VERSION ""

NS_ :

BS_:

BU_: Vector__XXX

BO_ 2566759934 DC2: 8 Vector__XXX
SG_ LockStatusOfDoor1 : 0|2@1+ (1,0) [0|3] "" Vector__XXX
SG_ OpenStatusOfDoor1 : 2|2@1+ (1,0) [0|3] "" Vector__XXX
SG_ EnableStatusOfDoor1 : 4|2@1+ (1,0) [0|3] "" Vector__XXX
SG_ LockStatusOfDoor2 : 6|2@1+ (1,0) [0|3] "" Vector__XXX
SG_ OpenStatusOfDoor2 : 8|2@1+ (1,0) [0|3] "" Vector__XXX
SG_ EnableStatusOfDoor2 : 10|2@1+ (1,0) [0|3] "" Vector__XXX
SG_ LockStatusOfDoor3 : 12|2@1+ (1,0) [0|3] "" Vector__XXX
SG_ OpenStatusOfDoor3 : 14|2@1+ (1,0) [0|3] "" Vector__XXX
SG_ EnableStatusOfDoor3 : 16|2@1+ (1,0) [0|3] "" Vector__XXX
SG_ LockStatusOfDoor4 : 18|2@1+ (1,0) [0|3] "" Vector__XXX
SG_ OpenStatusOfDoor4 : 20|2@1+ (1,0) [0|3] "" Vector__XXX
SG_ EnableStatusOfDoor4 : 22|2@1+ (1,0) [0|3] "" Vector__XXX
SG_ LockStatusOfDoor5 : 24|2@1+ (1,0) [0|3] "" Vector__XXX
SG_ OpenStatusOfDoor5 : 26|2@1+ (1,0) [0|3] "" Vector__XXX
SG_ EnableStatusOfDoor5 : 28|2@1+ (1,0) [0|3] "" Vector__XXX
SG_ LockStatusOfDoor6 : 30|2@1+ (1,0) [0|3] "" Vector__XXX
SG_ OpenStatusOfDoor6 : 32|2@1+ (1,0) [0|3] "" Vector__XXX
SG_ EnableStatusOfDoor6 : 34|2@1+ (1,0) [0|3] "" Vector__XXX
SG_ LockStatusOfDoor7 : 36|2@1+ (1,0) [0|3] "" Vector__XXX
SG_ OpenStatusOfDoor7 : 38|2@1+ (1,0) [0|3] "" Vector__XXX
SG_ EnableStatusOfDoor7 : 40|2@1+ (1,0) [0|3] "" Vector__XXX
SG_ LockStatusOfDoor8 : 42|2@1+ (1,0) [0|3] "" Vector__XXX
SG_ OpenStatusOfDoor8 : 44|2@1+ (1,0) [0|3] "" Vector__XXX
SG_ EnableStatusOfDoor8 : 46|2@1+ (1,0) [0|3] "" Vector__XXX
SG_ LockStatusOfDoor9 : 48|2@1+ (1,0) [0|3] "" Vector__XXX
SG_ OpenStatusOfDoor9 : 50|2@1+ (1,0) [0|3] "" Vector__XXX
SG_ EnableStatusOfDoor9 : 52|2@1+ (1,0) [0|3] "" Vector__XXX
SG_ LockStatusOfDoor10 : 54|2@1+ (1,0) [0|3] "" Vector__XXX
SG_ OpenStatusOfDoor10 : 56|2@1+ (1,0) [0|3] "" Vector__XXX
SG_ EnableStatusOfDoor10 : 58|2@1+ (1,0) [0|3] "" Vector__XXX

BO_ 2365433598 VREP: 8 Vector__XXX
SG_ GeneratorExcitationFieldVoltage : 0|16@1+ (0.05,-1606) [-1606|1606.75] "V" Vector__XXX
SG_ GeneratorExcitationFieldCurrent : 16|16@1+ (0.05,0) [0|3212.75] "A" Vector__XXX
SG_ GenOutputVoltageBiasPercentage : 32|16@1+ (0.1,-100) [-100|100] "%" Vector__XXX

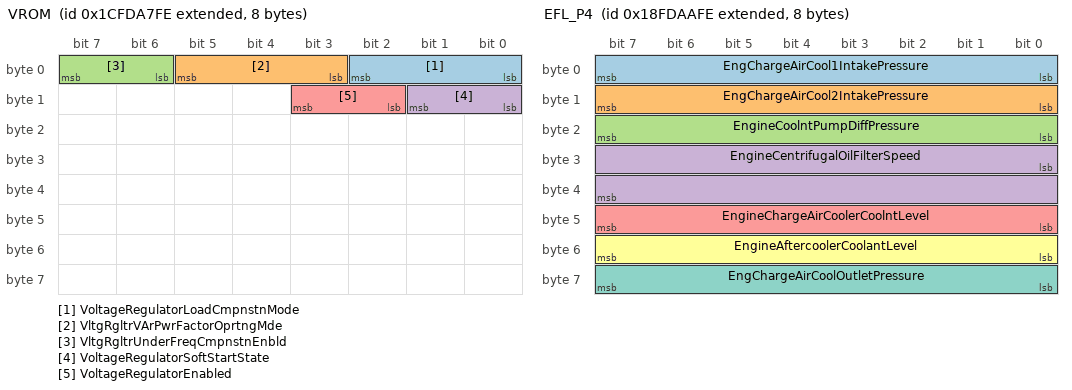
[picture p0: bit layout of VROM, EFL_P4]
BO_ 2633869310 VROM: 8 Vector__XXX
SG_ VoltageRegulatorLoadCmpnstnMode : 0|3@1+ (1,0) [0|7] "" Vector__XXX
SG_ VltgRgltrVArPwrFactorOprtngMde : 3|3@1+ (1,0) [0|7] "" Vector__XXX
SG_ VltgRgltrUnderFreqCmpnstnEnbld : 6|2@1+ (1,0) [0|3] "" Vector__XXX
SG_ VoltageRegulatorSoftStartState : 8|2@1+ (1,0) [0|3] "" Vector__XXX
SG_ VoltageRegulatorEnabled : 10|2@1+ (1,0) [0|3] "" Vector__XXX

BO_ 2566760702 WCM2: 8 Vector__XXX
SG_ NetworkTransceiverStatus2 : 0|8@1+ (1,0) [0|255] "" Vector__XXX
SG_ NetworkServiceStatus2 : 8|8@1+ (1,0) [0|255] "" Vector__XXX
SG_ NetworkAntennaStatus2 : 16|8@1+ (1,0) [0|255] "" Vector__XXX
SG_ NetworkSignalStrength2 : 24|8@1+ (0.4,0) [0|100] "%" Vector__XXX
SG_ WirelessCommNetworkType2 : 32|8@1+ (1,0) [0|255] "" Vector__XXX

BO_ 2566760958 WCM1: 8 Vector__XXX
SG_ NetworkTransceiverStatus1 : 0|8@1+ (1,0) [0|255] "" Vector__XXX
SG_ NetworkServiceStatus1 : 8|8@1+ (1,0) [0|255] "" Vector__XXX
SG_ NetworkAntennaStatus1 : 16|8@1+ (1,0) [0|255] "" Vector__XXX
SG_ NetworkSignalStrength1 : 24|8@1+ (0.4,0) [0|100] "%" Vector__XXX
SG_ WirelessCommNetworkType1 : 32|8@1+ (1,0) [0|255] "" Vector__XXX

BO_ 2566761214 EFL_P4: 8 Vector__XXX
SG_ EngChargeAirCool1IntakePressure : 0|8@1+ (2,0) [0|500] "kPa" Vector__XXX
SG_ EngChargeAirCool2IntakePressure : 8|8@1+ (2,0) [0|500] "kPa" Vector__XXX
SG_ EngineCoolntPumpDiffPressure : 16|8@1+ (1.64,-7) [-7|403] "kPa" Vector__XXX
SG_ EngineCentrifugalOilFilterSpeed : 24|16@1+ (4,0) [0|257020] "rpm" Vector__XXX
SG_ EngineChargeAirCoolerCoolntLevel : 40|8@1+ (0.4,0) [0|100] "%" Vector__XXX
SG_ EngineAftercoolerCoolantLevel : 48|8@1+ (0.4,0) [0|100] "%" Vector__XXX
SG_ EngChargeAirCoolOutletPressure : 56|8@1+ (2,0) [0|500] "kPa" Vector__XXX

BO_ 2566761726 EFI: 8 Vector__XXX
SG_ NoFuelCnsmptnMontingTransducers : 0|8@1+ (1,0) [0|250] "" Vector__XXX
SG_ EngineIdleFuelFlowRateThreshold : 8|32@1+ (0.001,0) [0|4211081.215] "l/h" Vector__XXX

BO_ 2566761982 RCMS: 8 Vector__XXX
SG_ MessageSelectionControl : 0|8@1+ (1,0) [0|250] "" Vector__XXX
SG_ PGNOfConfigurableMessageDesired : 8|24@1+ (1,0) [0|16777215] "" Vector__XXX

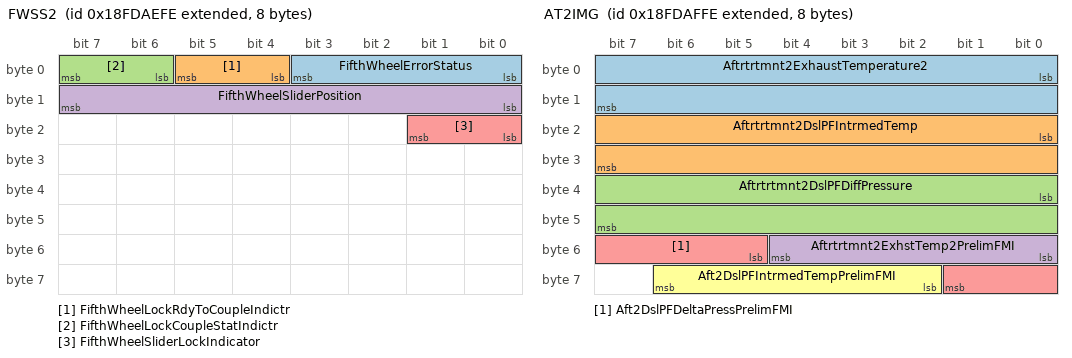
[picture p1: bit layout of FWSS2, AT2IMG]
BO_ 2566762238 FWSS2: 8 Vector__XXX
SG_ FifthWheelErrorStatus : 0|4@1+ (1,0) [0|15] "" Vector__XXX
SG_ FifthWheelLockRdyToCoupleIndictr : 4|2@1+ (1,0) [0|3] "" Vector__XXX
SG_ FifthWheelLockCoupleStatIndictr : 6|2@1+ (1,0) [0|3] "" Vector__XXX
SG_ FifthWheelSliderPosition : 8|8@1+ (10,0) [0|2500] "mm" Vector__XXX
SG_ FifthWheelSliderLockIndicator : 16|2@1+ (1,0) [0|3] "" Vector__XXX

BO_ 2566762494 AT2IMG: 8 Vector__XXX
SG_ Aftrtrtmnt2ExhaustTemperature2 : 0|16@1+ (0.03125,-273) [-273|1734.96875] "deg C" Vector__XXX
SG_ Aftrtrtmnt2DslPFIntrmedTemp : 16|16@1+ (0.03125,-273) [-273|1734.96875] "deg C" Vector__XXX
SG_ Aftrtrtmnt2DslPFDiffPressure : 32|16@1+ (0.1,0) [0|6425.5] "kPa" Vector__XXX
SG_ Aftrtrtmnt2ExhstTemp2PrelimFMI : 48|5@1+ (1,0) [0|31] "" Vector__XXX
SG_ Aft2DslPFDeltaPressPrelimFMI : 53|5@1+ (1,0) [0|31] "" Vector__XXX
SG_ Aft2DslPFIntrmedTempPrelimFMI : 58|5@1+ (1,0) [0|31] "" Vector__XXX

BO_ 2566762750 AT2OG2: 8 Vector__XXX
SG_ Aftrtrtmnt2ExhaustTemperature3 : 0|16@1+ (0.03125,-273) [-273|1734.96875] "deg C" Vector__XXX
SG_ Aftrtrtmnt2DslPFOtltTemperature : 16|16@1+ (0.03125,-273) [-273|1734.96875] "deg C" Vector__XXX
SG_ Aftrtrtmnt2ExhstTemp3PrelimFMI : 32|5@1+ (1,0) [0|31] "" Vector__XXX
SG_ Aft2DslPFExhstTempPrelimFMI : 40|5@1+ (1,0) [0|31] "" Vector__XXX

BO_ 2566763006 AT2IG2: 8 Vector__XXX
SG_ Aftrtrtmnt2ExhaustTemperature1 : 0|16@1+ (0.03125,-273) [-273|1734.96875] "deg C" Vector__XXX
SG_ Aftrtrtmnt2DslPFIntkTemperature : 16|16@1+ (0.03125,-273) [-273|1734.96875] "deg C" Vector__XXX
SG_ Aftrtrtmnt2ExhstTemp1PrelimFMI : 32|5@1+ (1,0) [0|31] "" Vector__XXX
SG_ Aft2DslPFIntkTempPrelimFMI : 40|5@1+ (1,0) [0|31] "" Vector__XXX

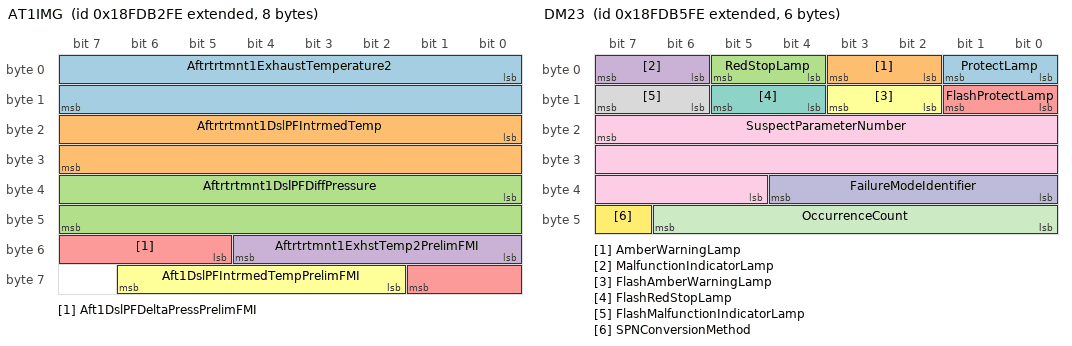
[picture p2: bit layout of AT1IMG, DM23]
BO_ 2566763262 AT1IMG: 8 Vector__XXX
SG_ Aftrtrtmnt1ExhaustTemperature2 : 0|16@1+ (0.03125,-273) [-273|1734.96875] "deg C" Vector__XXX
SG_ Aftrtrtmnt1DslPFIntrmedTemp : 16|16@1+ (0.03125,-273) [-273|1734.96875] "deg C" Vector__XXX
SG_ Aftrtrtmnt1DslPFDiffPressure : 32|16@1+ (0.1,0) [0|6425.5] "kPa" Vector__XXX
SG_ Aftrtrtmnt1ExhstTemp2PrelimFMI : 48|5@1+ (1,0) [0|31] "" Vector__XXX
SG_ Aft1DslPFDeltaPressPrelimFMI : 53|5@1+ (1,0) [0|31] "" Vector__XXX
SG_ Aft1DslPFIntrmedTempPrelimFMI : 58|5@1+ (1,0) [0|31] "" Vector__XXX

BO_ 2566763518 AT1OG2: 8 Vector__XXX
SG_ Aftrtrtmnt1ExhaustTemperature3 : 0|16@1+ (0.03125,-273) [-273|1734.96875] "deg C" Vector__XXX
SG_ Aftrtrtmnt1DslPFOtltTemperature : 16|16@1+ (0.03125,-273) [-273|1734.96875] "deg C" Vector__XXX
SG_ Aftrtrtmnt1ExhstTemp3PrelimFMI : 32|5@1+ (1,0) [0|31] "" Vector__XXX
SG_ Aft1DslPFOtltExhstTempPrelimFMI : 40|5@1+ (1,0) [0|31] "" Vector__XXX

BO_ 2566763774 AT1IG2: 8 Vector__XXX
SG_ Aftrtrtmnt1ExhaustTemperature1 : 0|16@1+ (0.03125,-273) [-273|1734.96875] "deg C" Vector__XXX
SG_ Aftrtrtmnt1DslPFIntkTemperature : 16|16@1+ (0.03125,-273) [-273|1734.96875] "deg C" Vector__XXX
SG_ Aftrtrtmnt1ExhstTemp1PrelimFMI : 32|5@1+ (1,0) [0|31] "" Vector__XXX
SG_ Aft1DslPFIntkTempPrelimFMI : 40|5@1+ (1,0) [0|31] "" Vector__XXX

BO_ 2566764030 DM23: 6 Vector__XXX
SG_ ProtectLamp : 0|2@1+ (1,0) [0|3] "" Vector__XXX
SG_ AmberWarningLamp : 2|2@1+ (1,0) [0|3] "" Vector__XXX
SG_ RedStopLamp : 4|2@1+ (1,0) [0|3] "" Vector__XXX
SG_ MalfunctionIndicatorLamp : 6|2@1+ (1,0) [0|3] "" Vector__XXX
SG_ FlashProtectLamp : 8|2@1+ (1,0) [0|3] "" Vector__XXX
SG_ FlashAmberWarningLamp : 10|2@1+ (1,0) [0|3] "" Vector__XXX
SG_ FlashRedStopLamp : 12|2@1+ (1,0) [0|3] "" Vector__XXX
SG_ FlashMalfunctionIndicatorLamp : 14|2@1+ (1,0) [0|3] "" Vector__XXX
SG_ SuspectParameterNumber : 23|19@0+ (1,0) [0|524287] "" Vector__XXX
SG_ FailureModeIdentifier : 32|5@1+ (1,0) [0|31] "" Vector__XXX
SG_ OccurrenceCount : 40|7@1+ (1,0) [0|127] "" Vector__XXX
SG_ SPNConversionMethod : 47|1@1+ (1,0) [0|1] "" Vector__XXX

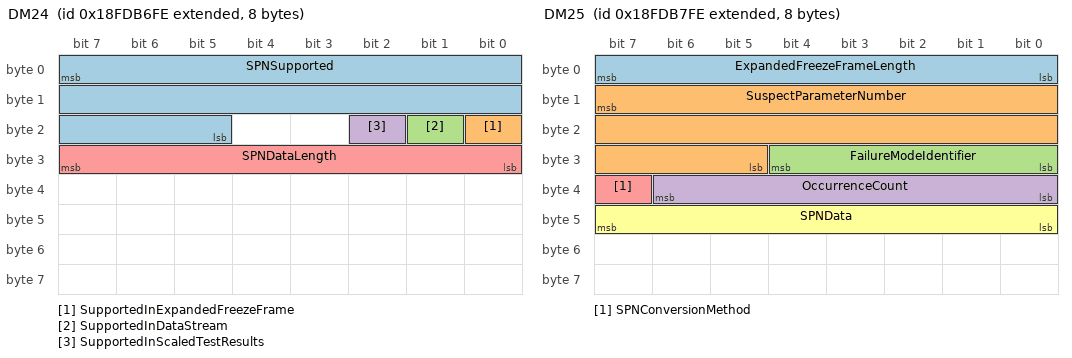
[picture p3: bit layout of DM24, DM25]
BO_ 2566764286 DM24: 8 Vector__XXX
SG_ SPNSupported : 7|19@0+ (1,0) [0|524287] "" Vector__XXX
SG_ SupportedInExpandedFreezeFrame : 16|1@1+ (1,0) [0|1] "" Vector__XXX
SG_ SupportedInDataStream : 17|1@1+ (1,0) [0|1] "" Vector__XXX
SG_ SupportedInScaledTestResults : 18|1@1+ (1,0) [0|1] "" Vector__XXX
SG_ SPNDataLength : 24|8@1+ (1,0) [0|250] "" Vector__XXX

BO_ 2566764542 DM25: 8 Vector__XXX
SG_ ExpandedFreezeFrameLength : 0|8@1+ (1,0) [0|255] "" Vector__XXX
SG_ SuspectParameterNumber : 15|19@0+ (1,0) [0|524287] "" Vector__XXX
SG_ FailureModeIdentifier : 24|5@1+ (1,0) [0|31] "" Vector__XXX
SG_ OccurrenceCount : 32|7@1+ (1,0) [0|127] "" Vector__XXX
SG_ SPNConversionMethod : 39|1@1+ (1,0) [0|1] "" Vector__XXX
SG_ SPNData : 40|8@1+ (1,0) [0|255] "" Vector__XXX

BO_ 2566764798 DM26: 8 Vector__XXX
SG_ TimeSinceEngineStart : 0|16@1+ (1,0) [0|64255] "s" Vector__XXX
SG_ NoWarmUpsSncDiagTroubleCodesClrd : 16|8@1+ (1,0) [0|250] "" Vector__XXX
SG_ CntinlyMontrdSysEnbldCmpltdStat : 24|8@1+ (1,0) [0|255] "" Vector__XXX
SG_ NonCntinlyMontrdSystemsEnbldStat : 32|16@1+ (1,0) [0|65535] "" Vector__XXX
SG_ NonCntinlyMontrdSysCompleteStat : 48|16@1+ (1,0) [0|65535] "" Vector__XXX

BO_ 2566765054 TPRI: 8 Vector__XXX
SG_ TireLocation : 0|8@1+ (1,0) [0|255] "" Vector__XXX
SG_ ReferenceTirePressure : 8|8@1+ (8,0) [0|2000] "kPa" Vector__XXX

BO_ 2566765310 TR6: 8 Vector__XXX
SG_ FareboxEmergencyStatus : 0|2@1+ (1,0) [0|3] "" Vector__XXX
SG_ FareboxAlarmIdentifier : 8|7@1+ (1,0) [0|127] "" Vector__XXX

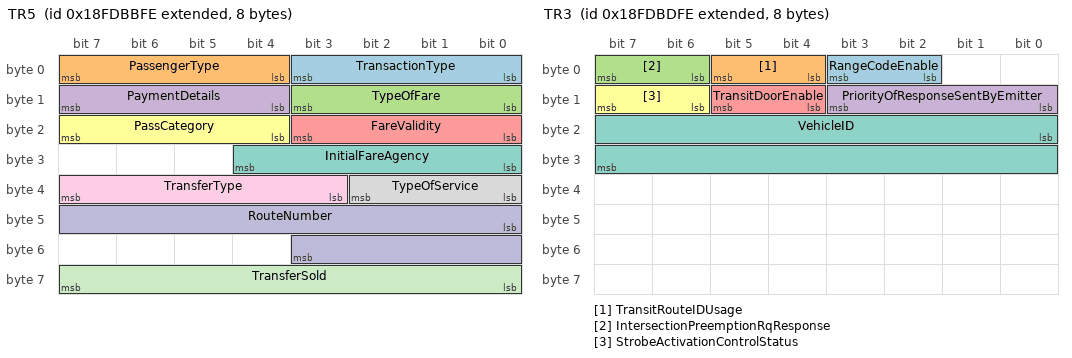
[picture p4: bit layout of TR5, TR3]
BO_ 2566765566 TR5: 8 Vector__XXX
SG_ TransactionType : 0|4@1+ (1,0) [0|15] "" Vector__XXX
SG_ PassengerType : 4|4@1+ (1,0) [0|15] "" Vector__XXX
SG_ TypeOfFare : 8|4@1+ (1,0) [0|15] "" Vector__XXX
SG_ PaymentDetails : 12|4@1+ (1,0) [0|15] "" Vector__XXX
SG_ FareValidity : 16|4@1+ (1,0) [0|15] "" Vector__XXX
SG_ PassCategory : 20|4@1+ (1,0) [0|15] "" Vector__XXX
SG_ InitialFareAgency : 24|5@1+ (1,0) [0|31] "" Vector__XXX
SG_ TypeOfService : 32|3@1+ (1,0) [0|7] "" Vector__XXX
SG_ TransferType : 35|5@1+ (1,0) [0|31] "" Vector__XXX
SG_ RouteNumber : 40|12@1+ (1,0) [0|4095] "" Vector__XXX
SG_ TransferSold : 56|8@1+ (1,0) [0|255] "" Vector__XXX

BO_ 2566765822 TR4: 15 Vector__XXX
SG_ FareboxServiceStatus : 0|2@1+ (1,0) [0|3] "" Vector__XXX
SG_ TripStatus : 2|3@1+ (1,0) [0|7] "" Vector__XXX
SG_ TripDirection : 8|4@1+ (1,0) [0|15] "" Vector__XXX
SG_ FarePresets : 16|8@1+ (1,0) [0|255] "" Vector__XXX
SG_ TripNumber : 24|16@1+ (1,0) [0|65535] "" Vector__XXX
SG_ PatternNumber : 40|16@1+ (1,0) [0|65535] "" Vector__XXX
SG_ AssignedRoute : 56|16@1+ (1,0) [0|65535] "" Vector__XXX
SG_ AssignedRun : 72|16@1+ (1,0) [0|65535] "" Vector__XXX
SG_ AssignedBlock : 88|16@1+ (1,0) [0|65535] "" Vector__XXX
SG_ DriversFareboxSecurityCode : 104|16@1+ (1,0) [0|65535] "" Vector__XXX

BO_ 2566766078 TR3: 8 Vector__XXX
SG_ RangeCodeEnable : 2|2@1+ (1,0) [0|3] "" Vector__XXX
SG_ TransitRouteIDUsage : 4|2@1+ (1,0) [0|3] "" Vector__XXX
SG_ IntersectionPreemptionRqResponse : 6|2@1+ (1,0) [0|3] "" Vector__XXX
SG_ PriorityOfResponseSentByEmitter : 8|4@1+ (1,0) [0|15] "" Vector__XXX
SG_ TransitDoorEnable : 12|2@1+ (1,0) [0|3] "" Vector__XXX
SG_ StrobeActivationControlStatus : 14|2@1+ (1,0) [0|3] "" Vector__XXX
SG_ VehicleID : 16|16@1+ (1,0) [0|65535] "" Vector__XXX

BO_ 2566766334 TR1: 8 Vector__XXX
SG_ Agency : 0|8@1+ (1,0) [0|255] "" Vector__XXX
SG_ NoOfBytsInTrnstAssgndRteIdntty : 8|8@1+ (1,0) [0|250] "Bytes" Vector__XXX
SG_ NoOfBytsInTrnstAssgndRunIdntty : 16|8@1+ (1,0) [0|250] "Bytes" Vector__XXX
SG_ NoOfBytsInTrnstAssgndBlckIdntty : 24|8@1+ (1,0) [0|250] "Bytes" Vector__XXX

BO_ 2566766590 TR2: 100 Vector__XXX
SG_ NoOfBytsInMilePstIdentification : 0|8@1+ (1,0) [0|250] "Bytes" Vector__XXX
SG_ MilepostIdentification : 7|800@0+ (1,0) [0|0] "ASCII" Vector__XXX

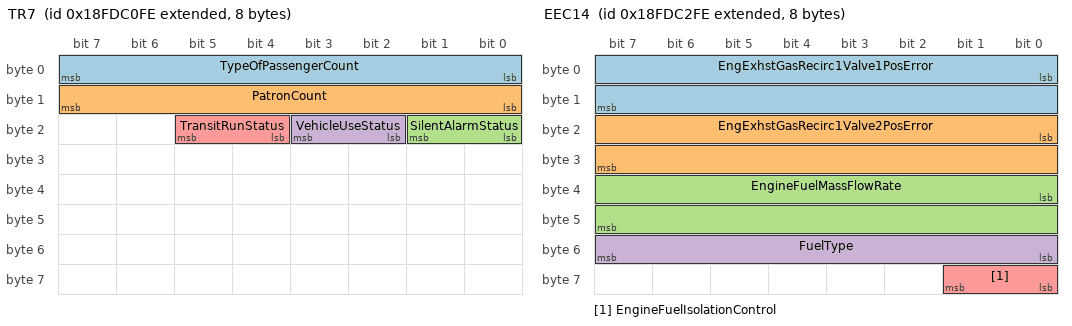
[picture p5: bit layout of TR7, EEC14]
BO_ 2566766846 TR7: 8 Vector__XXX
SG_ TypeOfPassengerCount : 0|8@1+ (1,0) [0|255] "" Vector__XXX
SG_ PatronCount : 8|8@1+ (1,0) [0|250] "" Vector__XXX
SG_ SilentAlarmStatus : 16|2@1+ (1,0) [0|3] "" Vector__XXX
SG_ VehicleUseStatus : 18|2@1+ (1,0) [0|3] "" Vector__XXX
SG_ TransitRunStatus : 20|2@1+ (1,0) [0|3] "" Vector__XXX

BO_ 2566767102 EFL_P3: 8 Vector__XXX
SG_ EngIntkValveActSystemOilPressure : 0|16@1+ (0.00390625,0) [0|250.996] "MPa" Vector__XXX
SG_ EngExhstGasRecirc1IntkPress : 16|8@1+ (2,0) [0|500] "kPa" Vector__XXX
SG_ EngExhstValveActSystemOilPress : 24|16@1+ (0.00390625,0) [0|250.996] "MPa" Vector__XXX
SG_ EngExhstGasRecirc1OtltPress : 40|8@1+ (2,0) [0|500] "kPa" Vector__XXX
SG_ EngineThrottleValve1DiffPressure : 48|16@1+ (0.1,0) [0|6425.5] "kPa" Vector__XXX

BO_ 2566767358 EEC14: 8 Vector__XXX
SG_ EngExhstGasRecirc1Valve1PosError : 0|16@1+ (0.004,-125) [-125|132.02] "%" Vector__XXX
SG_ EngExhstGasRecirc1Valve2PosError : 16|16@1+ (0.004,-125) [-125|132.02] "%" Vector__XXX
SG_ EngineFuelMassFlowRate : 32|16@1+ (0.005,0) [0|321.275] "g/s" Vector__XXX
SG_ FuelType : 48|8@1+ (1,0) [0|255] "" Vector__XXX
SG_ EngineFuelIsolationControl : 56|2@1+ (1,0) [0|3] "" Vector__XXX

BO_ 2566767614 EEC15: 8 Vector__XXX
SG_ AcceleratorPedal1Channel2 : 0|8@1+ (0.4,0) [0|100] "%" Vector__XXX
SG_ AcceleratorPedal1Channel3 : 8|8@1+ (0.4,0) [0|100] "%" Vector__XXX
SG_ AcceleratorPedal2Channel2 : 16|8@1+ (0.4,0) [0|100] "%" Vector__XXX
SG_ AcceleratorPedal2Channel3 : 24|8@1+ (0.4,0) [0|100] "%" Vector__XXX
SG_ EngExhstGasRestrictionValveCtrl : 32|16@1+ (0.0025,0) [0|160.6375] "%" Vector__XXX

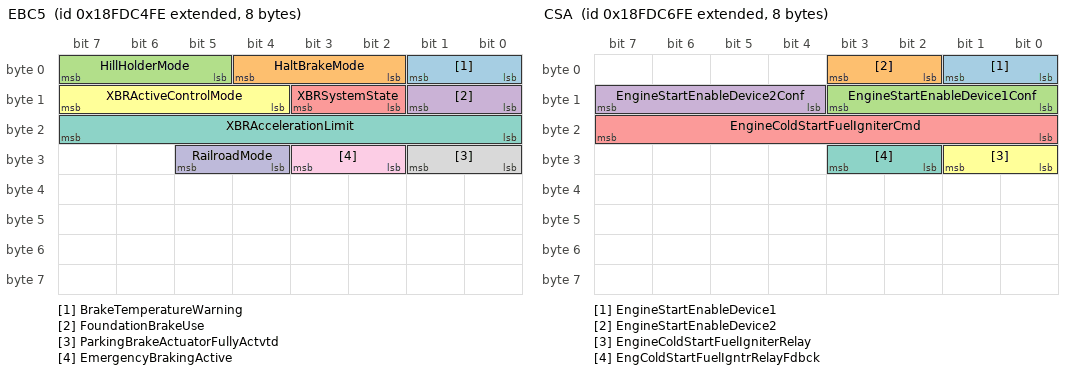
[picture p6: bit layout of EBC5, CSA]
BO_ 2566767870 EBC5: 8 Vector__XXX
SG_ BrakeTemperatureWarning : 0|2@1+ (1,0) [0|3] "" Vector__XXX
SG_ HaltBrakeMode : 2|3@1+ (1,0) [0|7] "" Vector__XXX
SG_ HillHolderMode : 5|3@1+ (1,0) [0|7] "" Vector__XXX
SG_ FoundationBrakeUse : 8|2@1+ (1,0) [0|3] "" Vector__XXX
SG_ XBRSystemState : 10|2@1+ (1,0) [0|3] "" Vector__XXX
SG_ XBRActiveControlMode : 12|4@1+ (1,0) [0|15] "" Vector__XXX
SG_ XBRAccelerationLimit : 16|8@1+ (0.1,-12.5) [-12.5|12.5] "m/s^2" Vector__XXX
SG_ ParkingBrakeActuatorFullyActvtd : 24|2@1+ (1,0) [0|3] "" Vector__XXX
SG_ EmergencyBrakingActive : 26|2@1+ (1,0) [0|3] "" Vector__XXX
SG_ RailroadMode : 28|2@1+ (1,0) [0|3] "" Vector__XXX

BO_ 2566768126 ECUID: 200 Vector__XXX
SG_ ECUHardwareID : 7|1600@0+ (1,0) [0|0] "ASCII" Vector__XXX

BO_ 2566768382 CSA: 8 Vector__XXX
SG_ EngineStartEnableDevice1 : 0|2@1+ (1,0) [0|3] "" Vector__XXX
SG_ EngineStartEnableDevice2 : 2|2@1+ (1,0) [0|3] "" Vector__XXX
SG_ EngineStartEnableDevice1Conf : 8|4@1+ (1,0) [0|15] "" Vector__XXX
SG_ EngineStartEnableDevice2Conf : 12|4@1+ (1,0) [0|15] "" Vector__XXX
SG_ EngineColdStartFuelIgniterCmd : 16|8@1+ (0.4,0) [0|100] "%" Vector__XXX
SG_ EngineColdStartFuelIgniterRelay : 24|2@1+ (1,0) [0|3] "" Vector__XXX
SG_ EngColdStartFuelIgntrRelayFdbck : 26|2@1+ (1,0) [0|3] "" Vector__XXX

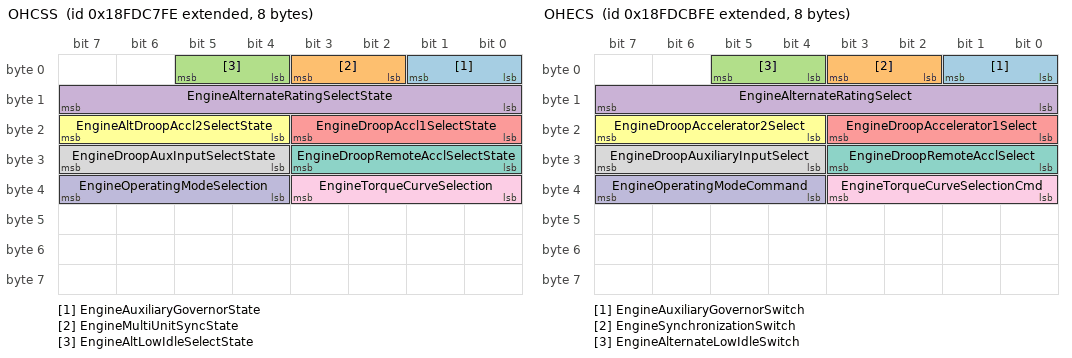
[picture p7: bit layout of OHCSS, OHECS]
BO_ 2566768638 OHCSS: 8 Vector__XXX
SG_ EngineAuxiliaryGovernorState : 0|2@1+ (1,0) [0|3] "" Vector__XXX
SG_ EngineMultiUnitSyncState : 2|2@1+ (1,0) [0|3] "" Vector__XXX
SG_ EngineAltLowIdleSelectState : 4|2@1+ (1,0) [0|3] "" Vector__XXX
SG_ EngineAlternateRatingSelectState : 8|8@1+ (1,0) [0|255] "" Vector__XXX
SG_ EngineDroopAccl1SelectState : 16|4@1+ (1,0) [0|15] "" Vector__XXX
SG_ EngineAltDroopAccl2SelectState : 20|4@1+ (1,0) [0|15] "" Vector__XXX
SG_ EngineDroopRemoteAcclSelectState : 24|4@1+ (1,0) [0|15] "" Vector__XXX
SG_ EngineDroopAuxInputSelectState : 28|4@1+ (1,0) [0|15] "" Vector__XXX
SG_ EngineTorqueCurveSelection : 32|4@1+ (1,0) [0|15] "" Vector__XXX
SG_ EngineOperatingModeSelection : 36|4@1+ (1,0) [0|15] "" Vector__XXX

BO_ 2566768894 ISCS: 8 Vector__XXX
SG_ EngOprtrPrmryIntrmedSpdSlctState : 0|4@1+ (1,0) [0|15] "" Vector__XXX

BO_ 2633878014 CMI: 8 Vector__XXX
SG_ TotalCountOfConfChangesMade : 0|16@1+ (1,0) [0|64255] "" Vector__XXX

BO_ 2566769406 ISC: 8 Vector__XXX
SG_ EngOprtrPrmryIntrmedSpeedSelect : 0|4@1+ (1,0) [0|15] "" Vector__XXX

BO_ 2566769662 OHECS: 8 Vector__XXX
SG_ EngineAuxiliaryGovernorSwitch : 0|2@1+ (1,0) [0|3] "" Vector__XXX
SG_ EngineSynchronizationSwitch : 2|2@1+ (1,0) [0|3] "" Vector__XXX
SG_ EngineAlternateLowIdleSwitch : 4|2@1+ (1,0) [0|3] "" Vector__XXX
SG_ EngineAlternateRatingSelect : 8|8@1+ (1,0) [0|255] "" Vector__XXX
SG_ EngineDroopAccelerator1Select : 16|4@1+ (1,0) [0|15] "" Vector__XXX
SG_ EngineDroopAccelerator2Select : 20|4@1+ (1,0) [0|15] "" Vector__XXX
SG_ EngineDroopRemoteAcclSelect : 24|4@1+ (1,0) [0|15] "" Vector__XXX
SG_ EngineDroopAuxiliaryInputSelect : 28|4@1+ (1,0) [0|15] "" Vector__XXX
SG_ EngineTorqueCurveSelectionCmd : 32|4@1+ (1,0) [0|15] "" Vector__XXX
SG_ EngineOperatingModeCommand : 36|4@1+ (1,0) [0|15] "" Vector__XXX

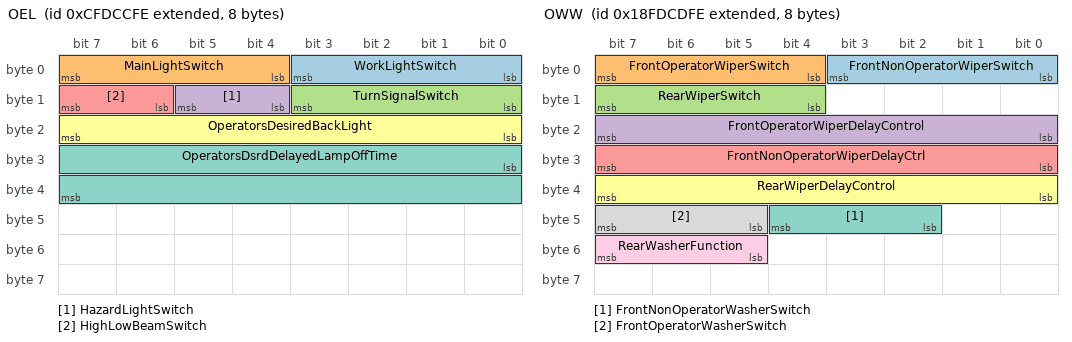
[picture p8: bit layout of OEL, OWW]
BO_ 2365443326 OEL: 8 Vector__XXX
SG_ WorkLightSwitch : 0|4@1+ (1,0) [0|15] "" Vector__XXX
SG_ MainLightSwitch : 4|4@1+ (1,0) [0|15] "" Vector__XXX
SG_ TurnSignalSwitch : 8|4@1+ (1,0) [0|15] "" Vector__XXX
SG_ HazardLightSwitch : 12|2@1+ (1,0) [0|3] "" Vector__XXX
SG_ HighLowBeamSwitch : 14|2@1+ (1,0) [0|3] "" Vector__XXX
SG_ OperatorsDesiredBackLight : 16|8@1+ (0.4,0) [0|100] "%" Vector__XXX
SG_ OperatorsDsrdDelayedLampOffTime : 24|16@1+ (1,0) [0|64255] "s" Vector__XXX

BO_ 2566770174 OWW: 8 Vector__XXX
SG_ FrontNonOperatorWiperSwitch : 0|4@1+ (1,0) [0|15] "" Vector__XXX
SG_ FrontOperatorWiperSwitch : 4|4@1+ (1,0) [0|15] "" Vector__XXX
SG_ RearWiperSwitch : 12|4@1+ (1,0) [0|15] "" Vector__XXX
SG_ FrontOperatorWiperDelayControl : 16|8@1+ (0.4,0) [0|100] "%" Vector__XXX
SG_ FrontNonOperatorWiperDelayCtrl : 24|8@1+ (0.4,0) [0|100] "%" Vector__XXX
SG_ RearWiperDelayControl : 32|8@1+ (0.4,0) [0|100] "%" Vector__XXX
SG_ FrontNonOperatorWasherSwitch : 42|3@1+ (1,0) [0|7] "" Vector__XXX
SG_ FrontOperatorWasherSwitch : 45|3@1+ (1,0) [0|7] "" Vector__XXX
SG_ RearWasherFunction : 53|3@1+ (1,0) [0|7] "" Vector__XXX

BO_ 2566770430 WSMM: 8 Vector__XXX
SG_ NAMEOfWorkingSetMember : 0|64@1+ (1,0) [0|1.84467440737096E019] "" Vector__XXX

BO_ 2566770686 WSM: 8 Vector__XXX
SG_ NumberOfMembersInWorkingSet : 0|8@1+ (1,0) [0|250] "" Vector__XXX

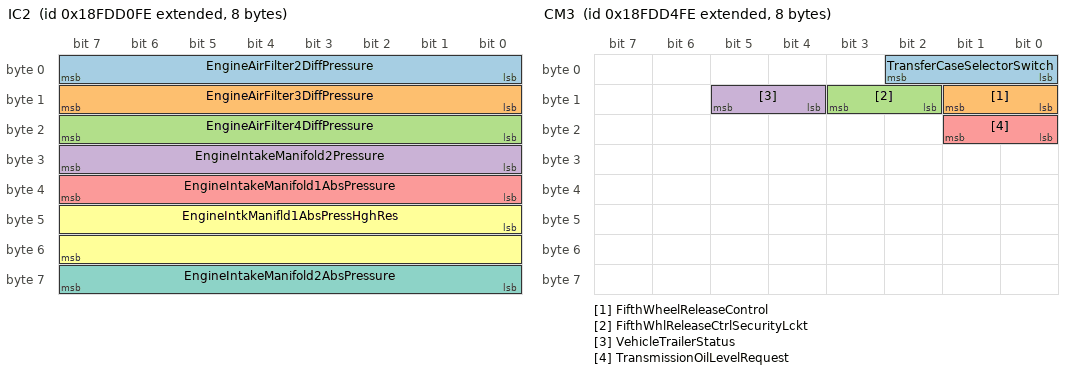
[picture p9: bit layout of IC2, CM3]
BO_ 2566770942 IC2: 8 Vector__XXX
SG_ EngineAirFilter2DiffPressure : 0|8@1+ (0.05,0) [0|12.5] "kPa" Vector__XXX
SG_ EngineAirFilter3DiffPressure : 8|8@1+ (0.05,0) [0|12.5] "kPa" Vector__XXX
SG_ EngineAirFilter4DiffPressure : 16|8@1+ (0.05,0) [0|12.5] "kPa" Vector__XXX
SG_ EngineIntakeManifold2Pressure : 24|8@1+ (2,0) [0|500] "kPa" Vector__XXX
SG_ EngineIntakeManifold1AbsPressure : 32|8@1+ (2,0) [0|500] "kPa" Vector__XXX
SG_ EngineIntkManifld1AbsPressHghRes : 40|16@1+ (0.1,0) [0|6425.5] "kPa" Vector__XXX
SG_ EngineIntakeManifold2AbsPressure : 56|8@1+ (2,0) [0|500] "kPa" Vector__XXX

BO_ 2633880062 FMS: 8 Vector__XXX
SG_ FMSStandardDiagnosticsSupported : 0|2@1+ (1,0) [0|3] "" Vector__XXX
SG_ FMSStandardRequestsSupported : 2|2@1+ (1,0) [0|3] "" Vector__XXX
SG_ FMSStandardSWVersionSupported : 15|32@0+ (1,0) [0|0] "ASCII" Vector__XXX

BO_ 2566771454 EP: 8 Vector__XXX
SG_ KeepAliveBatteryConsumption : 0|16@1+ (1,0) [0|64255] "mAh" Vector__XXX
SG_ DataMemoryUsage : 16|8@1+ (0.4,0) [0|100] "%" Vector__XXX

BO_ 2566771710 TCI6: 8 Vector__XXX
SG_ EngTurbocharger1CmprssorOtltTemp : 0|16@1+ (0.03125,-273) [-273|1734.96875] "deg C" Vector__XXX
SG_ EngTurbocharger2CmprssorOtltTemp : 16|16@1+ (0.03125,-273) [-273|1734.96875] "deg C" Vector__XXX
SG_ EngTurbocharger3CmprssorOtltTemp : 32|16@1+ (0.03125,-273) [-273|1734.96875] "deg C" Vector__XXX
SG_ EngTurbocharger4CmprssorOtltTemp : 48|16@1+ (0.03125,-273) [-273|1734.96875] "deg C" Vector__XXX

BO_ 2566771966 CM3: 8 Vector__XXX
SG_ TransferCaseSelectorSwitch : 0|3@1+ (1,0) [0|7] "" Vector__XXX
SG_ FifthWheelReleaseControl : 8|2@1+ (1,0) [0|3] "" Vector__XXX
SG_ FifthWhlReleaseCtrlSecurityLckt : 10|2@1+ (1,0) [0|3] "" Vector__XXX
SG_ VehicleTrailerStatus : 12|2@1+ (1,0) [0|3] "" Vector__XXX
SG_ TransmissionOilLevelRequest : 16|2@1+ (1,0) [0|3] "" Vector__XXX

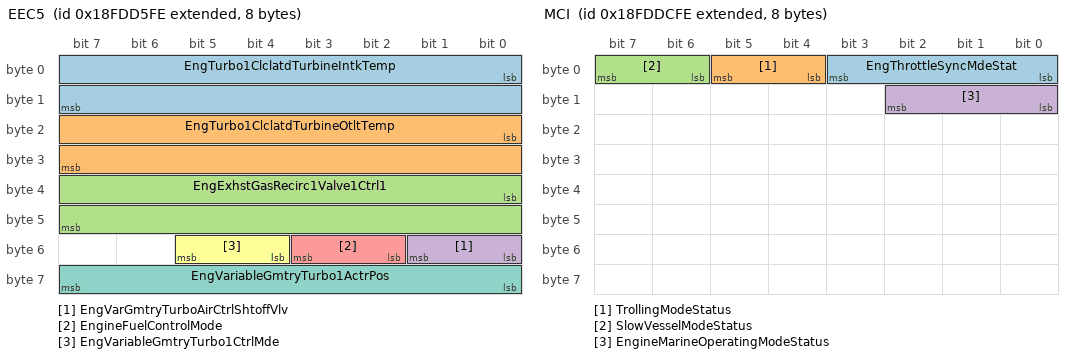
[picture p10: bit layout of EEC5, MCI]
BO_ 2566772222 EEC5: 8 Vector__XXX
SG_ EngTurbo1ClclatdTurbineIntkTemp : 0|16@1+ (0.03125,-273) [-273|1734.96875] "deg C" Vector__XXX
SG_ EngTurbo1ClclatdTurbineOtltTemp : 16|16@1+ (0.03125,-273) [-273|1734.96875] "deg C" Vector__XXX
SG_ EngExhstGasRecirc1Valve1Ctrl1 : 32|16@1+ (0.0025,0) [0|160.6375] "%" Vector__XXX
SG_ EngVarGmtryTurboAirCtrlShtoffVlv : 48|2@1+ (1,0) [0|3] "" Vector__XXX
SG_ EngineFuelControlMode : 50|2@1+ (1,0) [0|3] "" Vector__XXX
SG_ EngVariableGmtryTurbo1CtrlMde : 52|2@1+ (1,0) [0|3] "" Vector__XXX
SG_ EngVariableGmtryTurbo1ActrPos : 56|8@1+ (0.4,0) [0|100] "%" Vector__XXX

BO_ 2365445886 BJM1: 8 Vector__XXX
SG_ Jystck1XAxsNeutralPositionStatus : 0|2@1+ (1,0) [0|3] "" Vector__XXX
SG_ Jystck1XAxsLvrLftNegPosStatus : 2|2@1+ (1,0) [0|3] "" Vector__XXX
SG_ Jystck1XAxsLvrRightPstvPosStatus : 4|2@1+ (1,0) [0|3] "" Vector__XXX
SG_ Joystick1XAxisPosition : 6|10@1+ (0.1,0) [0|102] "%" Vector__XXX
SG_ Jystck1YAxsNeutralPositionStatus : 16|2@1+ (1,0) [0|3] "" Vector__XXX
SG_ Jystck1YAxsLvrBackNegPosStatus : 18|2@1+ (1,0) [0|3] "" Vector__XXX
SG_ Jystck1YAxsLvrFrwdPstvPosStatus : 20|2@1+ (1,0) [0|3] "" Vector__XXX
SG_ Joystick1YAxisPosition : 22|10@1+ (0.1,0) [0|102] "%" Vector__XXX
SG_ Jystck1YAxsDetentPositionStatus : 36|2@1+ (1,0) [0|3] "" Vector__XXX
SG_ Jystck1XAxsDetentPositionStatus : 38|2@1+ (1,0) [0|3] "" Vector__XXX
SG_ Joystick1Button4PressedStatus : 40|2@1+ (1,0) [0|3] "" Vector__XXX
SG_ Joystick1Button3PressedStatus : 42|2@1+ (1,0) [0|3] "" Vector__XXX
SG_ Joystick1Button2PressedStatus : 44|2@1+ (1,0) [0|3] "" Vector__XXX
SG_ Joystick1Button1PressedStatus : 46|2@1+ (1,0) [0|3] "" Vector__XXX
SG_ Joystick1Button8PressedStatus : 48|2@1+ (1,0) [0|3] "" Vector__XXX
SG_ Joystick1Button7PressedStatus : 50|2@1+ (1,0) [0|3] "" Vector__XXX
SG_ Joystick1Button6PressedStatus : 52|2@1+ (1,0) [0|3] "" Vector__XXX
SG_ Joystick1Button5PressedStatus : 54|2@1+ (1,0) [0|3] "" Vector__XXX
SG_ Joystick1Button12PressedStatus : 56|2@1+ (1,0) [0|3] "" Vector__XXX
SG_ Joystick1Button11PressedStatus : 58|2@1+ (1,0) [0|3] "" Vector__XXX
SG_ Joystick1Button10PressedStatus : 60|2@1+ (1,0) [0|3] "" Vector__XXX
SG_ Joystick1Button9PressedStatus : 62|2@1+ (1,0) [0|3] "" Vector__XXX

BO_ 2365446142 EJM1: 8 Vector__XXX
SG_ Jystck1GrpXAxsNtrlPositionStatus : 0|2@1+ (1,0) [0|3] "" Vector__XXX
SG_ Jystck1GrpXAxsLvrLftNegPosStatus : 2|2@1+ (1,0) [0|3] "" Vector__XXX
SG_ Jystck1GrpXAxsLvrRghtPstvPosStat : 4|2@1+ (1,0) [0|3] "" Vector__XXX
SG_ Joystick1GripXAxisPosition : 6|10@1+ (0.1,0) [0|102] "%" Vector__XXX
SG_ Jystck1GrpYAxsNtrlPositionStatus : 16|2@1+ (1,0) [0|3] "" Vector__XXX
SG_ Jystck1GrpYAxsLvrBackNegPosStat : 18|2@1+ (1,0) [0|3] "" Vector__XXX
SG_ Jystck1GrpYAxsLvrFrwdPstvPosStat : 20|2@1+ (1,0) [0|3] "" Vector__XXX
SG_ Joystick1GripYAxisPosition : 22|10@1+ (0.1,0) [0|102] "%" Vector__XXX
SG_ Jystck1ThetaAxsNtrlPosStatus : 32|2@1+ (1,0) [0|3] "" Vector__XXX
SG_ Jystck1ThtAxsCntrClckwsNegPsStat : 34|2@1+ (1,0) [0|3] "" Vector__XXX
SG_ Jystck1ThetaAxsClckwsPstvPosStat : 36|2@1+ (1,0) [0|3] "" Vector__XXX
SG_ Joystick1ThetaAxisPosition : 38|10@1+ (0.1,0) [0|102] "%" Vector__XXX
SG_ Jystck1ThetaAxsDetentPosStatus : 50|2@1+ (1,0) [0|3] "" Vector__XXX
SG_ Jystck1GrpYAxsDetentPosStatus : 52|2@1+ (1,0) [0|3] "" Vector__XXX
SG_ Jystck1GrpXAxsDetentPosStatus : 54|2@1+ (1,0) [0|3] "" Vector__XXX
SG_ Joystick1Button16PressedStatus : 56|2@1+ (1,0) [0|3] "" Vector__XXX
SG_ Joystick1Button15PressedStatus : 58|2@1+ (1,0) [0|3] "" Vector__XXX
SG_ Joystick1Button14PressedStatus : 60|2@1+ (1,0) [0|3] "" Vector__XXX
SG_ Joystick1Button13PressedStatus : 62|2@1+ (1,0) [0|3] "" Vector__XXX

BO_ 2365446398 BJM2: 8 Vector__XXX
SG_ Jystck2XAxsNeutralPositionStatus : 0|2@1+ (1,0) [0|3] "" Vector__XXX
SG_ Jystck2XAxsLvrLftNegPosStatus : 2|2@1+ (1,0) [0|3] "" Vector__XXX
SG_ Jystck2XAxsLvrRightPstvPosStatus : 4|2@1+ (1,0) [0|3] "" Vector__XXX
SG_ Joystick2XAxisPosition : 6|10@1+ (0.1,0) [0|102] "%" Vector__XXX
SG_ Jystck2YAxsNeutralPositionStatus : 16|2@1+ (1,0) [0|3] "" Vector__XXX
SG_ Jystck2YAxsLvrBackNegPosStatus : 18|2@1+ (1,0) [0|3] "" Vector__XXX
SG_ Jystck2YAxsLvrFrwdPstvPosStatus : 20|2@1+ (1,0) [0|3] "" Vector__XXX
SG_ Joystick2YAxisPosition : 22|10@1+ (0.1,0) [0|102] "%" Vector__XXX
SG_ Jystck2YAxsDetentPositionStatus : 36|2@1+ (1,0) [0|3] "" Vector__XXX
SG_ Jystck2XAxsDetentPositionStatus : 38|2@1+ (1,0) [0|3] "" Vector__XXX
SG_ Joystick2Button4PressedStatus : 40|2@1+ (1,0) [0|3] "" Vector__XXX
SG_ Joystick2Button3PressedStatus : 42|2@1+ (1,0) [0|3] "" Vector__XXX
SG_ Joystick2Button2PressedStatus : 44|2@1+ (1,0) [0|3] "" Vector__XXX
SG_ Joystick2Button1PressedStatus : 46|2@1+ (1,0) [0|3] "" Vector__XXX
SG_ Joystick2Button8PressedStatus : 48|2@1+ (1,0) [0|3] "" Vector__XXX
SG_ Joystick2Button7PressedStatus : 50|2@1+ (1,0) [0|3] "" Vector__XXX
SG_ Joystick2Button6PressedStatus : 52|2@1+ (1,0) [0|3] "" Vector__XXX
SG_ Joystick2Button5PressedStatus : 54|2@1+ (1,0) [0|3] "" Vector__XXX
SG_ Joystick2Button12PressedStatus : 56|2@1+ (1,0) [0|3] "" Vector__XXX
SG_ Joystick2Button11PressedStatus : 58|2@1+ (1,0) [0|3] "" Vector__XXX
SG_ Joystick2Button10PressedStatus : 60|2@1+ (1,0) [0|3] "" Vector__XXX
SG_ Joystick2Button9PressedStatus : 62|2@1+ (1,0) [0|3] "" Vector__XXX

BO_ 2365446654 EJM2: 8 Vector__XXX
SG_ Jystck2GrpXAxsNtrlPositionStatus : 0|2@1+ (1,0) [0|3] "" Vector__XXX
SG_ Jystck2GrpXAxsLvrLftNegPosStatus : 2|2@1+ (1,0) [0|3] "" Vector__XXX
SG_ Jystck2GrpXAxsLvrRghtPstvPosStat : 4|2@1+ (1,0) [0|3] "" Vector__XXX
SG_ Joystick2GripXAxisPosition : 6|10@1+ (0.1,0) [0|102] "%" Vector__XXX
SG_ Jystck2GrpYAxsNtrlPositionStatus : 16|2@1+ (1,0) [0|3] "" Vector__XXX
SG_ Jystck2GrpYAxsLvrBackNegPosStat : 18|2@1+ (1,0) [0|3] "" Vector__XXX
SG_ Jystck2GrpYAxsLvrFrwdPstvPosStat : 20|2@1+ (1,0) [0|3] "" Vector__XXX
SG_ Joystick2GripYAxisPosition : 22|10@1+ (0.1,0) [0|102] "%" Vector__XXX
SG_ Jystck2ThetaAxsNtrlPosStatus : 32|2@1+ (1,0) [0|3] "" Vector__XXX
SG_ Jystck2ThtAxsCntrClckwsNegPsStat : 34|2@1+ (1,0) [0|3] "" Vector__XXX
SG_ Jystck2ThetaAxsClckwsPstvPosStat : 36|2@1+ (1,0) [0|3] "" Vector__XXX
SG_ Joystick2ThetaAxisPosition : 38|10@1+ (0.1,0) [0|102] "%" Vector__XXX
SG_ Jystck2ThetaAxsDetentPosStatus : 50|2@1+ (1,0) [0|3] "" Vector__XXX
SG_ Jystck2GrpYAxsDetentPosStatus : 52|2@1+ (1,0) [0|3] "" Vector__XXX
SG_ Jystck2GrpXAxsDetentPosStatus : 54|2@1+ (1,0) [0|3] "" Vector__XXX
SG_ Joystick2Button16PressedStatus : 56|2@1+ (1,0) [0|3] "" Vector__XXX
SG_ Joystick2Button15PressedStatus : 58|2@1+ (1,0) [0|3] "" Vector__XXX
SG_ Joystick2Button14PressedStatus : 60|2@1+ (1,0) [0|3] "" Vector__XXX
SG_ Joystick2Button13PressedStatus : 62|2@1+ (1,0) [0|3] "" Vector__XXX

BO_ 2365446910 BJM3: 8 Vector__XXX
SG_ Jystck3XAxsNeutralPositionStatus : 0|2@1+ (1,0) [0|3] "" Vector__XXX
SG_ Jystck3XAxsLvrLftNegPosStatus : 2|2@1+ (1,0) [0|3] "" Vector__XXX
SG_ Jystck3XAxsLvrRightPstvPosStatus : 4|2@1+ (1,0) [0|3] "" Vector__XXX
SG_ Joystick3XAxisPosition : 6|10@1+ (0.1,0) [0|102] "%" Vector__XXX
SG_ Jystck3YAxsNeutralPositionStatus : 16|2@1+ (1,0) [0|3] "" Vector__XXX
SG_ Jystck3YAxsLvrBackNegPosStatus : 18|2@1+ (1,0) [0|3] "" Vector__XXX
SG_ Jystck3YAxsLvrFrwdPstvPosStatus : 20|2@1+ (1,0) [0|3] "" Vector__XXX
SG_ Joystick3YAxisPosition : 22|10@1+ (0.1,0) [0|102] "%" Vector__XXX
SG_ Jystck3YAxsDetentPositionStatus : 36|2@1+ (1,0) [0|3] "" Vector__XXX
SG_ Jystck3XAxsDetentPositionStatus : 38|2@1+ (1,0) [0|3] "" Vector__XXX
SG_ Joystick3Button4PressedStatus : 40|2@1+ (1,0) [0|3] "" Vector__XXX
SG_ Joystick3Button3PressedStatus : 42|2@1+ (1,0) [0|3] "" Vector__XXX
SG_ Joystick3Button2PressedStatus : 44|2@1+ (1,0) [0|3] "" Vector__XXX
SG_ Joystick3Button1PressedStatus : 46|2@1+ (1,0) [0|3] "" Vector__XXX
SG_ Joystick3Button8PressedStatus : 48|2@1+ (1,0) [0|3] "" Vector__XXX
SG_ Joystick3Button7PressedStatus : 50|2@1+ (1,0) [0|3] "" Vector__XXX
SG_ Joystick3Button6PressedStatus : 52|2@1+ (1,0) [0|3] "" Vector__XXX
SG_ Joystick3Button5PressedStatus : 54|2@1+ (1,0) [0|3] "" Vector__XXX
SG_ Joystick3Button12PressedStatus : 56|2@1+ (1,0) [0|3] "" Vector__XXX
SG_ Joystick3Button11PressedStatus : 58|2@1+ (1,0) [0|3] "" Vector__XXX
SG_ Joystick3Button10PressedStatus : 60|2@1+ (1,0) [0|3] "" Vector__XXX
SG_ Joystick3Button9PressedStatus : 62|2@1+ (1,0) [0|3] "" Vector__XXX

BO_ 2365447166 EJM3: 8 Vector__XXX
SG_ Jystck3GrpXAxsNtrlPositionStatus : 0|2@1+ (1,0) [0|3] "" Vector__XXX
SG_ Jystck3GrpXAxsLvrLftNegPosStatus : 2|2@1+ (1,0) [0|3] "" Vector__XXX
SG_ Jystck3GrpXAxsLvrRghtPstvPosStat : 4|2@1+ (1,0) [0|3] "" Vector__XXX
SG_ Joystick3GripXAxisPosition : 6|10@1+ (0.1,0) [0|102] "%" Vector__XXX
SG_ Jystck3GrpYAxsNtrlPositionStatus : 16|2@1+ (1,0) [0|3] "" Vector__XXX
SG_ Jystck3GrpYAxsLvrBackNegPosStat : 18|2@1+ (1,0) [0|3] "" Vector__XXX
SG_ Jystck3GrpYAxsLvrFrwdPstvPosStat : 20|2@1+ (1,0) [0|3] "" Vector__XXX
SG_ Joystick3GripYAxisPosition : 22|10@1+ (0.1,0) [0|102] "%" Vector__XXX
SG_ Jystck3ThetaAxsNtrlPosStatus : 32|2@1+ (1,0) [0|3] "" Vector__XXX
SG_ Jystck3ThtAxsCntrClckwsNegPsStat : 34|2@1+ (1,0) [0|3] "" Vector__XXX
SG_ Jystck3ThetaAxsClckwsPstvPosStat : 36|2@1+ (1,0) [0|3] "" Vector__XXX
SG_ Joystick3ThetaAxisPosition : 38|10@1+ (0.1,0) [0|102] "%" Vector__XXX
SG_ Jystck3ThetaAxsDetentPosStatus : 50|2@1+ (1,0) [0|3] "" Vector__XXX
SG_ Jystck3GrpYAxsDetentPosStatus : 52|2@1+ (1,0) [0|3] "" Vector__XXX
SG_ Jystck3GrpXAxsDetentPosStatus : 54|2@1+ (1,0) [0|3] "" Vector__XXX
SG_ Joystick3Button16PressedStatus : 56|2@1+ (1,0) [0|3] "" Vector__XXX
SG_ Joystick3Button15PressedStatus : 58|2@1+ (1,0) [0|3] "" Vector__XXX
SG_ Joystick3Button14PressedStatus : 60|2@1+ (1,0) [0|3] "" Vector__XXX
SG_ Joystick3Button13PressedStatus : 62|2@1+ (1,0) [0|3] "" Vector__XXX

BO_ 2566774014 MCI: 8 Vector__XXX
SG_ EngThrottleSyncMdeStat : 0|4@1+ (1,0) [0|15] "" Vector__XXX
SG_ TrollingModeStatus : 4|2@1+ (1,0) [0|3] "" Vector__XXX
SG_ SlowVesselModeStatus : 6|2@1+ (1,0) [0|3] "" Vector__XXX
SG_ EngineMarineOperatingModeStatus : 8|3@1+ (1,0) [0|7] "" Vector__XXX

BO_ 2633883646 FWD: 8 Vector__XXX
SG_ FrontWheelDriveActuatorStatus : 0|2@1+ (1,0) [0|3] "" Vector__XXX

BO_ 2566775038 AMB2: 8 Vector__XXX
SG_ SolarIntensityPercent : 0|8@1+ (0.4,0) [0|100] "%" Vector__XXX
SG_ SolarSensorMaximum : 8|8@1+ (0.4,0) [0|100] "mW/cm^2" Vector__XXX
SG_ SpecificHumidity : 16|16@1+ (0.01,0) [0|642.55] "g/kg" Vector__XXX
SG_ CalculatedAmbientAirTemperature : 32|16@1+ (0.03125,-273) [-273|1734.96875] "deg C" Vector__XXX
SG_ BarometricAbsolutePressure : 48|16@1+ (0.1,0) [0|6425.5] "kPa" Vector__XXX

BO_ 2566775294 CACI: 8 Vector__XXX
SG_ CabACRefrigCmprssorOtltPress : 0|8@1+ (16,0) [0|4000] "kPa" Vector__XXX
SG_ AirConditionerCompressorStatus : 8|2@1+ (1,0) [0|3] "" Vector__XXX

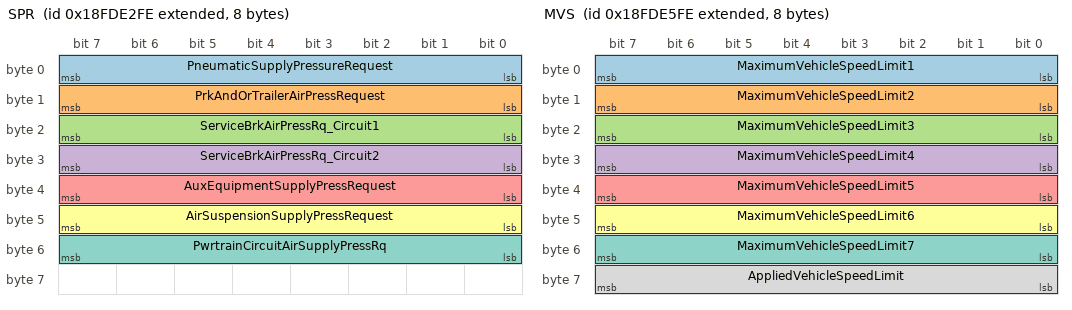
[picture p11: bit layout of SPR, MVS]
BO_ 2566775550 SPR: 8 Vector__XXX
SG_ PneumaticSupplyPressureRequest : 0|8@1+ (8,0) [0|2000] "kPa" Vector__XXX
SG_ PrkAndOrTrailerAirPressRequest : 8|8@1+ (8,0) [0|2000] "kPa" Vector__XXX
SG_ ServiceBrkAirPressRq_Circuit1 : 16|8@1+ (8,0) [0|2000] "kPa" Vector__XXX
SG_ ServiceBrkAirPressRq_Circuit2 : 24|8@1+ (8,0) [0|2000] "kPa" Vector__XXX
SG_ AuxEquipmentSupplyPressRequest : 32|8@1+ (8,0) [0|2000] "kPa" Vector__XXX
SG_ AirSuspensionSupplyPressRequest : 40|8@1+ (8,0) [0|2000] "kPa" Vector__XXX
SG_ PwrtrainCircuitAirSupplyPressRq : 48|8@1+ (8,0) [0|2000] "kPa" Vector__XXX

BO_ 2566775806 EOAC: 8 Vector__XXX
SG_ TravelVelocityControlPosition : 0|8@1+ (1,-125) [-125|125] "%" Vector__XXX

BO_ 2566776062 EPD: 8 Vector__XXX
SG_ PayloadPercentage : 0|8@1+ (1,0) [0|250] "%" Vector__XXX
SG_ PayloadWeight : 8|24@1+ (2,0) [0|32899070] "kg" Vector__XXX
SG_ PayloadWeightConfidence : 32|8@1+ (0.5,0) [0|125] "%" Vector__XXX
SG_ PayloadCarryBackWeight : 40|16@1+ (2,0) [0|128510] "kg" Vector__XXX
SG_ PayloadCapacityPercentage : 56|8@1+ (1,0) [0|250] "%" Vector__XXX

BO_ 2566776318 MVS: 8 Vector__XXX
SG_ MaximumVehicleSpeedLimit1 : 0|8@1+ (1,0) [0|250] "km/h" Vector__XXX
SG_ MaximumVehicleSpeedLimit2 : 8|8@1+ (1,0) [0|250] "km/h" Vector__XXX
SG_ MaximumVehicleSpeedLimit3 : 16|8@1+ (1,0) [0|250] "km/h" Vector__XXX
SG_ MaximumVehicleSpeedLimit4 : 24|8@1+ (1,0) [0|250] "km/h" Vector__XXX
SG_ MaximumVehicleSpeedLimit5 : 32|8@1+ (1,0) [0|250] "km/h" Vector__XXX
SG_ MaximumVehicleSpeedLimit6 : 40|8@1+ (1,0) [0|250] "km/h" Vector__XXX
SG_ MaximumVehicleSpeedLimit7 : 48|8@1+ (1,0) [0|250] "km/h" Vector__XXX
SG_ AppliedVehicleSpeedLimit : 56|8@1+ (1,0) [0|250] "km/h" Vector__XXX

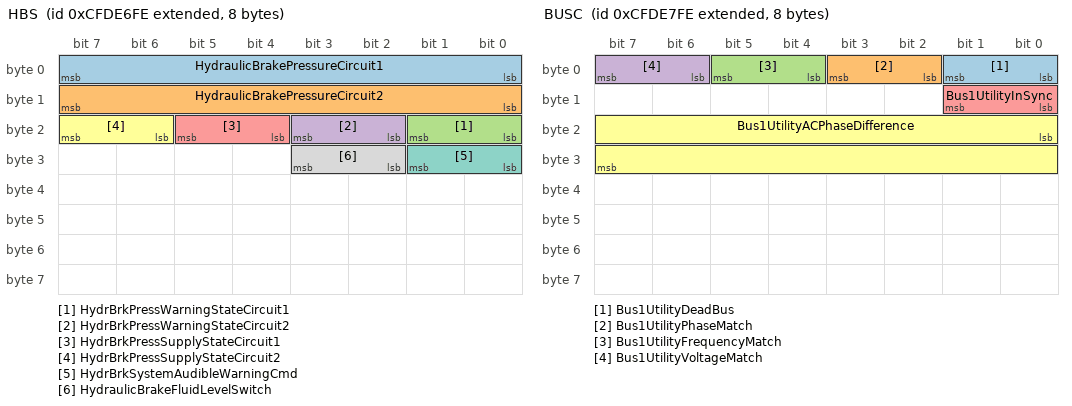
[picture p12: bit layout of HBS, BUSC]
BO_ 2365449982 HBS: 8 Vector__XXX
SG_ HydraulicBrakePressureCircuit1 : 0|8@1+ (100,0) [0|25000] "kPa" Vector__XXX
SG_ HydraulicBrakePressureCircuit2 : 8|8@1+ (100,0) [0|25000] "kPa" Vector__XXX
SG_ HydrBrkPressWarningStateCircuit1 : 16|2@1+ (1,0) [0|3] "" Vector__XXX
SG_ HydrBrkPressWarningStateCircuit2 : 18|2@1+ (1,0) [0|3] "" Vector__XXX
SG_ HydrBrkPressSupplyStateCircuit1 : 20|2@1+ (1,0) [0|3] "" Vector__XXX
SG_ HydrBrkPressSupplyStateCircuit2 : 22|2@1+ (1,0) [0|3] "" Vector__XXX
SG_ HydrBrkSystemAudibleWarningCmd : 24|2@1+ (1,0) [0|3] "" Vector__XXX
SG_ HydraulicBrakeFluidLevelSwitch : 26|2@1+ (1,0) [0|3] "" Vector__XXX

BO_ 2365450238 BUSC: 8 Vector__XXX
SG_ Bus1UtilityDeadBus : 0|2@1+ (1,0) [0|3] "" Vector__XXX
SG_ Bus1UtilityPhaseMatch : 2|2@1+ (1,0) [0|3] "" Vector__XXX
SG_ Bus1UtilityFrequencyMatch : 4|2@1+ (1,0) [0|3] "" Vector__XXX
SG_ Bus1UtilityVoltageMatch : 6|2@1+ (1,0) [0|3] "" Vector__XXX
SG_ Bus1UtilityInSync : 8|2@1+ (1,0) [0|3] "" Vector__XXX
SG_ Bus1UtilityACPhaseDifference : 16|16@1+ (0.0078125,-200) [-200|301.99] "deg" Vector__XXX

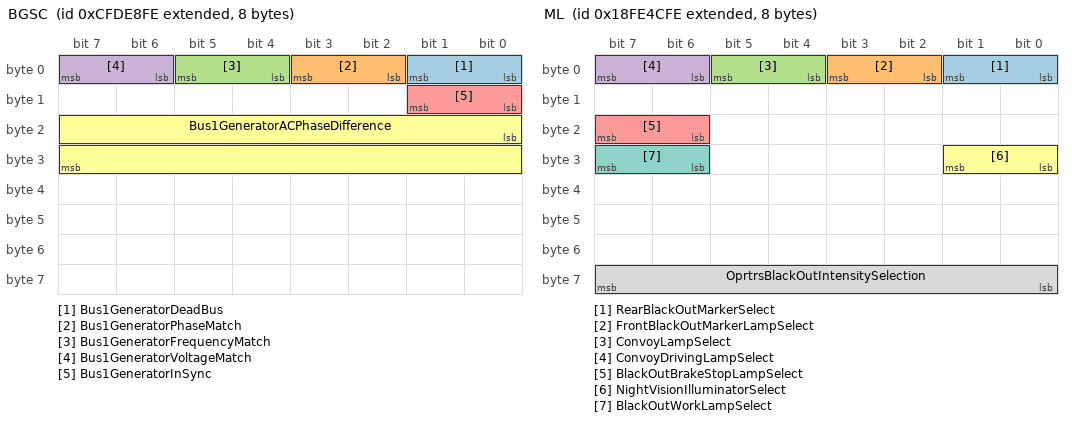
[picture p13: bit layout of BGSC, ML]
BO_ 2365450494 BGSC: 8 Vector__XXX
SG_ Bus1GeneratorDeadBus : 0|2@1+ (1,0) [0|3] "" Vector__XXX
SG_ Bus1GeneratorPhaseMatch : 2|2@1+ (1,0) [0|3] "" Vector__XXX
SG_ Bus1GeneratorFrequencyMatch : 4|2@1+ (1,0) [0|3] "" Vector__XXX
SG_ Bus1GeneratorVoltageMatch : 6|2@1+ (1,0) [0|3] "" Vector__XXX
SG_ Bus1GeneratorInSync : 8|2@1+ (1,0) [0|3] "" Vector__XXX
SG_ Bus1GeneratorACPhaseDifference : 16|16@1+ (0.0078125,-200) [-200|301.99] "deg" Vector__XXX

BO_ 2365450750 BPCAC: 8 Vector__XXX
SG_ Bus1PhaseCALineLineACRMSVoltage : 0|16@1+ (1,0) [0|64255] "V" Vector__XXX
SG_ Bus1PhaseCLineNtrlACRMSVoltage : 16|16@1+ (1,0) [0|64255] "V" Vector__XXX
SG_ Bus1PhaseCACFrequency : 32|16@1+ (0.0078125,0) [0|501.9921875] "Hz" Vector__XXX

BO_ 2365451006 BPBAC: 8 Vector__XXX
SG_ Bus1PhaseBCLineLineACRMSVoltage : 0|16@1+ (1,0) [0|64255] "V" Vector__XXX
SG_ Bus1PhaseBLineNtrlACRMSVoltage : 16|16@1+ (1,0) [0|64255] "V" Vector__XXX
SG_ Bus1PhaseBACFrequency : 32|16@1+ (0.0078125,0) [0|501.9921875] "Hz" Vector__XXX

BO_ 2365451262 BPAAC: 8 Vector__XXX
SG_ Bus1PhaseABLineLineACRMSVoltage : 0|16@1+ (1,0) [0|64255] "V" Vector__XXX
SG_ Bus1PhaseALineNtrlACRMSVoltage : 16|16@1+ (1,0) [0|64255] "V" Vector__XXX
SG_ Bus1PhaseAACFrequency : 32|16@1+ (0.0078125,0) [0|501.9921875] "Hz" Vector__XXX

BO_ 2365451518 BAAC: 8 Vector__XXX
SG_ Bus1AverageLineLineACRMSVoltage : 0|16@1+ (1,0) [0|64255] "V" Vector__XXX
SG_ Bus1AvrgLineNeutralACRMSVoltage : 16|16@1+ (1,0) [0|64255] "V" Vector__XXX
SG_ Bus1AverageACFrequency : 32|16@1+ (0.0078125,0) [0|501.9921875] "Hz" Vector__XXX

BO_ 2365451774 UTACE: 8 Vector__XXX
SG_ UtilityTotalKWHoursExport : 0|32@1+ (1,0) [0|4211081215] "kWh" Vector__XXX
SG_ UtilityTotalKWHoursImport : 32|32@1+ (1,0) [0|4211081215] "kWh" Vector__XXX

BO_ 2365452030 UPCACR: 8 Vector__XXX
SG_ UtilityPhaseCReactivePower : 0|32@1+ (1,-2000000000) [-2000000000|2211081215] "VAr" Vector__XXX
SG_ UtilityPhaseCPowerFactor : 32|16@1+ (6.103515625E-005,-1) [-1|2.921814] "" Vector__XXX
SG_ UtilityPhaseCPowerFactorLagging : 48|2@1+ (1,0) [0|3] "" Vector__XXX

BO_ 2365452286 UPCACP: 8 Vector__XXX
SG_ UtilityPhaseCRealPower : 0|32@1+ (1,-2000000000) [-2000000000|2211081215] "W" Vector__XXX
SG_ UtilityPhaseCApparentPower : 32|32@1+ (1,-2000000000) [-2000000000|2211081215] "VA" Vector__XXX

BO_ 2365452542 UPCAC: 8 Vector__XXX
SG_ UtilityPhaseCALineLineACRMSVltg : 0|16@1+ (1,0) [0|64255] "V" Vector__XXX
SG_ UtilityPhaseCLineNtrlACRMSVltg : 16|16@1+ (1,0) [0|64255] "V" Vector__XXX
SG_ UtilityPhaseCACFrequency : 32|16@1+ (0.0078125,0) [0|501.9921875] "Hz" Vector__XXX
SG_ UtilityPhaseCACRMSCurrent : 48|16@1+ (1,0) [0|64255] "A" Vector__XXX

BO_ 2365452798 UPBACR: 8 Vector__XXX
SG_ UtilityPhaseBReactivePower : 0|32@1+ (1,-2000000000) [-2000000000|2211081215] "VAr" Vector__XXX
SG_ UtilityPhaseBPowerFactor : 32|16@1+ (6.103515625E-005,-1) [-1|2.921814] "" Vector__XXX
SG_ UtilityPhaseBPowerFactorLagging : 48|2@1+ (1,0) [0|3] "" Vector__XXX

BO_ 2365453054 UPBACP: 8 Vector__XXX
SG_ UtilityPhaseBRealPower : 0|32@1+ (1,-2000000000) [-2000000000|2211081215] "W" Vector__XXX
SG_ UtilityPhaseBApparentPower : 32|32@1+ (1,-2000000000) [-2000000000|2211081215] "VA" Vector__XXX

BO_ 2365453310 UPBAC: 8 Vector__XXX
SG_ UtilityPhaseBCLineLineACRMSVltg : 0|16@1+ (1,0) [0|64255] "V" Vector__XXX
SG_ UtilityPhaseBLineNtrlACRMSVltg : 16|16@1+ (1,0) [0|64255] "V" Vector__XXX
SG_ UtilityPhaseBACFrequency : 32|16@1+ (0.0078125,0) [0|501.9921875] "Hz" Vector__XXX
SG_ UtilityPhaseBACRMSCurrent : 48|16@1+ (1,0) [0|64255] "A" Vector__XXX

BO_ 2365453566 UPACCR: 8 Vector__XXX
SG_ UtilityPhaseAReactivePower : 0|32@1+ (1,-2000000000) [-2000000000|2211081215] "VAr" Vector__XXX
SG_ UtilityPhaseAPowerFactor : 32|16@1+ (6.103515625E-005,-1) [-1|2.921814] "" Vector__XXX
SG_ UtilityPhaseAPowerFactorLagging : 48|2@1+ (1,0) [0|3] "" Vector__XXX

BO_ 2365453822 UPAACP: 8 Vector__XXX
SG_ UtilityPhaseARealPower : 0|32@1+ (1,-2000000000) [-2000000000|2211081215] "W" Vector__XXX
SG_ UtilityPhaseAApparentPower : 32|32@1+ (1,-2000000000) [-2000000000|2211081215] "VA" Vector__XXX

BO_ 2365454078 UPAAC: 8 Vector__XXX
SG_ UtilityPhaseABLineLineACRMSVltg : 0|16@1+ (1,0) [0|64255] "V" Vector__XXX
SG_ UtilityPhaseALineNtrlACRMSVltg : 16|16@1+ (1,0) [0|64255] "V" Vector__XXX
SG_ UtilityPhaseAACFrequency : 32|16@1+ (0.0078125,0) [0|501.9921875] "Hz" Vector__XXX
SG_ UtilityPhaseAACRMSCurrent : 48|16@1+ (1,0) [0|64255] "A" Vector__XXX

BO_ 2365454334 UTACR: 8 Vector__XXX
SG_ UtilityTotalReactivePower : 0|32@1+ (1,-2000000000) [-2000000000|2211081215] "VAr" Vector__XXX
SG_ UtilityOverallPowerFactor : 32|16@1+ (6.103515625E-005,-1) [-1|2.921814] "" Vector__XXX
SG_ UtilityOverallPowerFactorLagging : 48|2@1+ (1,0) [0|3] "" Vector__XXX

BO_ 2365454590 UTACP: 8 Vector__XXX
SG_ UtilityTotalRealPower : 0|32@1+ (1,-2000000000) [-2000000000|2211081215] "W" Vector__XXX
SG_ UtilityTotalApparentPower : 32|32@1+ (1,-2000000000) [-2000000000|2211081215] "VA" Vector__XXX

BO_ 2365454846 UAAC: 8 Vector__XXX
SG_ UtilityAvrgLineLineACRMSVoltage : 0|16@1+ (1,0) [0|64255] "V" Vector__XXX
SG_ UtilityAvrgLineNtrlACRMSVoltage : 16|16@1+ (1,0) [0|64255] "V" Vector__XXX
SG_ UtilityAverageACFrequency : 32|16@1+ (0.0078125,0) [0|501.9921875] "Hz" Vector__XXX
SG_ UtilityAverageACRMSCurrent : 48|16@1+ (1,0) [0|64255] "A" Vector__XXX

BO_ 2365455102 GTACE: 8 Vector__XXX
SG_ GeneratorTotalKWHoursExport : 0|32@1+ (1,0) [0|4211081215] "kWh" Vector__XXX
SG_ GeneratorTotalKWHoursImport : 32|32@1+ (1,0) [0|4211081215] "kWh" Vector__XXX

BO_ 2365455358 GPCACR: 8 Vector__XXX
SG_ GeneratorPhaseCReactivePower : 0|32@1+ (1,-2000000000) [-2000000000|2211081215] "VAr" Vector__XXX
SG_ GeneratorPhaseCPowerFactor : 32|16@1+ (6.103515625E-005,-1) [-1|2.921814] "" Vector__XXX
SG_ GenPhaseCPowerFactorLagging : 48|2@1+ (1,0) [0|3] "" Vector__XXX

BO_ 2365455614 GPCACP: 8 Vector__XXX
SG_ GeneratorPhaseCRealPower : 0|32@1+ (1,-2000000000) [-2000000000|2211081215] "W" Vector__XXX
SG_ GeneratorPhaseCApparentPower : 32|32@1+ (1,-2000000000) [-2000000000|2211081215] "VA" Vector__XXX

BO_ 2365455870 GPCAC: 8 Vector__XXX
SG_ GenPhaseCALineLineACRMSVoltage : 0|16@1+ (1,0) [0|64255] "V" Vector__XXX
SG_ GenPhaseCLineNeutralACRMSVoltage : 16|16@1+ (1,0) [0|64255] "V" Vector__XXX
SG_ GeneratorPhaseCACFrequency : 32|16@1+ (0.0078125,0) [0|501.9921875] "Hz" Vector__XXX
SG_ GeneratorPhaseCACRMSCurrent : 48|16@1+ (1,0) [0|64255] "A" Vector__XXX

BO_ 2365456126 GPBACRP: 8 Vector__XXX
SG_ GeneratorPhaseBReactivePower : 0|32@1+ (1,-2000000000) [-2000000000|2211081215] "VAr" Vector__XXX
SG_ GeneratorPhaseBPowerFactor : 32|16@1+ (6.103515625E-005,-1) [-1|2.921814] "" Vector__XXX
SG_ GenPhaseBPowerFactorLagging : 48|2@1+ (1,0) [0|3] "" Vector__XXX

BO_ 2365456382 GPBACP: 8 Vector__XXX
SG_ GeneratorPhaseBRealPower : 0|32@1+ (1,-2000000000) [-2000000000|2211081215] "W" Vector__XXX
SG_ GeneratorPhaseBApparentPower : 32|32@1+ (1,-2000000000) [-2000000000|2211081215] "VA" Vector__XXX

BO_ 2365456638 GPBAC: 8 Vector__XXX
SG_ GenPhaseBCLineLineACRMSVoltage : 0|16@1+ (1,0) [0|64255] "V" Vector__XXX
SG_ GenPhaseBLineNeutralACRMSVoltage : 16|16@1+ (1,0) [0|64255] "V" Vector__XXX
SG_ GeneratorPhaseBACFrequency : 32|16@1+ (0.0078125,0) [0|501.9921875] "Hz" Vector__XXX
SG_ GeneratorPhaseBACRMSCurrent : 48|16@1+ (1,0) [0|64255] "A" Vector__XXX

BO_ 2365456894 GPAACR: 8 Vector__XXX
SG_ GeneratorPhaseAReactivePower : 0|32@1+ (1,-2000000000) [-2000000000|2211081215] "VAr" Vector__XXX
SG_ GeneratorPhaseAPowerFactor : 32|16@1+ (6.103515625E-005,-1) [-1|2.921814] "" Vector__XXX
SG_ GenPhaseAPowerFactorLagging : 48|2@1+ (1,0) [0|3] "" Vector__XXX

BO_ 2365457150 GPAACP: 8 Vector__XXX
SG_ GeneratorPhaseARealPower : 0|32@1+ (1,-2000000000) [-2000000000|2211081215] "W" Vector__XXX
SG_ GeneratorPhaseAApparentPower : 32|32@1+ (1,-2000000000) [-2000000000|2211081215] "VA" Vector__XXX

BO_ 2365457406 GPAAC: 8 Vector__XXX
SG_ GenPhaseABLineLineACRMSVoltage : 0|16@1+ (1,0) [0|64255] "V" Vector__XXX
SG_ GenPhaseALineNeutralACRMSVoltage : 16|16@1+ (1,0) [0|64255] "V" Vector__XXX
SG_ GeneratorPhaseAACFrequency : 32|16@1+ (0.0078125,0) [0|501.9921875] "Hz" Vector__XXX
SG_ GeneratorPhaseAACRMSCurrent : 48|16@1+ (1,0) [0|64255] "A" Vector__XXX

BO_ 2365457662 GTACR: 8 Vector__XXX
SG_ GeneratorTotalReactivePower : 0|32@1+ (1,-2000000000) [-2000000000|2211081215] "VAr" Vector__XXX
SG_ GeneratorOverallPowerFactor : 32|16@1+ (6.103515625E-005,-1) [-1|2.921814] "" Vector__XXX
SG_ GenOverallPowerFactorLagging : 48|2@1+ (1,0) [0|3] "" Vector__XXX

BO_ 2365457918 GTACP: 8 Vector__XXX
SG_ GeneratorTotalRealPower : 0|32@1+ (1,-2000000000) [-2000000000|2211081215] "W" Vector__XXX
SG_ GeneratorTotalApparentPower : 32|32@1+ (1,-2000000000) [-2000000000|2211081215] "VA" Vector__XXX

BO_ 2365458174 GAAC: 8 Vector__XXX
SG_ GenAvrgLineLineACRMSVoltage : 0|16@1+ (1,0) [0|64255] "V" Vector__XXX
SG_ GenAvrgLineNeutralACRMSVoltage : 16|16@1+ (1,0) [0|64255] "V" Vector__XXX
SG_ GeneratorAverageACFrequency : 32|16@1+ (0.0078125,0) [0|501.9921875] "Hz" Vector__XXX
SG_ GeneratorAverageACRMSCurrent : 48|16@1+ (1,0) [0|64255] "A" Vector__XXX

BO_ 2566785022 ET: 8 Vector__XXX
SG_ EngExhstManifoldBnk2Temperature1 : 0|16@1+ (0.03125,-273) [-273|1734.96875] "deg C" Vector__XXX
SG_ EngExhstManifoldBnk1Temperature1 : 16|16@1+ (0.03125,-273) [-273|1734.96875] "deg C" Vector__XXX
SG_ EngExhstManifoldBnk2Temperature2 : 32|16@1+ (0.03125,-273) [-273|1734.96875] "deg C" Vector__XXX
SG_ EngExhstManifoldBnk1Temperature2 : 48|16@1+ (0.03125,-273) [-273|1734.96875] "deg C" Vector__XXX

BO_ 2566786302 WSMEM: 0 Vector__XXX

BO_ 2566786558 WSMSTR: 8 Vector__XXX
SG_ NumberOfMembersInWorkingSet : 0|8@1+ (1,0) [0|250] "" Vector__XXX

BO_ 2566799614 LD: 8 Vector__XXX
SG_ RunningLight : 0|2@1+ (1,0) [0|3] "" Vector__XXX
SG_ AlternateBeamHeadLightData : 2|2@1+ (1,0) [0|3] "" Vector__XXX
SG_ LowBeamHeadLightData : 4|2@1+ (1,0) [0|3] "" Vector__XXX
SG_ HighBeamHeadLightData : 6|2@1+ (1,0) [0|3] "" Vector__XXX
SG_ TractorFrontFogLights : 8|2@1+ (1,0) [0|3] "" Vector__XXX
SG_ RotatingBeaconLight : 10|2@1+ (1,0) [0|3] "" Vector__XXX
SG_ RightTurnSignalLights : 12|2@1+ (1,0) [0|3] "" Vector__XXX
SG_ LeftTurnSignalLights : 14|2@1+ (1,0) [0|3] "" Vector__XXX
SG_ BackUpLightAndAlarmHorn : 16|2@1+ (1,0) [0|3] "" Vector__XXX
SG_ CenterStopLight : 18|2@1+ (1,0) [0|3] "" Vector__XXX
SG_ RightStopLight : 20|2@1+ (1,0) [0|3] "" Vector__XXX
SG_ LeftStopLight : 22|2@1+ (1,0) [0|3] "" Vector__XXX
SG_ ImplementClearanceLight : 24|2@1+ (1,0) [0|3] "" Vector__XXX
SG_ TractorClearanceLight : 26|2@1+ (1,0) [0|3] "" Vector__XXX
SG_ ImplementMarkerLight : 28|2@1+ (1,0) [0|3] "" Vector__XXX
SG_ TractorMarkerLight : 30|2@1+ (1,0) [0|3] "" Vector__XXX
SG_ RearFogLights : 32|2@1+ (1,0) [0|3] "" Vector__XXX
SG_ TractorUndersideMntdWorkLights : 34|2@1+ (1,0) [0|3] "" Vector__XXX
SG_ TractorRearLowMountedWorkLights : 36|2@1+ (1,0) [0|3] "" Vector__XXX
SG_ TractorRearHighMountedWorkLights : 38|2@1+ (1,0) [0|3] "" Vector__XXX
SG_ TractorSideLowMountedWorkLights : 40|2@1+ (1,0) [0|3] "" Vector__XXX
SG_ TractorSideHighMountedWorkLights : 42|2@1+ (1,0) [0|3] "" Vector__XXX
SG_ TractorFrontLowMountedWorkLights : 44|2@1+ (1,0) [0|3] "" Vector__XXX
SG_ TractorFrntHighMountedWorkLights : 46|2@1+ (1,0) [0|3] "" Vector__XXX
SG_ ImplementOEMOption2Light : 48|2@1+ (1,0) [0|3] "" Vector__XXX
SG_ ImplementOEMOption1Light : 50|2@1+ (1,0) [0|3] "" Vector__XXX
SG_ ImplementRightFacingWorkLight : 52|2@1+ (1,0) [0|3] "" Vector__XXX
SG_ ImplementLeftForwardWorkLight : 54|2@1+ (1,0) [0|3] "" Vector__XXX
SG_ ImplementRightForwardWorkLight : 58|2@1+ (1,0) [0|3] "" Vector__XXX
SG_ ImplementLeftFacingWorkLight : 60|2@1+ (1,0) [0|3] "" Vector__XXX
SG_ ImplementRearWorkLight : 62|2@1+ (1,0) [0|3] "" Vector__XXX

BO_ 2365473278 LCMD: 8 Vector__XXX
SG_ RunningLightCommand : 0|2@1+ (1,0) [0|3] "" Vector__XXX
SG_ AlternateBeamHeadLightCommand : 2|2@1+ (1,0) [0|3] "" Vector__XXX
SG_ LowBeamHeadLightCommand : 4|2@1+ (1,0) [0|3] "" Vector__XXX
SG_ HighBeamHeadLightCommand : 6|2@1+ (1,0) [0|3] "" Vector__XXX
SG_ TractorFrontFogLightsCommand : 8|2@1+ (1,0) [0|3] "" Vector__XXX
SG_ RotatingBeaconLightCommand : 10|2@1+ (1,0) [0|3] "" Vector__XXX
SG_ RightTurnSignalLightsCommand : 12|2@1+ (1,0) [0|3] "" Vector__XXX
SG_ LeftTurnSignalLightsCommand : 14|2@1+ (1,0) [0|3] "" Vector__XXX
SG_ BackUpLightAndAlarmHornCommand : 16|2@1+ (1,0) [0|3] "" Vector__XXX
SG_ CenterStopLightCommand : 18|2@1+ (1,0) [0|3] "" Vector__XXX
SG_ RightStopLightCommand : 20|2@1+ (1,0) [0|3] "" Vector__XXX
SG_ LeftStopLightCommand : 22|2@1+ (1,0) [0|3] "" Vector__XXX
SG_ ImplementClearanceLightCommand : 24|2@1+ (1,0) [0|3] "" Vector__XXX
SG_ TractorClearanceLightCommand : 26|2@1+ (1,0) [0|3] "" Vector__XXX
SG_ ImplementMarkerLightCommand : 28|2@1+ (1,0) [0|3] "" Vector__XXX
SG_ TractorMarkerLightCommand : 30|2@1+ (1,0) [0|3] "" Vector__XXX
SG_ RearFogLightCommand : 32|2@1+ (1,0) [0|3] "" Vector__XXX
SG_ TractorUnderSdeMntdWorkLightsCmd : 34|2@1+ (1,0) [0|3] "" Vector__XXX
SG_ TractorRearLowMntdWorkLightsCmd : 36|2@1+ (1,0) [0|3] "" Vector__XXX
SG_ TractorRearHghMntdWorkLightsCmd : 38|2@1+ (1,0) [0|3] "" Vector__XXX
SG_ TractorSideLowMntdWorkLightsCmd : 40|2@1+ (1,0) [0|3] "" Vector__XXX
SG_ TractorSideHghMntdWorkLightsCmd : 42|2@1+ (1,0) [0|3] "" Vector__XXX
SG_ TractorFrntLowMntdWorkLightsCmd : 44|2@1+ (1,0) [0|3] "" Vector__XXX
SG_ TractorFrntHghMntdWorkLightsCmd : 46|2@1+ (1,0) [0|3] "" Vector__XXX
SG_ ImplementOEMOption2LightCommand : 48|2@1+ (1,0) [0|3] "" Vector__XXX
SG_ ImplementOEMOption1LightCommand : 50|2@1+ (1,0) [0|3] "" Vector__XXX
SG_ ImplementRightFacingWorkLightCmd : 52|2@1+ (1,0) [0|3] "" Vector__XXX
SG_ ImplementLeftForwardWorkLightCmd : 54|2@1+ (1,0) [0|3] "" Vector__XXX
SG_ LightingDataRequestCommand : 56|2@1+ (1,0) [0|3] "" Vector__XXX
SG_ ImplementRightFrwdWorkLightCmd : 58|2@1+ (1,0) [0|3] "" Vector__XXX
SG_ ImplementLeftFacingWorkLightCmd : 60|2@1+ (1,0) [0|3] "" Vector__XXX
SG_ ImplementRearWorkLightCommand : 62|2@1+ (1,0) [0|3] "" Vector__XXX

BO_ 2566802174 ETC7: 8 Vector__XXX
SG_ TrnsmCurrentRngDisplayBlankStat : 0|2@1+ (1,0) [0|3] "" Vector__XXX
SG_ TransmissionServiceIndicator : 2|2@1+ (1,0) [0|3] "" Vector__XXX
SG_ TrnsmRqedRngDisplayBlankStat : 4|2@1+ (1,0) [0|3] "" Vector__XXX
SG_ TrnsmRqedRngDisplayFlashStat : 6|2@1+ (1,0) [0|3] "" Vector__XXX
SG_ TransmissionReadyForBrakeRelease : 8|2@1+ (1,0) [0|3] "" Vector__XXX
SG_ ActiveShiftConsoleIndicator : 10|2@1+ (1,0) [0|3] "" Vector__XXX
SG_ TransmissionEngineCrankEnable : 12|2@1+ (1,0) [0|3] "" Vector__XXX
SG_ TransmissionShiftInhibitIndictr : 14|2@1+ (1,0) [0|3] "" Vector__XXX
SG_ TransmissionMode4Indicator : 16|2@1+ (1,0) [0|3] "" Vector__XXX
SG_ TransmissionMode3Indicator : 18|2@1+ (1,0) [0|3] "" Vector__XXX
SG_ TransmissionMode2Indicator : 20|2@1+ (1,0) [0|3] "" Vector__XXX
SG_ TransmissionMode1Indicator : 22|2@1+ (1,0) [0|3] "" Vector__XXX
SG_ TransmissionRequestedGearFdbck : 24|8@1+ (1,-125) [-125|125] "" Vector__XXX
SG_ TransmissionMode5Indicator : 32|2@1+ (1,0) [0|3] "" Vector__XXX
SG_ TransmissionMode6Indicator : 34|2@1+ (1,0) [0|3] "" Vector__XXX
SG_ TransmissionMode7Indicator : 36|2@1+ (1,0) [0|3] "" Vector__XXX
SG_ TransmissionMode8Indicator : 38|2@1+ (1,0) [0|3] "" Vector__XXX
SG_ TrnsmReverseGearShftInhbtStat : 40|2@1+ (1,0) [0|3] "" Vector__XXX
SG_ TransmissionWarningIndicator : 42|2@1+ (1,0) [0|3] "" Vector__XXX
SG_ TransmissionMode9Indicator : 44|2@1+ (1,0) [0|3] "" Vector__XXX
SG_ TransmissionMode10Indicator : 46|2@1+ (1,0) [0|3] "" Vector__XXX
SG_ TrnsmAirSupplyPressIndictr : 48|3@1+ (1,0) [0|7] "" Vector__XXX
SG_ TransmissionAutoNeutralState : 51|3@1+ (1,0) [0|7] "" Vector__XXX
SG_ TransmissionManualModeIndicator : 54|2@1+ (1,0) [0|3] "" Vector__XXX

BO_ 2566802430 TCFG2: 8 Vector__XXX
SG_ TransmissionTorqueLimit : 0|16@1+ (1,0) [0|64255] "Nm" Vector__XXX
SG_ TransmissionReferenceTorque : 16|16@1+ (1,0) [0|64255] "Nm" Vector__XXX
SG_ TrnsmCommsFailureIdlTrqLmt : 32|8@1+ (1,-125) [-125|125] "%" Vector__XXX

BO_ 2566802686 ML: 8 Vector__XXX
SG_ RearBlackOutMarkerSelect : 0|2@1+ (1,0) [0|3] "" Vector__XXX
SG_ FrontBlackOutMarkerLampSelect : 2|2@1+ (1,0) [0|3] "" Vector__XXX
SG_ ConvoyLampSelect : 4|2@1+ (1,0) [0|3] "" Vector__XXX
SG_ ConvoyDrivingLampSelect : 6|2@1+ (1,0) [0|3] "" Vector__XXX
SG_ BlackOutBrakeStopLampSelect : 22|2@1+ (1,0) [0|3] "" Vector__XXX
SG_ NightVisionIlluminatorSelect : 24|2@1+ (1,0) [0|3] "" Vector__XXX
SG_ BlackOutWorkLampSelect : 30|2@1+ (1,0) [0|3] "" Vector__XXX
SG_ OprtrsBlackOutIntensitySelection : 56|8@1+ (0.4,0) [0|100] "%" Vector__XXX

BO_ 2633911806 TAVG: 8 Vector__XXX
SG_ EngineTotalAverageFuelRate : 0|16@1+ (0.05,0) [0|3212.75] "l/h" Vector__XXX
SG_ EngineTotalAverageFuelEconomy : 16|16@1+ (0.001953125,0) [0|125.498046875] "km/l" Vector__XXX

BO_ 2566803198 DC1: 8 Vector__XXX
SG_ PositionOfDoors : 0|4@1+ (1,0) [0|15] "" Vector__XXX
SG_ RampWheelChairLiftPosition : 4|2@1+ (1,0) [0|3] "" Vector__XXX
SG_ Status2OfDoors : 6|2@1+ (1,0) [0|3] "" Vector__XXX

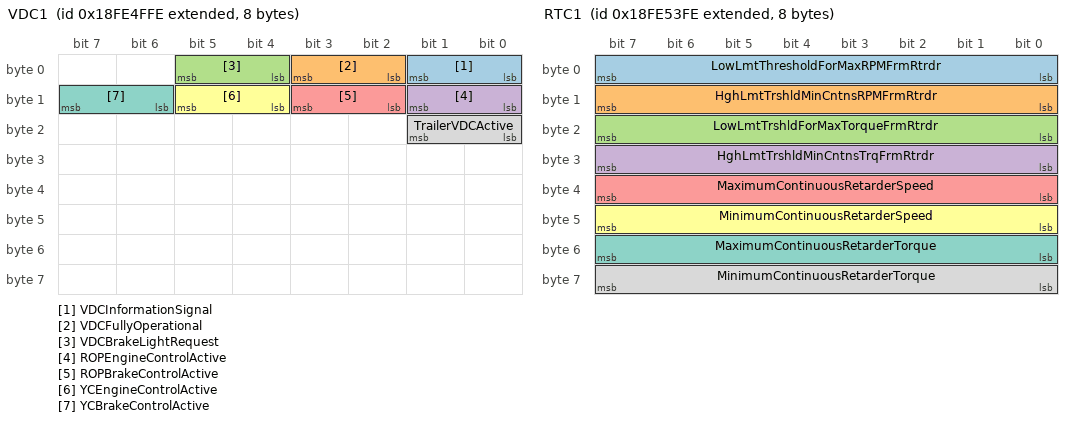
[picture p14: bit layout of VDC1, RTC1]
BO_ 2566803454 VDC1: 8 Vector__XXX
SG_ VDCInformationSignal : 0|2@1+ (1,0) [0|3] "" Vector__XXX
SG_ VDCFullyOperational : 2|2@1+ (1,0) [0|3] "" Vector__XXX
SG_ VDCBrakeLightRequest : 4|2@1+ (1,0) [0|3] "" Vector__XXX
SG_ ROPEngineControlActive : 8|2@1+ (1,0) [0|3] "" Vector__XXX
SG_ ROPBrakeControlActive : 10|2@1+ (1,0) [0|3] "" Vector__XXX
SG_ YCEngineControlActive : 12|2@1+ (1,0) [0|3] "" Vector__XXX
SG_ YCBrakeControlActive : 14|2@1+ (1,0) [0|3] "" Vector__XXX
SG_ TrailerVDCActive : 16|2@1+ (1,0) [0|3] "" Vector__XXX

BO_ 2566803710 BT1: 8 Vector__XXX
SG_ Battery1Temperature : 0|8@1+ (1,-40) [-40|210] "deg C" Vector__XXX
SG_ Battery2Temperature : 8|8@1+ (1,-40) [-40|210] "deg C" Vector__XXX
SG_ SLIBattery3Temperature : 16|8@1+ (1,-40) [-40|210] "deg C" Vector__XXX
SG_ SLIBattery4Temperature : 24|8@1+ (1,-40) [-40|210] "deg C" Vector__XXX

BO_ 2566803966 ACC2: 8 Vector__XXX
SG_ ACCUsageDemand : 0|2@1+ (1,0) [0|3] "" Vector__XXX
SG_ RequestedACCDistanceMode : 5|3@1+ (1,0) [0|7] "" Vector__XXX

BO_ 2566804222 VEP3: 8 Vector__XXX
SG_ AlternatorCurrent : 0|16@1+ (0.05,-1600) [-1600|1612.75] "A" Vector__XXX
SG_ NetBatteryCurrent : 16|16@1+ (0.05,-1600) [-1600|1612.75] "A" Vector__XXX
SG_ SLIBattery2NetCurrent : 32|16@1+ (0.05,-1600) [-1600|1612.75] "A" Vector__XXX

BO_ 2566804478 RTC1: 8 Vector__XXX
SG_ LowLmtThresholdForMaxRPMFrmRtrdr : 0|8@1+ (32,0) [0|8000] "rpm" Vector__XXX
SG_ HghLmtTrshldMinCntnsRPMFrmRtrdr : 8|8@1+ (32,0) [0|8000] "rpm" Vector__XXX
SG_ LowLmtTrshldForMaxTorqueFrmRtrdr : 16|8@1+ (1,-125) [-125|125] "%" Vector__XXX
SG_ HghLmtTrshldMinCntnsTrqFrmRtrdr : 24|8@1+ (1,-125) [-125|125] "%" Vector__XXX
SG_ MaximumContinuousRetarderSpeed : 32|8@1+ (32,0) [0|8000] "rpm" Vector__XXX
SG_ MinimumContinuousRetarderSpeed : 40|8@1+ (32,0) [0|8000] "rpm" Vector__XXX
SG_ MaximumContinuousRetarderTorque : 48|8@1+ (1,-125) [-125|125] "%" Vector__XXX
SG_ MinimumContinuousRetarderTorque : 56|8@1+ (1,-125) [-125|125] "%" Vector__XXX

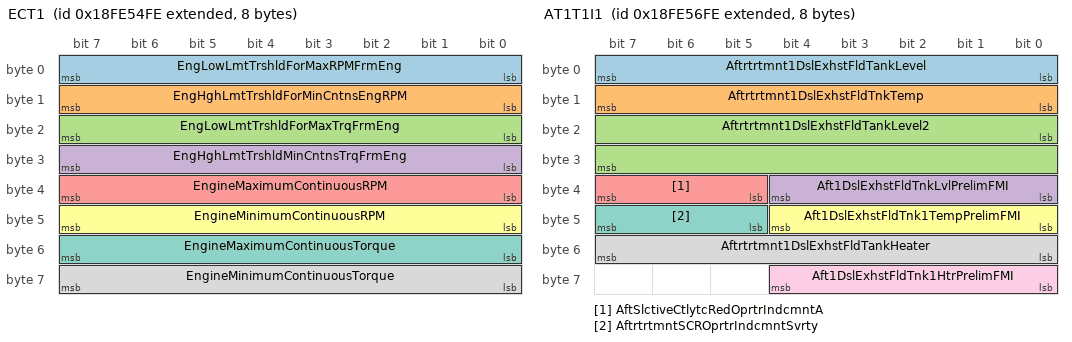
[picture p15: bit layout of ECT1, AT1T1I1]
BO_ 2566804734 ECT1: 8 Vector__XXX
SG_ EngLowLmtTrshldForMaxRPMFrmEng : 0|8@1+ (32,0) [0|8000] "rpm" Vector__XXX
SG_ EngHghLmtTrshldForMinCntnsEngRPM : 8|8@1+ (32,0) [0|8000] "rpm" Vector__XXX
SG_ EngLowLmtTrshldForMaxTrqFrmEng : 16|8@1+ (1,-125) [-125|125] "%" Vector__XXX
SG_ EngHghLmtTrshldMinCntnsTrqFrmEng : 24|8@1+ (1,-125) [-125|125] "%" Vector__XXX
SG_ EngineMaximumContinuousRPM : 32|8@1+ (32,0) [0|8000] "rpm" Vector__XXX
SG_ EngineMinimumContinuousRPM : 40|8@1+ (32,0) [0|8000] "rpm" Vector__XXX
SG_ EngineMaximumContinuousTorque : 48|8@1+ (1,-125) [-125|125] "%" Vector__XXX
SG_ EngineMinimumContinuousTorque : 56|8@1+ (1,-125) [-125|125] "%" Vector__XXX

BO_ 2566804990 GFD: 8 Vector__XXX
SG_ SpecificHeatRatio : 0|16@1+ (0.001,0) [0|64.255] "" Vector__XXX
SG_ ReferenceEngineGasMassFlowRate : 16|16@1+ (0.05,0) [0|3212.75] "kg/h" Vector__XXX
SG_ FuelEnergyContent : 32|16@1+ (0.00390625,0) [0|250.996] "MJ/Nm^3" Vector__XXX

BO_ 2566805246 AT1T1I1: 8 Vector__XXX
SG_ Aftrtrtmnt1DslExhstFldTankLevel : 0|8@1+ (0.4,0) [0|100] "%" Vector__XXX
SG_ Aftrtrtmnt1DslExhstFldTnkTemp : 8|8@1+ (1,-40) [-40|210] "deg C" Vector__XXX
SG_ Aftrtrtmnt1DslExhstFldTankLevel2 : 16|16@1+ (0.1,0) [0|6425.5] "mm" Vector__XXX
SG_ Aft1DslExhstFldTnkLvlPrelimFMI : 32|5@1+ (1,0) [0|31] "" Vector__XXX
SG_ AftSlctiveCtlytcRedOprtrIndcmntA : 37|3@1+ (1,0) [0|7] "" Vector__XXX
SG_ Aft1DslExhstFldTnk1TempPrelimFMI : 40|5@1+ (1,0) [0|31] "" Vector__XXX
SG_ AftrtrtmntSCROprtrIndcmntSvrty : 45|3@1+ (1,0) [0|7] "" Vector__XXX
SG_ Aftrtrtmnt1DslExhstFldTankHeater : 48|8@1+ (0.4,0) [0|100] "%" Vector__XXX
SG_ Aft1DslExhstFldTnk1HtrPrelimFMI : 56|5@1+ (1,0) [0|31] "" Vector__XXX

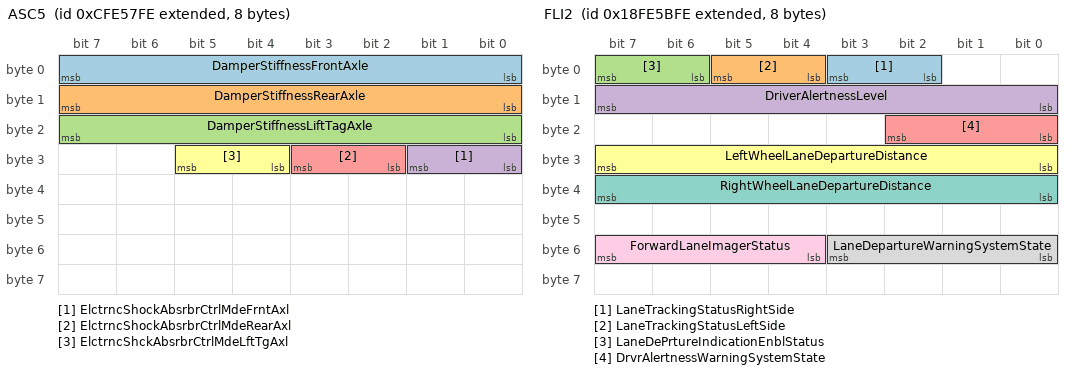
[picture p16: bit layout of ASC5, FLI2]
BO_ 2365478910 ASC5: 8 Vector__XXX
SG_ DamperStiffnessFrontAxle : 0|8@1+ (0.4,0) [0|100] "%" Vector__XXX
SG_ DamperStiffnessRearAxle : 8|8@1+ (0.4,0) [0|100] "%" Vector__XXX
SG_ DamperStiffnessLiftTagAxle : 16|8@1+ (0.4,0) [0|100] "%" Vector__XXX
SG_ ElctrncShockAbsrbrCtrlMdeFrntAxl : 24|2@1+ (1,0) [0|3] "" Vector__XXX
SG_ ElctrncShockAbsrbrCtrlMdeRearAxl : 26|2@1+ (1,0) [0|3] "" Vector__XXX
SG_ ElctrncShckAbsrbrCtrlMdeLftTgAxl : 28|2@1+ (1,0) [0|3] "" Vector__XXX

BO_ 2566805758 ASC4: 8 Vector__XXX
SG_ BellowPressureFrontAxleLeft : 0|16@1+ (0.1,0) [0|6425.5] "kPa" Vector__XXX
SG_ BellowPressureFrontAxleRight : 16|16@1+ (0.1,0) [0|6425.5] "kPa" Vector__XXX
SG_ BellowPressureRearAxleLeft : 32|16@1+ (0.1,0) [0|6425.5] "kPa" Vector__XXX
SG_ BellowPressureRearAxleRight : 48|16@1+ (0.1,0) [0|6425.5] "kPa" Vector__XXX

BO_ 2566806014 ASC3: 8 Vector__XXX
SG_ RelativeLevelFrontAxleLeft : 0|16@1+ (0.1,-3200) [-3200|3225.5] "mm" Vector__XXX
SG_ RelativeLevelFrontAxleRight : 16|16@1+ (0.1,-3200) [-3200|3225.5] "mm" Vector__XXX
SG_ RelativeLevelRearAxleLeft : 32|16@1+ (0.1,-3200) [-3200|3225.5] "mm" Vector__XXX
SG_ RelativeLevelRearAxleRight : 48|16@1+ (0.1,-3200) [-3200|3225.5] "mm" Vector__XXX

BO_ 2365479678 ASC1: 8 Vector__XXX
SG_ NominalLevelFrontAxle : 0|4@1+ (1,0) [0|15] "" Vector__XXX
SG_ NominalLevelRearAxle : 4|4@1+ (1,0) [0|15] "" Vector__XXX
SG_ BelowNominalLevelFrontAxle : 8|2@1+ (1,0) [0|3] "" Vector__XXX
SG_ BelowNominalLevelRearAxle : 10|2@1+ (1,0) [0|3] "" Vector__XXX
SG_ AboveNominalLevelFrontAxle : 12|2@1+ (1,0) [0|3] "" Vector__XXX
SG_ AboveNominalLevelRearAxle : 14|2@1+ (1,0) [0|3] "" Vector__XXX
SG_ LoweringControlModeFrontAxle : 16|2@1+ (1,0) [0|3] "" Vector__XXX
SG_ LoweringControlModeRearAxle : 18|2@1+ (1,0) [0|3] "" Vector__XXX
SG_ LiftingControlModeFrontAxle : 20|2@1+ (1,0) [0|3] "" Vector__XXX
SG_ LiftingControlModeRearAxle : 22|2@1+ (1,0) [0|3] "" Vector__XXX
SG_ KneelingInformation : 24|4@1+ (1,0) [0|15] "" Vector__XXX
SG_ LevelControlMode : 28|4@1+ (1,0) [0|15] "" Vector__XXX
SG_ SecurityDevice : 32|2@1+ (1,0) [0|3] "" Vector__XXX
SG_ VehicleMotionInhibit : 34|2@1+ (1,0) [0|3] "" Vector__XXX
SG_ DoorRelease : 36|2@1+ (1,0) [0|3] "" Vector__XXX
SG_ LiftAxle1Position : 38|2@1+ (1,0) [0|3] "" Vector__XXX
SG_ FrontAxleInBumperRange : 40|2@1+ (1,0) [0|3] "" Vector__XXX
SG_ RearAxleInBumperRange : 42|2@1+ (1,0) [0|3] "" Vector__XXX
SG_ LiftAxle2Position : 46|2@1+ (1,0) [0|3] "" Vector__XXX
SG_ SuspensionRemoteControl1 : 48|2@1+ (1,0) [0|3] "" Vector__XXX
SG_ SuspensionRemoteControl2 : 50|2@1+ (1,0) [0|3] "" Vector__XXX
SG_ AllowLevelCtrlDuringBrkngStatus : 52|2@1+ (1,0) [0|3] "" Vector__XXX
SG_ SpeedDependantLevelControlStatus : 54|2@1+ (1,0) [0|3] "" Vector__XXX
SG_ SuspensionCtrlRefusalInformation : 56|4@1+ (1,0) [0|15] "" Vector__XXX
SG_ MemoryLevel : 60|4@1+ (1,0) [0|15] "" Vector__XXX

BO_ 2566806526 FLI2: 8 Vector__XXX
SG_ LaneTrackingStatusRightSide : 2|2@1+ (1,0) [0|3] "" Vector__XXX
SG_ LaneTrackingStatusLeftSide : 4|2@1+ (1,0) [0|3] "" Vector__XXX
SG_ LaneDePrtureIndicationEnblStatus : 6|2@1+ (1,0) [0|3] "" Vector__XXX
SG_ DriverAlertnessLevel : 8|8@1+ (0.4,0) [0|100] "%" Vector__XXX
SG_ DrvrAlertnessWarningSystemState : 16|3@1+ (1,0) [0|7] "" Vector__XXX
SG_ LeftWheelLaneDepartureDistance : 24|8@1+ (1,-125) [-125|125] "cm" Vector__XXX
SG_ RightWheelLaneDepartureDistance : 32|8@1+ (1,-125) [-125|125] "cm" Vector__XXX
SG_ LaneDepartureWarningSystemState : 48|4@1+ (1,0) [0|15] "" Vector__XXX
SG_ ForwardLaneImagerStatus : 52|4@1+ (1,0) [0|15] "" Vector__XXX

BO_ 2566809342 BM: 8 Vector__XXX
SG_ BatteryMainSwitchHoldState : 0|2@1+ (1,0) [0|3] "" Vector__XXX

BO_ 2566809598 CCC: 8 Vector__XXX
SG_ AuxHeaterMaximumOutputPower : 0|16@1+ (2,0) [0|128510] "W" Vector__XXX

BO_ 2566809854 VF: 8 Vector__XXX
SG_ HydraulicTemperature : 0|8@1+ (1,-40) [-40|210] "deg C" Vector__XXX
SG_ HydrOilFilterRestrictionSwitch : 8|2@1+ (1,0) [0|3] "" Vector__XXX
SG_ WinchOilPressureSwitch : 10|2@1+ (1,0) [0|3] "" Vector__XXX
SG_ HydraulicOilLevel : 16|8@1+ (0.4,0) [0|100] "%" Vector__XXX

BO_ 2566810110 ET3: 8 Vector__XXX
SG_ EngineIntakeManifold1Temperature : 0|16@1+ (0.03125,-273) [-273|1734.96875] "deg C" Vector__XXX
SG_ EngineCoolantTemperature : 16|16@1+ (0.03125,-273) [-273|1734.96875] "deg C" Vector__XXX
SG_ EngIntkValveActSysOilTemperature : 32|16@1+ (0.03125,-273) [-273|1734.96875] "deg C" Vector__XXX
SG_ EngChargeAirCool1OtltTemperature : 48|16@1+ (0.03125,-273) [-273|1734.96875] "deg C" Vector__XXX

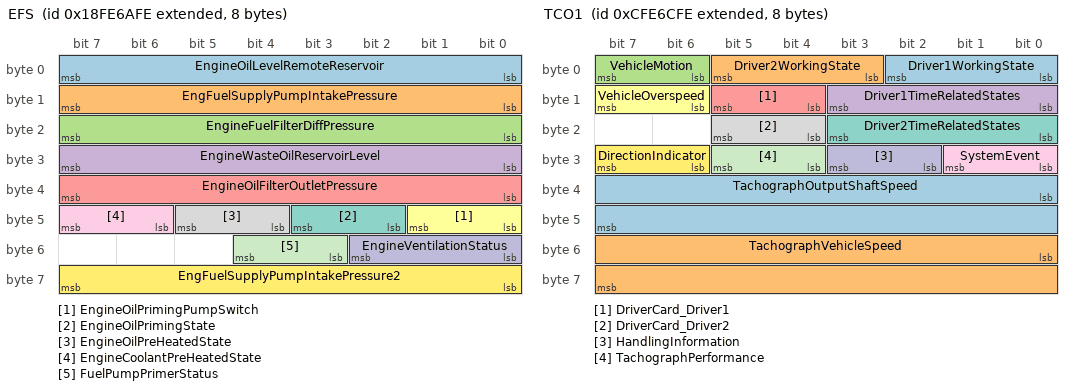
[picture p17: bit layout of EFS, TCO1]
BO_ 2566810366 EFS: 8 Vector__XXX
SG_ EngineOilLevelRemoteReservoir : 0|8@1+ (0.4,0) [0|100] "%" Vector__XXX
SG_ EngFuelSupplyPumpIntakePressure : 8|8@1+ (2,0) [0|500] "kPa" Vector__XXX
SG_ EngineFuelFilterDiffPressure : 16|8@1+ (2,0) [0|500] "kPa" Vector__XXX
SG_ EngineWasteOilReservoirLevel : 24|8@1+ (0.4,0) [0|100] "%" Vector__XXX
SG_ EngineOilFilterOutletPressure : 32|8@1+ (4,0) [0|1000] "kPa" Vector__XXX
SG_ EngineOilPrimingPumpSwitch : 40|2@1+ (1,0) [0|3] "" Vector__XXX
SG_ EngineOilPrimingState : 42|2@1+ (1,0) [0|3] "" Vector__XXX
SG_ EngineOilPreHeatedState : 44|2@1+ (1,0) [0|3] "" Vector__XXX
SG_ EngineCoolantPreHeatedState : 46|2@1+ (1,0) [0|3] "" Vector__XXX
SG_ EngineVentilationStatus : 48|3@1+ (1,0) [0|7] "" Vector__XXX
SG_ FuelPumpPrimerStatus : 51|2@1+ (1,0) [0|3] "" Vector__XXX
SG_ EngFuelSupplyPumpIntakePressure2 : 56|8@1+ (2,0) [0|500] "kPa" Vector__XXX

BO_ 2566810622 DI: 1728 Vector__XXX
SG_ Driver1Identification : 7|13824@0+ (1,0) [0|0] "ASCII" Vector__XXX
SG_ Driver2Identification : 7|13824@0+ (1,0) [0|0] "ASCII" Vector__XXX

BO_ 2365484286 TCO1: 8 Vector__XXX
SG_ Driver1WorkingState : 0|3@1+ (1,0) [0|7] "" Vector__XXX
SG_ Driver2WorkingState : 3|3@1+ (1,0) [0|7] "" Vector__XXX
SG_ VehicleMotion : 6|2@1+ (1,0) [0|3] "" Vector__XXX
SG_ Driver1TimeRelatedStates : 8|4@1+ (1,0) [0|15] "" Vector__XXX
SG_ DriverCard_Driver1 : 12|2@1+ (1,0) [0|3] "" Vector__XXX
SG_ VehicleOverspeed : 14|2@1+ (1,0) [0|3] "" Vector__XXX
SG_ Driver2TimeRelatedStates : 16|4@1+ (1,0) [0|15] "" Vector__XXX
SG_ DriverCard_Driver2 : 20|2@1+ (1,0) [0|3] "" Vector__XXX
SG_ SystemEvent : 24|2@1+ (1,0) [0|3] "" Vector__XXX
SG_ HandlingInformation : 26|2@1+ (1,0) [0|3] "" Vector__XXX
SG_ TachographPerformance : 28|2@1+ (1,0) [0|3] "" Vector__XXX
SG_ DirectionIndicator : 30|2@1+ (1,0) [0|3] "" Vector__XXX
SG_ TachographOutputShaftSpeed : 32|16@1+ (0.125,0) [0|8031.875] "rpm" Vector__XXX
SG_ TachographVehicleSpeed : 48|16@1+ (0.00390625,0) [0|250.996] "km/h" Vector__XXX

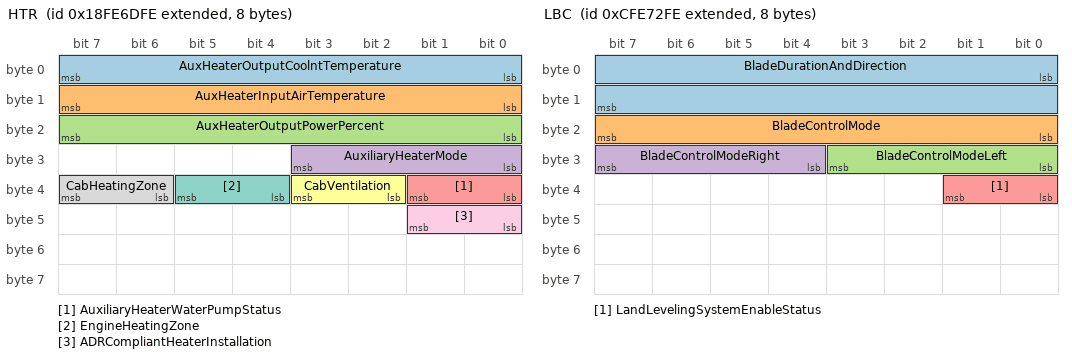
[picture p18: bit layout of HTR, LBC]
BO_ 2566811134 HTR: 8 Vector__XXX
SG_ AuxHeaterOutputCoolntTemperature : 0|8@1+ (1,-40) [-40|210] "deg C" Vector__XXX
SG_ AuxHeaterInputAirTemperature : 8|8@1+ (1,-40) [-40|210] "deg C" Vector__XXX
SG_ AuxHeaterOutputPowerPercent : 16|8@1+ (0.4,0) [0|100] "%" Vector__XXX
SG_ AuxiliaryHeaterMode : 24|4@1+ (1,0) [0|15] "" Vector__XXX
SG_ AuxiliaryHeaterWaterPumpStatus : 32|2@1+ (1,0) [0|3] "" Vector__XXX
SG_ CabVentilation : 34|2@1+ (1,0) [0|3] "" Vector__XXX
SG_ EngineHeatingZone : 36|2@1+ (1,0) [0|3] "" Vector__XXX
SG_ CabHeatingZone : 38|2@1+ (1,0) [0|3] "" Vector__XXX
SG_ ADRCompliantHeaterInstallation : 40|2@1+ (1,0) [0|3] "" Vector__XXX

BO_ 2298375934 HRW: 8 Vector__XXX
SG_ FrontAxle_LeftWheelSpeed : 0|16@1+ (0.00390625,0) [0|250.996] "km/h" Vector__XXX
SG_ FrontAxle_RightWheelSpeed : 16|16@1+ (0.00390625,0) [0|250.996] "km/h" Vector__XXX
SG_ RearAxle_LeftWheelSpeed : 32|16@1+ (0.00390625,0) [0|250.996] "km/h" Vector__XXX
SG_ RearAxle_RightWheelSpeed : 48|16@1+ (0.00390625,0) [0|250.996] "km/h" Vector__XXX

BO_ 2432593918 ACC1: 8 Vector__XXX
SG_ SpeedOfForwardVehicle : 0|8@1+ (1,0) [0|250] "km/h" Vector__XXX
SG_ DistanceToForwardVehicle : 8|8@1+ (1,0) [0|250] "m" Vector__XXX
SG_ AdaptiveCruiseControlSetSpeed : 16|8@1+ (1,0) [0|250] "km/h" Vector__XXX
SG_ AdaptiveCruiseControlMode : 24|3@1+ (1,0) [0|7] "" Vector__XXX
SG_ AdaptiveCruiseCtrlSetDistMode : 27|3@1+ (1,0) [0|7] "" Vector__XXX
SG_ RoadCurvature : 32|16@1+ (0.0078125,-250) [-250|251.992] "1/km" Vector__XXX
SG_ ACCTargetDetected : 48|2@1+ (1,0) [0|3] "" Vector__XXX
SG_ ACCSystemShutoffWarning : 50|2@1+ (1,0) [0|3] "" Vector__XXX
SG_ ACCDistanceAlertSignal : 52|2@1+ (1,0) [0|3] "" Vector__XXX
SG_ ForwardCollisionWarning : 54|2@1+ (1,0) [0|3] "" Vector__XXX

BO_ 2566811902 CVW: 8 Vector__XXX
SG_ PoweredVehicleWeight : 0|16@1+ (10,0) [0|642550] "kg" Vector__XXX
SG_ GrossCombinationVehicleWeight : 16|16@1+ (10,0) [0|642550] "kg" Vector__XXX

BO_ 2365485566 LTP: 8 Vector__XXX
SG_ LaserTracerTargetDeviation : 0|16@1+ (0.1,-3200) [-3200|3225.5] "mm" Vector__XXX
SG_ LaserTracerVerticalDistance : 16|16@1+ (0.1,0) [0|6425.5] "mm" Vector__XXX
SG_ LaserTracerHorizontalDeviation : 32|8@1+ (1,0) [0|250] "%" Vector__XXX
SG_ LEDDisplayData2 : 40|8@1+ (1,0) [0|255] "" Vector__XXX
SG_ LaserTracerInformation : 48|8@1+ (1,0) [0|255] "" Vector__XXX

BO_ 2365485822 LBC: 8 Vector__XXX
SG_ BladeDurationAndDirection : 0|16@1+ (0.1,-3276.8) [-3276.8|3148.7] "s" Vector__XXX
SG_ BladeControlMode : 16|8@1+ (1,0) [0|255] "" Vector__XXX
SG_ BladeControlModeLeft : 24|4@1+ (1,0) [0|15] "" Vector__XXX
SG_ BladeControlModeRight : 28|4@1+ (1,0) [0|15] "" Vector__XXX
SG_ LandLevelingSystemEnableStatus : 32|2@1+ (1,0) [0|3] "" Vector__XXX

BO_ 2365486078 LMP: 8 Vector__XXX
SG_ MastPosition : 0|16@1+ (0.1,-3200) [-3200|3225.5] "mm" Vector__XXX

BO_ 2365486334 LSP: 8 Vector__XXX
SG_ ModifyLevelingSystemSetPoint : 0|16@1+ (0.1,-3200) [-3200|3225.5] "mm" Vector__XXX
SG_ BladeHeightSetPoint : 16|32@1+ (1E-007,-209.7152) [-209.7152|211.3929215] "m" Vector__XXX

BO_ 2365486590 LVD: 8 Vector__XXX
SG_ LaserStrikeVerticalDeviation : 0|16@1+ (0.1,-3200) [-3200|3225.5] "mm" Vector__XXX
SG_ LaserReceiverType : 16|8@1+ (1,0) [0|250] "" Vector__XXX
SG_ LaserStrikeDataLatency : 24|16@1+ (5.12E-005,0) [0|3.289856] "s" Vector__XXX
SG_ AbsoluteLaserStrikePosition : 40|16@1+ (0.1,0) [0|6425.5] "mm" Vector__XXX

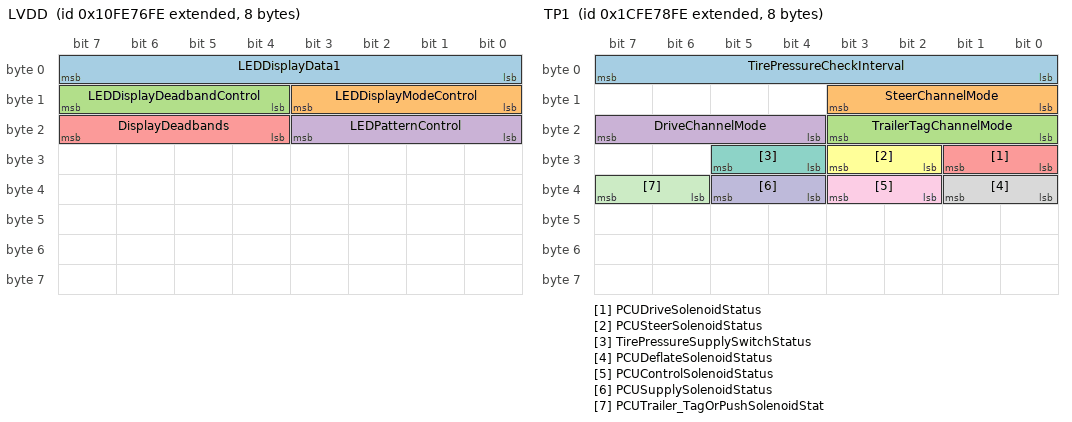
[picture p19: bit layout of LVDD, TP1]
BO_ 2432595710 LVDD: 8 Vector__XXX
SG_ LEDDisplayData1 : 0|8@1+ (1,0) [0|255] "" Vector__XXX
SG_ LEDDisplayModeControl : 8|4@1+ (1,0) [0|15] "" Vector__XXX
SG_ LEDDisplayDeadbandControl : 12|4@1+ (1,0) [0|15] "" Vector__XXX
SG_ LEDPatternControl : 16|4@1+ (1,0) [0|15] "" Vector__XXX
SG_ DisplayDeadbands : 20|4@1+ (1,0) [0|15] "" Vector__XXX

BO_ 2633922558 AP: 8 Vector__XXX
SG_ AuxiliaryVacuumPressureReading : 0|16@1+ (0.5,0) [0|32127.5] "kPa" Vector__XXX
SG_ AuxiliaryGagePressureReading1 : 16|16@1+ (0.5,0) [0|32127.5] "kPa" Vector__XXX
SG_ AuxiliaryAbsolutePressureReading : 32|16@1+ (0.5,0) [0|32127.5] "kPa" Vector__XXX

BO_ 2633922814 TP1: 8 Vector__XXX
SG_ TirePressureCheckInterval : 0|8@1+ (1,0) [0|250] "min" Vector__XXX
SG_ SteerChannelMode : 8|4@1+ (1,0) [0|15] "" Vector__XXX
SG_ TrailerTagChannelMode : 16|4@1+ (1,0) [0|15] "" Vector__XXX
SG_ DriveChannelMode : 20|4@1+ (1,0) [0|15] "" Vector__XXX
SG_ PCUDriveSolenoidStatus : 24|2@1+ (1,0) [0|3] "" Vector__XXX
SG_ PCUSteerSolenoidStatus : 26|2@1+ (1,0) [0|3] "" Vector__XXX
SG_ TirePressureSupplySwitchStatus : 28|2@1+ (1,0) [0|3] "" Vector__XXX
SG_ PCUDeflateSolenoidStatus : 32|2@1+ (1,0) [0|3] "" Vector__XXX
SG_ PCUControlSolenoidStatus : 34|2@1+ (1,0) [0|3] "" Vector__XXX
SG_ PCUSupplySolenoidStatus : 36|2@1+ (1,0) [0|3] "" Vector__XXX
SG_ PCUTrailer_TagOrPushSolenoidStat : 38|2@1+ (1,0) [0|3] "" Vector__XXX

BO_ 2633923070 TP2: 8 Vector__XXX
SG_ Trlr_TgOrPushChnnlTirePrsTarget : 0|16@1+ (0.5,0) [0|32127.5] "kPa" Vector__XXX
SG_ DriveChannelTirePressureTarget : 16|16@1+ (0.5,0) [0|32127.5] "kPa" Vector__XXX
SG_ SteerChannelTirePressureTarget : 32|16@1+ (0.5,0) [0|32127.5] "kPa" Vector__XXX

BO_ 2633923326 TP3: 8 Vector__XXX
SG_ Trailer_TagOrPushChnnlTirePress : 0|16@1+ (0.5,0) [0|32127.5] "kPa" Vector__XXX
SG_ DriveChannelTirePressure : 16|16@1+ (0.5,0) [0|32127.5] "kPa" Vector__XXX
SG_ SteerChannelTirePressure : 32|16@1+ (0.5,0) [0|32127.5] "kPa" Vector__XXX

CM_ BO_ 2566759934 "Door Control 2";
CM_ BO_ 2365433598 "Voltage Regulator Excitation Status";
CM_ BO_ 2633869310 "Voltage Regulator Operating Mode";
CM_ BO_ 2566760702 "Wireless Communications Message 2";
CM_ BO_ 2566760958 "Wireless Communications Message 1";
CM_ BO_ 2566761214 "Engine Fluid Level/Pressure 4";
CM_ BO_ 2566761726 "Engine Fuel Information";
CM_ BO_ 2566761982 "Request For Complete Configurable Message Set";
CM_ BO_ 2566762238 "Fifth Wheel Smart Systems 2";
CM_ BO_ 2566762494 "Aftertreatment 2 Intermediate Gas";
CM_ BO_ 2566762750 "Aftertreatment 2 Outlet Gas 2";
CM_ BO_ 2566763006 "Aftertreatment 2 Intake Gas 2";
CM_ BO_ 2566763262 "Aftertreatment 1 Intermediate Gas";
CM_ BO_ 2566763518 "Aftertreatment 1 Outlet Gas 2";
CM_ BO_ 2566763774 "Aftertreatment 1 Intake Gas 2";
CM_ BO_ 2566764030 "Emission-Related Previously MIL-On Diagnostic Trouble Codes";
CM_ BO_ 2566764286 "SPN Support";
CM_ BO_ 2566764542 "Expanded Freeze Frame";
CM_ BO_ 2566764798 "Diagnostic Readiness 3";
CM_ BO_ 2566765054 "Tire Pressure Reference Information";
CM_ BO_ 2566765310 "Farebox Status";
CM_ BO_ 2566765566 "Farebox Point of Sale";
CM_ BO_ 2566765822 "Farebox Service Detail";
CM_ BO_ 2566766078 "Signal Preemption";
CM_ BO_ 2566766334 "Transit Route";
CM_ BO_ 2566766590 "Transit Milepost";
CM_ BO_ 2566766846 "Passenger Counter";
CM_ BO_ 2566767102 "Engine Fluid Level/Pressure 3";
CM_ BO_ 2566767358 "Electronic Engine Controller 14";
CM_ BO_ 2566767614 "Electronic Engine Controller 15";
CM_ BO_ 2566767870 "Electronic Brake Controller 5";
CM_ BO_ 2566768126 "ECU Identification Information";
CM_ BO_ 2566768382 "Cold Start Aids";
CM_ BO_ 2566768638 "Off-Highway Engine Control Selection States";
CM_ BO_ 2566768894 "Operator Primary Intermediate Speed Control state";
CM_ BO_ 2633878014 "Electronic Control Module Information";
CM_ BO_ 2566769406 "Intermediate Speed Control";
CM_ BO_ 2566769662 "Off-Highway Engine Control Selection";
CM_ BO_ 2365443326 "Operators External Light Controls Message";
CM_ BO_ 2566770174 "Operator Wiper and Washer Controls Message";
CM_ BO_ 2566770430 "Working Set Member Message";
CM_ BO_ 2566770686 "Working Set Master Message";
CM_ BO_ 2566770942 "Intake/Exhaust Conditions 2";
CM_ BO_ 2633880062 "FMS-standard Interface Identity/Capabilities";
CM_ BO_ 2566771454 "ECU Performance";
CM_ BO_ 2566771710 "Turbocharger Information 6";
CM_ BO_ 2566771966 "Cab Message 3";
CM_ BO_ 2566772222 "Electronic Engine Controller 5";
CM_ BO_ 2365445886 "Basic Joystick Message 1";
CM_ BO_ 2365446142 "Extended Joystick Message 1";
CM_ BO_ 2365446398 "Basic Joystick Message 2";
CM_ BO_ 2365446654 "Extended Joystick Message 2";
CM_ BO_ 2365446910 "Basic Joystick Message 3";
CM_ BO_ 2365447166 "Extended Joystick Message 3";
CM_ BO_ 2566774014 "Marine Control Information";
CM_ BO_ 2633883646 "Front Wheel Drive Status";
CM_ BO_ 2566775038 "Ambient Conditions 2";
CM_ BO_ 2566775294 "Cab A/C Climate System Information";
CM_ BO_ 2566775550 "Supply Pressure Demand";
CM_ BO_ 2566775806 "Equipment Operation and Control";
CM_ BO_ 2566776062 "Equipment Performance Data";
CM_ BO_ 2566776318 "Maximum Vehicle Speed Limit Status";
CM_ BO_ 2365449982 "Hydraulic Braking System";
CM_ BO_ 2365450238 "Bus #1/Utility Sync Check Status";
CM_ BO_ 2365450494 "Bus #1/Generator Sync Check Status";
CM_ BO_ 2365450750 "Bus #1 Phase C  Basic AC Quantities";
CM_ BO_ 2365451006 "Bus #1 Phase B  Basic AC Quantities";
CM_ BO_ 2365451262 "Bus #1 Phase A  Basic AC Quantities";
CM_ BO_ 2365451518 "Bus #1 Average Basic AC Quantities";
CM_ BO_ 2365451774 "Utility Total AC Energy";
CM_ BO_ 2365452030 "Utility Phase C AC Reactive Power";
CM_ BO_ 2365452286 "Utility Phase C AC Power";
CM_ BO_ 2365452542 "Utility Phase C AC Basic Quantities";
CM_ BO_ 2365452798 "Utility Phase B AC Reactive Power";
CM_ BO_ 2365453054 "Utility Phase B AC Power";
CM_ BO_ 2365453310 "Utility Phase B AC Basic Quantities";
CM_ BO_ 2365453566 "Utility Phase A AC Reactive Power";
CM_ BO_ 2365453822 "Utility Phase A AC Power";
CM_ BO_ 2365454078 "Utility Phase A Basic AC Quantities";
CM_ BO_ 2365454334 "Utility Total AC Reactive Power";
CM_ BO_ 2365454590 "Utility Total AC Power";
CM_ BO_ 2365454846 "Utility Average Basic AC Quantities";
CM_ BO_ 2365455102 "Generator Total AC Energy";
CM_ BO_ 2365455358 "Generator Phase C AC Reactive Power";
CM_ BO_ 2365455614 "Generator Phase C AC Power";
CM_ BO_ 2365455870 "Generator Phase C Basic AC Quantities";
CM_ BO_ 2365456126 "Generator Phase B AC Reactive Power";
CM_ BO_ 2365456382 "Generator Phase B AC Power";
CM_ BO_ 2365456638 "Generator Phase B Basic AC Quantities";
CM_ BO_ 2365456894 "Generator Phase A AC Reactive Power";
CM_ BO_ 2365457150 "Generator Phase A AC Power";
CM_ BO_ 2365457406 "Generator Phase A Basic AC Quantities";
CM_ BO_ 2365457662 "Generator Total AC Reactive Power";
CM_ BO_ 2365457918 "Generator Total AC Power";
CM_ BO_ 2365458174 "Generator Average Basic AC Quantities";
CM_ BO_ 2566785022 "Exhaust Temperature";
CM_ BO_ 2566786302 "Working Set Member";
CM_ BO_ 2566786558 "Working Set Master";
CM_ BO_ 2566799614 "Lighting Data";
CM_ BO_ 2365473278 "Lighting Command";
CM_ BO_ 2566802174 "Electronic Transmission Controller 7";
CM_ BO_ 2566802430 "Transmission Configuration 2";
CM_ BO_ 2566802686 "Military Lighting Command";
CM_ BO_ 2633911806 "Total Averaged Information";
CM_ BO_ 2566803198 "Door Control 1";
CM_ BO_ 2566803454 "Vehicle Dynamic Stability Control 1";
CM_ BO_ 2566803710 "Battery Temperature";
CM_ BO_ 2566803966 "Adaptive Cruise Control, Operator Input";
CM_ BO_ 2566804222 "Vehicle Electrical Power 3";
CM_ BO_ 2566804478 "Retarder Continuous Torque & Speed Limit";
CM_ BO_ 2566804734 "Engine Continuous Torque & Speed Limit";
CM_ BO_ 2566804990 "Gaseous Fuel Properties";
CM_ BO_ 2566805246 "Aftertreatment 1 Diesel Exhaust Fluid Tank 1 Information 1";
CM_ BO_ 2365478910 "Air Suspension Control 5";
CM_ BO_ 2566805758 "Air Suspension Control 4";
CM_ BO_ 2566806014 "Air Suspension Control 3";
CM_ BO_ 2365479678 "Air Suspension Control 1";
CM_ BO_ 2566806526 "Forward Lane Image 2";
CM_ BO_ 2566809342 "Battery Main Switch Information";
CM_ BO_ 2566809598 "Climate Control Configuration";
CM_ BO_ 2566809854 "Vehicle Fluids";
CM_ BO_ 2566810110 "Engine Temperature 3";
CM_ BO_ 2566810366 "Engine Fuel/lube systems";
CM_ BO_ 2566810622 "Driver's Identification";
CM_ BO_ 2365484286 "Tachograph";
CM_ BO_ 2566811134 "Heater Information";
CM_ BO_ 2298375934 "High Resolution Wheel Speed";
CM_ BO_ 2432593918 "Adaptive Cruise Control 1";
CM_ BO_ 2566811902 "Combination Vehicle Weight";
CM_ BO_ 2365485566 "Laser Tracer Position";
CM_ BO_ 2365485822 "Laser Leveling System Blade Control";
CM_ BO_ 2365486078 "Laser Receiver Mast Position";
CM_ BO_ 2365486334 "Modify Leveling System Control Set Point";
CM_ BO_ 2365486590 "Laser Leveling System Vertical Deviation";
CM_ BO_ 2432595710 "Laser Leveling System Vertical Position Display Data";
CM_ BO_ 2633922558 "Auxiliary Pressures";
CM_ BO_ 2633922814 "Tire Pressure Control Unit Mode and Status";
CM_ BO_ 2633923070 "Tire Pressure Control Unit Target Pressures";
CM_ BO_ 2633923326 "Tire Pressure Control Unit Current Pressures";
BA_DEF_ BO_  "VFrameFormat" ENUM  "StandardCAN","ExtendedCAN","reserved","J1939PG";
BA_DEF_ BO_  "GenMsgCycleTime" INT 0 65535;
BA_DEF_ SG_  "GenSigStartValue" FLOAT -3.4E+038 3.4E+038;
BA_DEF_ SG_  "SPN" INT ;
BA_DEF_ SG_  "SigType" ENUM "Default","Range","RangeSigned","ASCII","Discrete","Control","ReferencePGN","DTC","StringDelimiter","StringLength","StringLengthControl","MessageCounter","MessageChecksum";
BA_DEF_DEF_  "VFrameFormat" "J1939PG";
BA_DEF_DEF_  "GenMsgCycleTime" 0;
BA_DEF_DEF_  "GenSigStartValue" 0;
BA_DEF_DEF_  "SPN" 0;
BA_DEF_DEF_  "SigType" "Default";
BA_ "GenMsgCycleTime" BO_ 2566759934 100;
BA_ "GenMsgCycleTime" BO_ 2365433598 100;
BA_ "GenMsgCycleTime" BO_ 2633869310 1000;
BA_ "GenMsgCycleTime" BO_ 2566761214 500;
BA_ "GenMsgCycleTime" BO_ 2566762494 500;
BA_ "GenMsgCycleTime" BO_ 2566762750 500;
BA_ "GenMsgCycleTime" BO_ 2566763006 500;
BA_ "GenMsgCycleTime" BO_ 2566763262 500;
BA_ "GenMsgCycleTime" BO_ 2566763518 500;
BA_ "GenMsgCycleTime" BO_ 2566763774 500;
BA_ "GenMsgCycleTime" BO_ 2566767102 500;
BA_ "GenMsgCycleTime" BO_ 2566767870 100;
BA_ "GenMsgCycleTime" BO_ 2566768638 500;
BA_ "GenMsgCycleTime" BO_ 2566768894 1000;
BA_ "GenMsgCycleTime" BO_ 2566769406 1000;
BA_ "GenMsgCycleTime" BO_ 2566769662 500;
BA_ "GenMsgCycleTime" BO_ 2365443326 1000;
BA_ "GenMsgCycleTime" BO_ 2566770174 200;
BA_ "GenMsgCycleTime" BO_ 2566770942 500;
BA_ "GenMsgCycleTime" BO_ 2633880062 10000;
BA_ "GenMsgCycleTime" BO_ 2566771710 1000;
BA_ "GenMsgCycleTime" BO_ 2566771966 10000;
BA_ "GenMsgCycleTime" BO_ 2365445886 100;
BA_ "GenMsgCycleTime" BO_ 2365446142 100;
BA_ "GenMsgCycleTime" BO_ 2365446398 100;
BA_ "GenMsgCycleTime" BO_ 2365446654 100;
BA_ "GenMsgCycleTime" BO_ 2365446910 100;
BA_ "GenMsgCycleTime" BO_ 2365447166 100;
BA_ "GenMsgCycleTime" BO_ 2566774014 1000;
BA_ "GenMsgCycleTime" BO_ 2633883646 500;
BA_ "GenMsgCycleTime" BO_ 2566775038 1000;
BA_ "GenMsgCycleTime" BO_ 2566775294 1000;
BA_ "GenMsgCycleTime" BO_ 2566775550 1000;
BA_ "GenMsgCycleTime" BO_ 2566775806 250;
BA_ "GenMsgCycleTime" BO_ 2566776062 500;
BA_ "GenMsgCycleTime" BO_ 2566776318 1000;
BA_ "GenMsgCycleTime" BO_ 2365449982 100;
BA_ "GenMsgCycleTime" BO_ 2365450238 100;
BA_ "GenMsgCycleTime" BO_ 2365450494 100;
BA_ "GenMsgCycleTime" BO_ 2365450750 100;
BA_ "GenMsgCycleTime" BO_ 2365451006 100;
BA_ "GenMsgCycleTime" BO_ 2365451262 100;
BA_ "GenMsgCycleTime" BO_ 2365451518 100;
BA_ "GenMsgCycleTime" BO_ 2365451774 100;
BA_ "GenMsgCycleTime" BO_ 2365452030 100;
BA_ "GenMsgCycleTime" BO_ 2365452286 100;
BA_ "GenMsgCycleTime" BO_ 2365452542 100;
BA_ "GenMsgCycleTime" BO_ 2365452798 100;
BA_ "GenMsgCycleTime" BO_ 2365453054 100;
BA_ "GenMsgCycleTime" BO_ 2365453310 100;
BA_ "GenMsgCycleTime" BO_ 2365453566 100;
BA_ "GenMsgCycleTime" BO_ 2365453822 100;
BA_ "GenMsgCycleTime" BO_ 2365454078 100;
BA_ "GenMsgCycleTime" BO_ 2365454334 100;
BA_ "GenMsgCycleTime" BO_ 2365454590 100;
BA_ "GenMsgCycleTime" BO_ 2365454846 100;
BA_ "GenMsgCycleTime" BO_ 2365455102 100;
BA_ "GenMsgCycleTime" BO_ 2365455358 100;
BA_ "GenMsgCycleTime" BO_ 2365455614 100;
BA_ "GenMsgCycleTime" BO_ 2365455870 100;
BA_ "GenMsgCycleTime" BO_ 2365456126 100;
BA_ "GenMsgCycleTime" BO_ 2365456382 100;
BA_ "GenMsgCycleTime" BO_ 2365456638 100;
BA_ "GenMsgCycleTime" BO_ 2365456894 100;
BA_ "GenMsgCycleTime" BO_ 2365457150 100;
BA_ "GenMsgCycleTime" BO_ 2365457406 100;
BA_ "GenMsgCycleTime" BO_ 2365457662 100;
BA_ "GenMsgCycleTime" BO_ 2365457918 100;
BA_ "GenMsgCycleTime" BO_ 2365458174 100;
BA_ "GenMsgCycleTime" BO_ 2566785022 500;
BA_ "GenMsgCycleTime" BO_ 2365473278 1000;
BA_ "GenMsgCycleTime" BO_ 2566802174 100;
BA_ "GenMsgCycleTime" BO_ 2566802430 5000;
BA_ "GenMsgCycleTime" BO_ 2566802686 500;
BA_ "GenMsgCycleTime" BO_ 2566803198 100;
BA_ "GenMsgCycleTime" BO_ 2566803454 100;
BA_ "GenMsgCycleTime" BO_ 2566803710 1000;
BA_ "GenMsgCycleTime" BO_ 2566803966 250;
BA_ "GenMsgCycleTime" BO_ 2566804222 100;
BA_ "GenMsgCycleTime" BO_ 2566804478 5000;
BA_ "GenMsgCycleTime" BO_ 2566804734 5000;
BA_ "GenMsgCycleTime" BO_ 2566805246 1000;
BA_ "GenMsgCycleTime" BO_ 2365478910 100;
BA_ "GenMsgCycleTime" BO_ 2566805758 100;
BA_ "GenMsgCycleTime" BO_ 2566806014 100;
BA_ "GenMsgCycleTime" BO_ 2365479678 100;
BA_ "GenMsgCycleTime" BO_ 2566806526 100;
BA_ "GenMsgCycleTime" BO_ 2566809342 1000;
BA_ "GenMsgCycleTime" BO_ 2566809854 1000;
BA_ "GenMsgCycleTime" BO_ 2566810110 1000;
BA_ "GenMsgCycleTime" BO_ 2566810366 500;
BA_ "GenMsgCycleTime" BO_ 2365484286 50;
BA_ "GenMsgCycleTime" BO_ 2566811134 1000;
BA_ "GenMsgCycleTime" BO_ 2298375934 20;
BA_ "GenMsgCycleTime" BO_ 2432593918 100;
BA_ "GenMsgCycleTime" BO_ 2365485566 50;
BA_ "GenMsgCycleTime" BO_ 2365485822 50;
BA_ "GenMsgCycleTime" BO_ 2365486078 50;
BA_ "GenMsgCycleTime" BO_ 2365486334 50;
BA_ "GenMsgCycleTime" BO_ 2365486590 50;
BA_ "GenMsgCycleTime" BO_ 2432595710 100;
BA_ "SPN" SG_ 2566759934 LockStatusOfDoor1 3412;
BA_ "SPN" SG_ 2566759934 OpenStatusOfDoor1 3413;
BA_ "SPN" SG_ 2566759934 EnableStatusOfDoor1 3414;
BA_ "SPN" SG_ 2566759934 LockStatusOfDoor2 3415;
BA_ "SPN" SG_ 2566759934 OpenStatusOfDoor2 3416;
BA_ "SPN" SG_ 2566759934 EnableStatusOfDoor2 3417;
BA_ "SPN" SG_ 2566759934 LockStatusOfDoor3 3418;
BA_ "SPN" SG_ 2566759934 OpenStatusOfDoor3 3419;
BA_ "SPN" SG_ 2566759934 EnableStatusOfDoor3 3420;
BA_ "SPN" SG_ 2566759934 LockStatusOfDoor4 3421;
BA_ "SPN" SG_ 2566759934 OpenStatusOfDoor4 3422;
BA_ "SPN" SG_ 2566759934 EnableStatusOfDoor4 3423;
BA_ "SPN" SG_ 2566759934 LockStatusOfDoor5 3424;
BA_ "SPN" SG_ 2566759934 OpenStatusOfDoor5 3425;
BA_ "SPN" SG_ 2566759934 EnableStatusOfDoor5 3426;
BA_ "SPN" SG_ 2566759934 LockStatusOfDoor6 3427;
BA_ "SPN" SG_ 2566759934 OpenStatusOfDoor6 3428;
BA_ "SPN" SG_ 2566759934 EnableStatusOfDoor6 3429;
BA_ "SPN" SG_ 2566759934 LockStatusOfDoor7 3430;
BA_ "SPN" SG_ 2566759934 OpenStatusOfDoor7 3431;
BA_ "SPN" SG_ 2566759934 EnableStatusOfDoor7 3432;
BA_ "SPN" SG_ 2566759934 LockStatusOfDoor8 3433;
BA_ "SPN" SG_ 2566759934 OpenStatusOfDoor8 3434;
BA_ "SPN" SG_ 2566759934 EnableStatusOfDoor8 3435;
BA_ "SPN" SG_ 2566759934 LockStatusOfDoor9 3436;
BA_ "SPN" SG_ 2566759934 OpenStatusOfDoor9 3437;
BA_ "SPN" SG_ 2566759934 EnableStatusOfDoor9 3438;
BA_ "SPN" SG_ 2566759934 LockStatusOfDoor10 3439;
BA_ "SPN" SG_ 2566759934 OpenStatusOfDoor10 3440;
BA_ "SPN" SG_ 2566759934 EnableStatusOfDoor10 3441;
BA_ "SPN" SG_ 2365433598 GeneratorExcitationFieldVoltage 3380;
BA_ "SPN" SG_ 2365433598 GeneratorExcitationFieldCurrent 3381;
BA_ "SPN" SG_ 2365433598 GenOutputVoltageBiasPercentage 3382;
BA_ "SPN" SG_ 2633869310 VoltageRegulatorLoadCmpnstnMode 3375;
BA_ "SPN" SG_ 2633869310 VltgRgltrVArPwrFactorOprtngMde 3376;
BA_ "SPN" SG_ 2633869310 VltgRgltrUnderFreqCmpnstnEnbld 3377;
BA_ "SPN" SG_ 2633869310 VoltageRegulatorSoftStartState 3378;
BA_ "SPN" SG_ 2633869310 VoltageRegulatorEnabled 3379;
BA_ "SPN" SG_ 2566760702 NetworkTransceiverStatus2 3442;
BA_ "SPN" SG_ 2566760702 NetworkServiceStatus2 3443;
BA_ "SPN" SG_ 2566760702 NetworkAntennaStatus2 3444;
BA_ "SPN" SG_ 2566760702 NetworkSignalStrength2 3445;
BA_ "SPN" SG_ 2566760702 WirelessCommNetworkType2 3446;
BA_ "SPN" SG_ 2566760958 NetworkTransceiverStatus1 3368;
BA_ "SPN" SG_ 2566760958 NetworkServiceStatus1 3369;
BA_ "SPN" SG_ 2566760958 NetworkAntennaStatus1 3370;
BA_ "SPN" SG_ 2566760958 NetworkSignalStrength1 3371;
BA_ "SPN" SG_ 2566760958 WirelessCommNetworkType1 3372;
BA_ "SPN" SG_ 2566761214 EngChargeAirCool1IntakePressure 3340;
BA_ "SPN" SG_ 2566761214 EngChargeAirCool2IntakePressure 3341;
BA_ "SPN" SG_ 2566761214 EngineCoolntPumpDiffPressure 3342;
BA_ "SPN" SG_ 2566761214 EngineCentrifugalOilFilterSpeed 3343;
BA_ "SPN" SG_ 2566761214 EngineChargeAirCoolerCoolntLevel 3668;
BA_ "SPN" SG_ 2566761214 EngineAftercoolerCoolantLevel 3676;
BA_ "SPN" SG_ 2566761214 EngChargeAirCoolOutletPressure 2631;
BA_ "SPN" SG_ 2566761726 NoFuelCnsmptnMontingTransducers 2777;
BA_ "SPN" SG_ 2566761726 EngineIdleFuelFlowRateThreshold 2778;
BA_ "SPN" SG_ 2566761982 MessageSelectionControl 3329;
BA_ "SPN" SG_ 2566761982 PGNOfConfigurableMessageDesired 3330;
BA_ "SPN" SG_ 2566762238 FifthWheelErrorStatus 3307;
BA_ "SPN" SG_ 2566762238 FifthWheelLockRdyToCoupleIndictr 3312;
BA_ "SPN" SG_ 2566762238 FifthWheelLockCoupleStatIndictr 3313;
BA_ "SPN" SG_ 2566762238 FifthWheelSliderPosition 3311;
BA_ "SPN" SG_ 2566762238 FifthWheelSliderLockIndicator 3316;
BA_ "SPN" SG_ 2566762494 Aftrtrtmnt2ExhaustTemperature2 3283;
BA_ "SPN" SG_ 2566762494 Aftrtrtmnt2DslPFIntrmedTemp 3284;
BA_ "SPN" SG_ 2566762494 Aftrtrtmnt2DslPFDiffPressure 3285;
BA_ "SPN" SG_ 2566762494 Aftrtrtmnt2ExhstTemp2PrelimFMI 3286;
BA_ "SPN" SG_ 2566762494 Aft2DslPFDeltaPressPrelimFMI 3287;
BA_ "SPN" SG_ 2566762494 Aft2DslPFIntrmedTempPrelimFMI 3288;
BA_ "SPN" SG_ 2566762750 Aftrtrtmnt2ExhaustTemperature3 3279;
BA_ "SPN" SG_ 2566762750 Aftrtrtmnt2DslPFOtltTemperature 3280;
BA_ "SPN" SG_ 2566762750 Aftrtrtmnt2ExhstTemp3PrelimFMI 3281;
BA_ "SPN" SG_ 2566762750 Aft2DslPFExhstTempPrelimFMI 3282;
BA_ "SPN" SG_ 2566763006 Aftrtrtmnt2ExhaustTemperature1 3275;
BA_ "SPN" SG_ 2566763006 Aftrtrtmnt2DslPFIntkTemperature 3276;
BA_ "SPN" SG_ 2566763006 Aftrtrtmnt2ExhstTemp1PrelimFMI 3277;
BA_ "SPN" SG_ 2566763006 Aft2DslPFIntkTempPrelimFMI 3278;
BA_ "SPN" SG_ 2566763262 Aftrtrtmnt1ExhaustTemperature2 3249;
BA_ "SPN" SG_ 2566763262 Aftrtrtmnt1DslPFIntrmedTemp 3250;
BA_ "SPN" SG_ 2566763262 Aftrtrtmnt1DslPFDiffPressure 3251;
BA_ "SPN" SG_ 2566763262 Aftrtrtmnt1ExhstTemp2PrelimFMI 3252;
BA_ "SPN" SG_ 2566763262 Aft1DslPFDeltaPressPrelimFMI 3253;
BA_ "SPN" SG_ 2566763262 Aft1DslPFIntrmedTempPrelimFMI 3254;
BA_ "SPN" SG_ 2566763518 Aftrtrtmnt1ExhaustTemperature3 3245;
BA_ "SPN" SG_ 2566763518 Aftrtrtmnt1DslPFOtltTemperature 3246;
BA_ "SPN" SG_ 2566763518 Aftrtrtmnt1ExhstTemp3PrelimFMI 3247;
BA_ "SPN" SG_ 2566763518 Aft1DslPFOtltExhstTempPrelimFMI 3248;
BA_ "SPN" SG_ 2566763774 Aftrtrtmnt1ExhaustTemperature1 3241;
BA_ "SPN" SG_ 2566763774 Aftrtrtmnt1DslPFIntkTemperature 3242;
BA_ "SPN" SG_ 2566763774 Aftrtrtmnt1ExhstTemp1PrelimFMI 3243;
BA_ "SPN" SG_ 2566763774 Aft1DslPFIntkTempPrelimFMI 3244;
BA_ "SPN" SG_ 2566764030 ProtectLamp 987;
BA_ "SPN" SG_ 2566764030 AmberWarningLamp 624;
BA_ "SPN" SG_ 2566764030 RedStopLamp 623;
BA_ "SPN" SG_ 2566764030 MalfunctionIndicatorLamp 1213;
BA_ "SPN" SG_ 2566764030 FlashProtectLamp 3041;
BA_ "SPN" SG_ 2566764030 FlashAmberWarningLamp 3040;
BA_ "SPN" SG_ 2566764030 FlashRedStopLamp 3039;
BA_ "SPN" SG_ 2566764030 FlashMalfunctionIndicatorLamp 3038;
BA_ "SPN" SG_ 2566764030 SuspectParameterNumber 1214;
BA_ "SPN" SG_ 2566764030 FailureModeIdentifier 1215;
BA_ "SPN" SG_ 2566764030 OccurrenceCount 1216;
BA_ "SPN" SG_ 2566764030 SPNConversionMethod 1706;
BA_ "SPN" SG_ 2566764286 SPNSupported 3297;
BA_ "SPN" SG_ 2566764286 SupportedInExpandedFreezeFrame 4100;
BA_ "SPN" SG_ 2566764286 SupportedInDataStream 4101;
BA_ "SPN" SG_ 2566764286 SupportedInScaledTestResults 4102;
BA_ "SPN" SG_ 2566764286 SPNDataLength 4103;
BA_ "SPN" SG_ 2566764542 ExpandedFreezeFrameLength 3300;
BA_ "SPN" SG_ 2566764542 SuspectParameterNumber 1214;
BA_ "SPN" SG_ 2566764542 FailureModeIdentifier 1215;
BA_ "SPN" SG_ 2566764542 OccurrenceCount 1216;
BA_ "SPN" SG_ 2566764542 SPNConversionMethod 1706;
BA_ "SPN" SG_ 2566764542 SPNData 1545;
BA_ "SPN" SG_ 2566764798 TimeSinceEngineStart 3301;
BA_ "SPN" SG_ 2566764798 NoWarmUpsSncDiagTroubleCodesClrd 3302;
BA_ "SPN" SG_ 2566764798 CntinlyMontrdSysEnbldCmpltdStat 3303;
BA_ "SPN" SG_ 2566764798 NonCntinlyMontrdSystemsEnbldStat 3304;
BA_ "SPN" SG_ 2566764798 NonCntinlyMontrdSysCompleteStat 3305;
BA_ "SPN" SG_ 2566765054 TireLocation 3190;
BA_ "SPN" SG_ 2566765054 ReferenceTirePressure 3191;
BA_ "SPN" SG_ 2566765310 FareboxEmergencyStatus 3179;
BA_ "SPN" SG_ 2566765310 FareboxAlarmIdentifier 3181;
BA_ "SPN" SG_ 2566765566 TransactionType 3170;
BA_ "SPN" SG_ 2566765566 PassengerType 3171;
BA_ "SPN" SG_ 2566765566 TypeOfFare 3176;
BA_ "SPN" SG_ 2566765566 PaymentDetails 3177;
BA_ "SPN" SG_ 2566765566 FareValidity 3165;
BA_ "SPN" SG_ 2566765566 PassCategory 3166;
BA_ "SPN" SG_ 2566765566 InitialFareAgency 3167;
BA_ "SPN" SG_ 2566765566 TypeOfService 3172;
BA_ "SPN" SG_ 2566765566 TransferType 3173;
BA_ "SPN" SG_ 2566765566 RouteNumber 3169;
BA_ "SPN" SG_ 2566765566 TransferSold 3168;
BA_ "SPN" SG_ 2566765822 FareboxServiceStatus 3178;
BA_ "SPN" SG_ 2566765822 TripStatus 3180;
BA_ "SPN" SG_ 2566765822 TripDirection 3174;
BA_ "SPN" SG_ 2566765822 FarePresets 3175;
BA_ "SPN" SG_ 2566765822 TripNumber 3159;
BA_ "SPN" SG_ 2566765822 PatternNumber 3161;
BA_ "SPN" SG_ 2566765822 AssignedRoute 3160;
BA_ "SPN" SG_ 2566765822 AssignedRun 3162;
BA_ "SPN" SG_ 2566765822 AssignedBlock 3163;
BA_ "SPN" SG_ 2566765822 DriversFareboxSecurityCode 3164;
BA_ "SPN" SG_ 2566766078 RangeCodeEnable 3081;
BA_ "SPN" SG_ 2566766078 TransitRouteIDUsage 3080;
BA_ "SPN" SG_ 2566766078 IntersectionPreemptionRqResponse 3079;
BA_ "SPN" SG_ 2566766078 PriorityOfResponseSentByEmitter 3084;
BA_ "SPN" SG_ 2566766078 TransitDoorEnable 3083;
BA_ "SPN" SG_ 2566766078 StrobeActivationControlStatus 3082;
BA_ "SPN" SG_ 2566766078 VehicleID 3085;
BA_ "SPN" SG_ 2566766334 Agency 3078;
BA_ "SPN" SG_ 2566766334 NoOfBytsInTrnstAssgndRteIdntty 3071;
BA_ "SPN" SG_ 2566766334 NoOfBytsInTrnstAssgndRunIdntty 3072;
BA_ "SPN" SG_ 2566766334 NoOfBytsInTrnstAssgndBlckIdntty 3073;
BA_ "SPN" SG_ 2566766590 NoOfBytsInMilePstIdentification 3070;
BA_ "SPN" SG_ 2566766590 MilepostIdentification 509;
BA_ "SPN" SG_ 2566766846 TypeOfPassengerCount 3043;
BA_ "SPN" SG_ 2566766846 PatronCount 3047;
BA_ "SPN" SG_ 2566766846 SilentAlarmStatus 3044;
BA_ "SPN" SG_ 2566766846 VehicleUseStatus 3045;
BA_ "SPN" SG_ 2566766846 TransitRunStatus 3046;
BA_ "SPN" SG_ 2566767102 EngIntkValveActSystemOilPressure 2948;
BA_ "SPN" SG_ 2566767102 EngExhstGasRecirc1IntkPress 3358;
BA_ "SPN" SG_ 2566767102 EngExhstValveActSystemOilPress 4287;
BA_ "SPN" SG_ 2566767102 EngExhstGasRecirc1OtltPress 5019;
BA_ "SPN" SG_ 2566767102 EngineThrottleValve1DiffPressure 5631;
BA_ "SPN" SG_ 2566767358 EngExhstGasRecirc1Valve1PosError 5829;
BA_ "SPN" SG_ 2566767358 EngExhstGasRecirc1Valve2PosError 5830;
BA_ "SPN" SG_ 2566767358 EngineFuelMassFlowRate 5833;
BA_ "SPN" SG_ 2566767358 FuelType 5837;
BA_ "SPN" SG_ 2566767358 EngineFuelIsolationControl 7394;
BA_ "SPN" SG_ 2566767614 AcceleratorPedal1Channel2 2623;
BA_ "SPN" SG_ 2566767614 AcceleratorPedal1Channel3 2624;
BA_ "SPN" SG_ 2566767614 AcceleratorPedal2Channel2 2625;
BA_ "SPN" SG_ 2566767614 AcceleratorPedal2Channel3 2626;
BA_ "SPN" SG_ 2566767614 EngExhstGasRestrictionValveCtrl 8150;
BA_ "SPN" SG_ 2566767870 BrakeTemperatureWarning 3839;
BA_ "SPN" SG_ 2566767870 HaltBrakeMode 2913;
BA_ "SPN" SG_ 2566767870 HillHolderMode 2912;
BA_ "SPN" SG_ 2566767870 FoundationBrakeUse 2919;
BA_ "SPN" SG_ 2566767870 XBRSystemState 2917;
BA_ "SPN" SG_ 2566767870 XBRActiveControlMode 2918;
BA_ "SPN" SG_ 2566767870 XBRAccelerationLimit 2921;
BA_ "SPN" SG_ 2566767870 ParkingBrakeActuatorFullyActvtd 5275;
BA_ "SPN" SG_ 2566767870 EmergencyBrakingActive 5847;
BA_ "SPN" SG_ 2566767870 RailroadMode 7942;
BA_ "SPN" SG_ 2566768126 ECUHardwareID 6714;
BA_ "SPN" SG_ 2566768382 EngineStartEnableDevice1 626;
BA_ "SPN" SG_ 2566768382 EngineStartEnableDevice2 1804;
BA_ "SPN" SG_ 2566768382 EngineStartEnableDevice1Conf 2899;
BA_ "SPN" SG_ 2566768382 EngineStartEnableDevice2Conf 2898;
BA_ "SPN" SG_ 2566768382 EngineColdStartFuelIgniterCmd 5548;
BA_ "SPN" SG_ 2566768382 EngineColdStartFuelIgniterRelay 5549;
BA_ "SPN" SG_ 2566768382 EngColdStartFuelIgntrRelayFdbck 5550;
BA_ "SPN" SG_ 2566768638 EngineAuxiliaryGovernorState 2896;
BA_ "SPN" SG_ 2566768638 EngineMultiUnitSyncState 2890;
BA_ "SPN" SG_ 2566768638 EngineAltLowIdleSelectState 2891;
BA_ "SPN" SG_ 2566768638 EngineAlternateRatingSelectState 2888;
BA_ "SPN" SG_ 2566768638 EngineDroopAccl1SelectState 2889;
BA_ "SPN" SG_ 2566768638 EngineAltDroopAccl2SelectState 2893;
BA_ "SPN" SG_ 2566768638 EngineDroopRemoteAcclSelectState 2894;
BA_ "SPN" SG_ 2566768638 EngineDroopAuxInputSelectState 2895;
BA_ "SPN" SG_ 2566768638 EngineTorqueCurveSelection 1568;
BA_ "SPN" SG_ 2566768638 EngineOperatingModeSelection 8664;
BA_ "SPN" SG_ 2566768894 EngOprtrPrmryIntrmedSpdSlctState 2892;
BA_ "SPN" SG_ 2633878014 TotalCountOfConfChangesMade 2887;
BA_ "SPN" SG_ 2566769406 EngOprtrPrmryIntrmedSpeedSelect 2880;
BA_ "SPN" SG_ 2566769662 EngineAuxiliaryGovernorSwitch 2884;
BA_ "SPN" SG_ 2566769662 EngineSynchronizationSwitch 1377;
BA_ "SPN" SG_ 2566769662 EngineAlternateLowIdleSwitch 2883;
BA_ "SPN" SG_ 2566769662 EngineAlternateRatingSelect 2882;
BA_ "SPN" SG_ 2566769662 EngineDroopAccelerator1Select 2881;
BA_ "SPN" SG_ 2566769662 EngineDroopAccelerator2Select 2879;
BA_ "SPN" SG_ 2566769662 EngineDroopRemoteAcclSelect 2886;
BA_ "SPN" SG_ 2566769662 EngineDroopAuxiliaryInputSelect 2885;
BA_ "SPN" SG_ 2566769662 EngineTorqueCurveSelectionCmd 6796;
BA_ "SPN" SG_ 2566769662 EngineOperatingModeCommand 8608;
BA_ "SPN" SG_ 2365443326 WorkLightSwitch 2873;
BA_ "SPN" SG_ 2365443326 MainLightSwitch 2872;
BA_ "SPN" SG_ 2365443326 TurnSignalSwitch 2876;
BA_ "SPN" SG_ 2365443326 HazardLightSwitch 2875;
BA_ "SPN" SG_ 2365443326 HighLowBeamSwitch 2874;
BA_ "SPN" SG_ 2365443326 OperatorsDesiredBackLight 2878;
BA_ "SPN" SG_ 2365443326 OperatorsDsrdDelayedLampOffTime 2877;
BA_ "SPN" SG_ 2566770174 FrontNonOperatorWiperSwitch 2864;
BA_ "SPN" SG_ 2566770174 FrontOperatorWiperSwitch 2863;
BA_ "SPN" SG_ 2566770174 RearWiperSwitch 2865;
BA_ "SPN" SG_ 2566770174 FrontOperatorWiperDelayControl 2869;
BA_ "SPN" SG_ 2566770174 FrontNonOperatorWiperDelayCtrl 2870;
BA_ "SPN" SG_ 2566770174 RearWiperDelayControl 2871;
BA_ "SPN" SG_ 2566770174 FrontNonOperatorWasherSwitch 2867;
BA_ "SPN" SG_ 2566770174 FrontOperatorWasherSwitch 2866;
BA_ "SPN" SG_ 2566770174 RearWasherFunction 2868;
BA_ "SPN" SG_ 2566770430 NAMEOfWorkingSetMember 2845;
BA_ "SPN" SG_ 2566770686 NumberOfMembersInWorkingSet 2409;
BA_ "SPN" SG_ 2566770942 EngineAirFilter2DiffPressure 2809;
BA_ "SPN" SG_ 2566770942 EngineAirFilter3DiffPressure 2810;
BA_ "SPN" SG_ 2566770942 EngineAirFilter4DiffPressure 2811;
BA_ "SPN" SG_ 2566770942 EngineIntakeManifold2Pressure 3562;
BA_ "SPN" SG_ 2566770942 EngineIntakeManifold1AbsPressure 3563;
BA_ "SPN" SG_ 2566770942 EngineIntkManifld1AbsPressHghRes 4817;
BA_ "SPN" SG_ 2566770942 EngineIntakeManifold2AbsPressure 5422;
BA_ "SPN" SG_ 2633880062 FMSStandardDiagnosticsSupported 2804;
BA_ "SPN" SG_ 2633880062 FMSStandardRequestsSupported 2805;
BA_ "SPN" SG_ 2633880062 FMSStandardSWVersionSupported 2806;
BA_ "SPN" SG_ 2566771454 KeepAliveBatteryConsumption 2803;
BA_ "SPN" SG_ 2566771454 DataMemoryUsage 2802;
BA_ "SPN" SG_ 2566771710 EngTurbocharger1CmprssorOtltTemp 2629;
BA_ "SPN" SG_ 2566771710 EngTurbocharger2CmprssorOtltTemp 2799;
BA_ "SPN" SG_ 2566771710 EngTurbocharger3CmprssorOtltTemp 2800;
BA_ "SPN" SG_ 2566771710 EngTurbocharger4CmprssorOtltTemp 2801;
BA_ "SPN" SG_ 2566771966 TransferCaseSelectorSwitch 2796;
BA_ "SPN" SG_ 2566771966 FifthWheelReleaseControl 3314;
BA_ "SPN" SG_ 2566771966 FifthWhlReleaseCtrlSecurityLckt 3315;
BA_ "SPN" SG_ 2566771966 VehicleTrailerStatus 7711;
BA_ "SPN" SG_ 2566771966 TransmissionOilLevelRequest 3809;
BA_ "SPN" SG_ 2566772222 EngTurbo1ClclatdTurbineIntkTemp 2789;
BA_ "SPN" SG_ 2566772222 EngTurbo1ClclatdTurbineOtltTemp 2790;
BA_ "SPN" SG_ 2566772222 EngExhstGasRecirc1Valve1Ctrl1 2791;
BA_ "SPN" SG_ 2566772222 EngVarGmtryTurboAirCtrlShtoffVlv 2792;
BA_ "SPN" SG_ 2566772222 EngineFuelControlMode 5323;
BA_ "SPN" SG_ 2566772222 EngVariableGmtryTurbo1CtrlMde 5457;
BA_ "SPN" SG_ 2566772222 EngVariableGmtryTurbo1ActrPos 2795;
BA_ "SPN" SG_ 2365445886 Jystck1XAxsNeutralPositionStatus 2675;
BA_ "SPN" SG_ 2365445886 Jystck1XAxsLvrLftNegPosStatus 2670;
BA_ "SPN" SG_ 2365445886 Jystck1XAxsLvrRightPstvPosStatus 2665;
BA_ "SPN" SG_ 2365445886 Joystick1XAxisPosition 2660;
BA_ "SPN" SG_ 2365445886 Jystck1YAxsNeutralPositionStatus 2676;
BA_ "SPN" SG_ 2365445886 Jystck1YAxsLvrBackNegPosStatus 2671;
BA_ "SPN" SG_ 2365445886 Jystck1YAxsLvrFrwdPstvPosStatus 2666;
BA_ "SPN" SG_ 2365445886 Joystick1YAxisPosition 2661;
BA_ "SPN" SG_ 2365445886 Jystck1YAxsDetentPositionStatus 2681;
BA_ "SPN" SG_ 2365445886 Jystck1XAxsDetentPositionStatus 2680;
BA_ "SPN" SG_ 2365445886 Joystick1Button4PressedStatus 2688;
BA_ "SPN" SG_ 2365445886 Joystick1Button3PressedStatus 2687;
BA_ "SPN" SG_ 2365445886 Joystick1Button2PressedStatus 2686;
BA_ "SPN" SG_ 2365445886 Joystick1Button1PressedStatus 2685;
BA_ "SPN" SG_ 2365445886 Joystick1Button8PressedStatus 2692;
BA_ "SPN" SG_ 2365445886 Joystick1Button7PressedStatus 2691;
BA_ "SPN" SG_ 2365445886 Joystick1Button6PressedStatus 2690;
BA_ "SPN" SG_ 2365445886 Joystick1Button5PressedStatus 2689;
BA_ "SPN" SG_ 2365445886 Joystick1Button12PressedStatus 2696;
BA_ "SPN" SG_ 2365445886 Joystick1Button11PressedStatus 2695;
BA_ "SPN" SG_ 2365445886 Joystick1Button10PressedStatus 2694;
BA_ "SPN" SG_ 2365445886 Joystick1Button9PressedStatus 2693;
BA_ "SPN" SG_ 2365446142 Jystck1GrpXAxsNtrlPositionStatus 2677;
BA_ "SPN" SG_ 2365446142 Jystck1GrpXAxsLvrLftNegPosStatus 2672;
BA_ "SPN" SG_ 2365446142 Jystck1GrpXAxsLvrRghtPstvPosStat 2667;
BA_ "SPN" SG_ 2365446142 Joystick1GripXAxisPosition 2662;
BA_ "SPN" SG_ 2365446142 Jystck1GrpYAxsNtrlPositionStatus 2678;
BA_ "SPN" SG_ 2365446142 Jystck1GrpYAxsLvrBackNegPosStat 2673;
BA_ "SPN" SG_ 2365446142 Jystck1GrpYAxsLvrFrwdPstvPosStat 2668;
BA_ "SPN" SG_ 2365446142 Joystick1GripYAxisPosition 2663;
BA_ "SPN" SG_ 2365446142 Jystck1ThetaAxsNtrlPosStatus 2679;
BA_ "SPN" SG_ 2365446142 Jystck1ThtAxsCntrClckwsNegPsStat 2674;
BA_ "SPN" SG_ 2365446142 Jystck1ThetaAxsClckwsPstvPosStat 2669;
BA_ "SPN" SG_ 2365446142 Joystick1ThetaAxisPosition 2664;
BA_ "SPN" SG_ 2365446142 Jystck1ThetaAxsDetentPosStatus 2684;
BA_ "SPN" SG_ 2365446142 Jystck1GrpYAxsDetentPosStatus 2683;
BA_ "SPN" SG_ 2365446142 Jystck1GrpXAxsDetentPosStatus 2682;
BA_ "SPN" SG_ 2365446142 Joystick1Button16PressedStatus 6734;
BA_ "SPN" SG_ 2365446142 Joystick1Button15PressedStatus 6733;
BA_ "SPN" SG_ 2365446142 Joystick1Button14PressedStatus 6732;
BA_ "SPN" SG_ 2365446142 Joystick1Button13PressedStatus 6731;
BA_ "SPN" SG_ 2365446398 Jystck2XAxsNeutralPositionStatus 2712;
BA_ "SPN" SG_ 2365446398 Jystck2XAxsLvrLftNegPosStatus 2707;
BA_ "SPN" SG_ 2365446398 Jystck2XAxsLvrRightPstvPosStatus 2702;
BA_ "SPN" SG_ 2365446398 Joystick2XAxisPosition 2697;
BA_ "SPN" SG_ 2365446398 Jystck2YAxsNeutralPositionStatus 2713;
BA_ "SPN" SG_ 2365446398 Jystck2YAxsLvrBackNegPosStatus 2708;
BA_ "SPN" SG_ 2365446398 Jystck2YAxsLvrFrwdPstvPosStatus 2703;
BA_ "SPN" SG_ 2365446398 Joystick2YAxisPosition 2698;
BA_ "SPN" SG_ 2365446398 Jystck2YAxsDetentPositionStatus 2718;
BA_ "SPN" SG_ 2365446398 Jystck2XAxsDetentPositionStatus 2717;
BA_ "SPN" SG_ 2365446398 Joystick2Button4PressedStatus 2725;
BA_ "SPN" SG_ 2365446398 Joystick2Button3PressedStatus 2724;
BA_ "SPN" SG_ 2365446398 Joystick2Button2PressedStatus 2723;
BA_ "SPN" SG_ 2365446398 Joystick2Button1PressedStatus 2722;
BA_ "SPN" SG_ 2365446398 Joystick2Button8PressedStatus 2729;
BA_ "SPN" SG_ 2365446398 Joystick2Button7PressedStatus 2728;
BA_ "SPN" SG_ 2365446398 Joystick2Button6PressedStatus 2727;
BA_ "SPN" SG_ 2365446398 Joystick2Button5PressedStatus 2726;
BA_ "SPN" SG_ 2365446398 Joystick2Button12PressedStatus 2733;
BA_ "SPN" SG_ 2365446398 Joystick2Button11PressedStatus 2732;
BA_ "SPN" SG_ 2365446398 Joystick2Button10PressedStatus 2731;
BA_ "SPN" SG_ 2365446398 Joystick2Button9PressedStatus 2730;
BA_ "SPN" SG_ 2365446654 Jystck2GrpXAxsNtrlPositionStatus 2714;
BA_ "SPN" SG_ 2365446654 Jystck2GrpXAxsLvrLftNegPosStatus 2709;
BA_ "SPN" SG_ 2365446654 Jystck2GrpXAxsLvrRghtPstvPosStat 2704;
BA_ "SPN" SG_ 2365446654 Joystick2GripXAxisPosition 2699;
BA_ "SPN" SG_ 2365446654 Jystck2GrpYAxsNtrlPositionStatus 2715;
BA_ "SPN" SG_ 2365446654 Jystck2GrpYAxsLvrBackNegPosStat 2710;
BA_ "SPN" SG_ 2365446654 Jystck2GrpYAxsLvrFrwdPstvPosStat 2705;
BA_ "SPN" SG_ 2365446654 Joystick2GripYAxisPosition 2700;
BA_ "SPN" SG_ 2365446654 Jystck2ThetaAxsNtrlPosStatus 2716;
BA_ "SPN" SG_ 2365446654 Jystck2ThtAxsCntrClckwsNegPsStat 2711;
BA_ "SPN" SG_ 2365446654 Jystck2ThetaAxsClckwsPstvPosStat 2706;
BA_ "SPN" SG_ 2365446654 Joystick2ThetaAxisPosition 2701;
BA_ "SPN" SG_ 2365446654 Jystck2ThetaAxsDetentPosStatus 2721;
BA_ "SPN" SG_ 2365446654 Jystck2GrpYAxsDetentPosStatus 2720;
BA_ "SPN" SG_ 2365446654 Jystck2GrpXAxsDetentPosStatus 2719;
BA_ "SPN" SG_ 2365446654 Joystick2Button16PressedStatus 6738;
BA_ "SPN" SG_ 2365446654 Joystick2Button15PressedStatus 6737;
BA_ "SPN" SG_ 2365446654 Joystick2Button14PressedStatus 6736;
BA_ "SPN" SG_ 2365446654 Joystick2Button13PressedStatus 6735;
BA_ "SPN" SG_ 2365446910 Jystck3XAxsNeutralPositionStatus 2749;
BA_ "SPN" SG_ 2365446910 Jystck3XAxsLvrLftNegPosStatus 2744;
BA_ "SPN" SG_ 2365446910 Jystck3XAxsLvrRightPstvPosStatus 2739;
BA_ "SPN" SG_ 2365446910 Joystick3XAxisPosition 2734;
BA_ "SPN" SG_ 2365446910 Jystck3YAxsNeutralPositionStatus 2750;
BA_ "SPN" SG_ 2365446910 Jystck3YAxsLvrBackNegPosStatus 2745;
BA_ "SPN" SG_ 2365446910 Jystck3YAxsLvrFrwdPstvPosStatus 2740;
BA_ "SPN" SG_ 2365446910 Joystick3YAxisPosition 2735;
BA_ "SPN" SG_ 2365446910 Jystck3YAxsDetentPositionStatus 2755;
BA_ "SPN" SG_ 2365446910 Jystck3XAxsDetentPositionStatus 2754;
BA_ "SPN" SG_ 2365446910 Joystick3Button4PressedStatus 2762;
BA_ "SPN" SG_ 2365446910 Joystick3Button3PressedStatus 2761;
BA_ "SPN" SG_ 2365446910 Joystick3Button2PressedStatus 2760;
BA_ "SPN" SG_ 2365446910 Joystick3Button1PressedStatus 2759;
BA_ "SPN" SG_ 2365446910 Joystick3Button8PressedStatus 2766;
BA_ "SPN" SG_ 2365446910 Joystick3Button7PressedStatus 2765;
BA_ "SPN" SG_ 2365446910 Joystick3Button6PressedStatus 2764;
BA_ "SPN" SG_ 2365446910 Joystick3Button5PressedStatus 2763;
BA_ "SPN" SG_ 2365446910 Joystick3Button12PressedStatus 2770;
BA_ "SPN" SG_ 2365446910 Joystick3Button11PressedStatus 2769;
BA_ "SPN" SG_ 2365446910 Joystick3Button10PressedStatus 2768;
BA_ "SPN" SG_ 2365446910 Joystick3Button9PressedStatus 2767;
BA_ "SPN" SG_ 2365447166 Jystck3GrpXAxsNtrlPositionStatus 2751;
BA_ "SPN" SG_ 2365447166 Jystck3GrpXAxsLvrLftNegPosStatus 2746;
BA_ "SPN" SG_ 2365447166 Jystck3GrpXAxsLvrRghtPstvPosStat 2741;
BA_ "SPN" SG_ 2365447166 Joystick3GripXAxisPosition 2736;
BA_ "SPN" SG_ 2365447166 Jystck3GrpYAxsNtrlPositionStatus 2752;
BA_ "SPN" SG_ 2365447166 Jystck3GrpYAxsLvrBackNegPosStat 2747;
BA_ "SPN" SG_ 2365447166 Jystck3GrpYAxsLvrFrwdPstvPosStat 2742;
BA_ "SPN" SG_ 2365447166 Joystick3GripYAxisPosition 2737;
BA_ "SPN" SG_ 2365447166 Jystck3ThetaAxsNtrlPosStatus 2753;
BA_ "SPN" SG_ 2365447166 Jystck3ThtAxsCntrClckwsNegPsStat 2748;
BA_ "SPN" SG_ 2365447166 Jystck3ThetaAxsClckwsPstvPosStat 2743;
BA_ "SPN" SG_ 2365447166 Joystick3ThetaAxisPosition 2738;
BA_ "SPN" SG_ 2365447166 Jystck3ThetaAxsDetentPosStatus 2758;
BA_ "SPN" SG_ 2365447166 Jystck3GrpYAxsDetentPosStatus 2757;
BA_ "SPN" SG_ 2365447166 Jystck3GrpXAxsDetentPosStatus 2756;
BA_ "SPN" SG_ 2365447166 Joystick3Button16PressedStatus 6742;
BA_ "SPN" SG_ 2365447166 Joystick3Button15PressedStatus 6741;
BA_ "SPN" SG_ 2365447166 Joystick3Button14PressedStatus 6740;
BA_ "SPN" SG_ 2365447166 Joystick3Button13PressedStatus 6739;
BA_ "SPN" SG_ 2566774014 EngThrottleSyncMdeStat 2615;
BA_ "SPN" SG_ 2566774014 TrollingModeStatus 2616;
BA_ "SPN" SG_ 2566774014 SlowVesselModeStatus 2617;
BA_ "SPN" SG_ 2566774014 EngineMarineOperatingModeStatus 7845;
BA_ "SPN" SG_ 2633883646 FrontWheelDriveActuatorStatus 2612;
BA_ "SPN" SG_ 2566775038 SolarIntensityPercent 2610;
BA_ "SPN" SG_ 2566775038 SolarSensorMaximum 2611;
BA_ "SPN" SG_ 2566775038 SpecificHumidity 4490;
BA_ "SPN" SG_ 2566775038 CalculatedAmbientAirTemperature 5581;
BA_ "SPN" SG_ 2566775038 BarometricAbsolutePressure 5685;
BA_ "SPN" SG_ 2566775294 CabACRefrigCmprssorOtltPress 2609;
BA_ "SPN" SG_ 2566775294 AirConditionerCompressorStatus 7853;
BA_ "SPN" SG_ 2566775550 PneumaticSupplyPressureRequest 2603;
BA_ "SPN" SG_ 2566775550 PrkAndOrTrailerAirPressRequest 2604;
BA_ "SPN" SG_ 2566775550 ServiceBrkAirPressRq_Circuit1 2605;
BA_ "SPN" SG_ 2566775550 ServiceBrkAirPressRq_Circuit2 2606;
BA_ "SPN" SG_ 2566775550 AuxEquipmentSupplyPressRequest 2607;
BA_ "SPN" SG_ 2566775550 AirSuspensionSupplyPressRequest 2608;
BA_ "SPN" SG_ 2566775550 PwrtrainCircuitAirSupplyPressRq 6306;
BA_ "SPN" SG_ 2566775806 TravelVelocityControlPosition 2601;
BA_ "SPN" SG_ 2566776062 PayloadPercentage 2600;
BA_ "SPN" SG_ 2566776062 PayloadWeight 6851;
BA_ "SPN" SG_ 2566776062 PayloadWeightConfidence 6852;
BA_ "SPN" SG_ 2566776062 PayloadCarryBackWeight 6853;
BA_ "SPN" SG_ 2566776062 PayloadCapacityPercentage 6854;
BA_ "SPN" SG_ 2566776318 MaximumVehicleSpeedLimit1 2588;
BA_ "SPN" SG_ 2566776318 MaximumVehicleSpeedLimit2 2589;
BA_ "SPN" SG_ 2566776318 MaximumVehicleSpeedLimit3 2590;
BA_ "SPN" SG_ 2566776318 MaximumVehicleSpeedLimit4 2591;
BA_ "SPN" SG_ 2566776318 MaximumVehicleSpeedLimit5 2592;
BA_ "SPN" SG_ 2566776318 MaximumVehicleSpeedLimit6 2593;
BA_ "SPN" SG_ 2566776318 MaximumVehicleSpeedLimit7 2594;
BA_ "SPN" SG_ 2566776318 AppliedVehicleSpeedLimit 2595;
BA_ "SPN" SG_ 2365449982 HydraulicBrakePressureCircuit1 2580;
BA_ "SPN" SG_ 2365449982 HydraulicBrakePressureCircuit2 2581;
BA_ "SPN" SG_ 2365449982 HydrBrkPressWarningStateCircuit1 2584;
BA_ "SPN" SG_ 2365449982 HydrBrkPressWarningStateCircuit2 2585;
BA_ "SPN" SG_ 2365449982 HydrBrkPressSupplyStateCircuit1 2582;
BA_ "SPN" SG_ 2365449982 HydrBrkPressSupplyStateCircuit2 2583;
BA_ "SPN" SG_ 2365449982 HydrBrkSystemAudibleWarningCmd 2930;
BA_ "SPN" SG_ 2365449982 HydraulicBrakeFluidLevelSwitch 2931;
BA_ "SPN" SG_ 2365450238 Bus1UtilityDeadBus 2535;
BA_ "SPN" SG_ 2365450238 Bus1UtilityPhaseMatch 2531;
BA_ "SPN" SG_ 2365450238 Bus1UtilityFrequencyMatch 2533;
BA_ "SPN" SG_ 2365450238 Bus1UtilityVoltageMatch 2532;
BA_ "SPN" SG_ 2365450238 Bus1UtilityInSync 2534;
BA_ "SPN" SG_ 2365450238 Bus1UtilityACPhaseDifference 2517;
BA_ "SPN" SG_ 2365450494 Bus1GeneratorDeadBus 2530;
BA_ "SPN" SG_ 2365450494 Bus1GeneratorPhaseMatch 2526;
BA_ "SPN" SG_ 2365450494 Bus1GeneratorFrequencyMatch 2528;
BA_ "SPN" SG_ 2365450494 Bus1GeneratorVoltageMatch 2527;
BA_ "SPN" SG_ 2365450494 Bus1GeneratorInSync 2529;
BA_ "SPN" SG_ 2365450494 Bus1GeneratorACPhaseDifference 2516;
BA_ "SPN" SG_ 2365450750 Bus1PhaseCALineLineACRMSVoltage 2511;
BA_ "SPN" SG_ 2365450750 Bus1PhaseCLineNtrlACRMSVoltage 2515;
BA_ "SPN" SG_ 2365450750 Bus1PhaseCACFrequency 2507;
BA_ "SPN" SG_ 2365451006 Bus1PhaseBCLineLineACRMSVoltage 2510;
BA_ "SPN" SG_ 2365451006 Bus1PhaseBLineNtrlACRMSVoltage 2514;
BA_ "SPN" SG_ 2365451006 Bus1PhaseBACFrequency 2506;
BA_ "SPN" SG_ 2365451262 Bus1PhaseABLineLineACRMSVoltage 2509;
BA_ "SPN" SG_ 2365451262 Bus1PhaseALineNtrlACRMSVoltage 2513;
BA_ "SPN" SG_ 2365451262 Bus1PhaseAACFrequency 2505;
BA_ "SPN" SG_ 2365451518 Bus1AverageLineLineACRMSVoltage 2508;
BA_ "SPN" SG_ 2365451518 Bus1AvrgLineNeutralACRMSVoltage 2512;
BA_ "SPN" SG_ 2365451518 Bus1AverageACFrequency 2504;
BA_ "SPN" SG_ 2365451774 UtilityTotalKWHoursExport 2502;
BA_ "SPN" SG_ 2365451774 UtilityTotalKWHoursImport 2503;
BA_ "SPN" SG_ 2365452030 UtilityPhaseCReactivePower 2493;
BA_ "SPN" SG_ 2365452030 UtilityPhaseCPowerFactor 2501;
BA_ "SPN" SG_ 2365452030 UtilityPhaseCPowerFactorLagging 2525;
BA_ "SPN" SG_ 2365452286 UtilityPhaseCRealPower 2489;
BA_ "SPN" SG_ 2365452286 UtilityPhaseCApparentPower 2497;
BA_ "SPN" SG_ 2365452542 UtilityPhaseCALineLineACRMSVltg 2477;
BA_ "SPN" SG_ 2365452542 UtilityPhaseCLineNtrlACRMSVltg 2481;
BA_ "SPN" SG_ 2365452542 UtilityPhaseCACFrequency 2473;
BA_ "SPN" SG_ 2365452542 UtilityPhaseCACRMSCurrent 2485;
BA_ "SPN" SG_ 2365452798 UtilityPhaseBReactivePower 2492;
BA_ "SPN" SG_ 2365452798 UtilityPhaseBPowerFactor 2500;
BA_ "SPN" SG_ 2365452798 UtilityPhaseBPowerFactorLagging 2524;
BA_ "SPN" SG_ 2365453054 UtilityPhaseBRealPower 2488;
BA_ "SPN" SG_ 2365453054 UtilityPhaseBApparentPower 2496;
BA_ "SPN" SG_ 2365453310 UtilityPhaseBCLineLineACRMSVltg 2476;
BA_ "SPN" SG_ 2365453310 UtilityPhaseBLineNtrlACRMSVltg 2480;
BA_ "SPN" SG_ 2365453310 UtilityPhaseBACFrequency 2472;
BA_ "SPN" SG_ 2365453310 UtilityPhaseBACRMSCurrent 2484;
BA_ "SPN" SG_ 2365453566 UtilityPhaseAReactivePower 2491;
BA_ "SPN" SG_ 2365453566 UtilityPhaseAPowerFactor 2499;
BA_ "SPN" SG_ 2365453566 UtilityPhaseAPowerFactorLagging 2523;
BA_ "SPN" SG_ 2365453822 UtilityPhaseARealPower 2487;
BA_ "SPN" SG_ 2365453822 UtilityPhaseAApparentPower 2495;
BA_ "SPN" SG_ 2365454078 UtilityPhaseABLineLineACRMSVltg 2475;
BA_ "SPN" SG_ 2365454078 UtilityPhaseALineNtrlACRMSVltg 2479;
BA_ "SPN" SG_ 2365454078 UtilityPhaseAACFrequency 2471;
BA_ "SPN" SG_ 2365454078 UtilityPhaseAACRMSCurrent 2483;
BA_ "SPN" SG_ 2365454334 UtilityTotalReactivePower 2490;
BA_ "SPN" SG_ 2365454334 UtilityOverallPowerFactor 2498;
BA_ "SPN" SG_ 2365454334 UtilityOverallPowerFactorLagging 2522;
BA_ "SPN" SG_ 2365454590 UtilityTotalRealPower 2486;
BA_ "SPN" SG_ 2365454590 UtilityTotalApparentPower 2494;
BA_ "SPN" SG_ 2365454846 UtilityAvrgLineLineACRMSVoltage 2474;
BA_ "SPN" SG_ 2365454846 UtilityAvrgLineNtrlACRMSVoltage 2478;
BA_ "SPN" SG_ 2365454846 UtilityAverageACFrequency 2470;
BA_ "SPN" SG_ 2365454846 UtilityAverageACRMSCurrent 2482;
BA_ "SPN" SG_ 2365455102 GeneratorTotalKWHoursExport 2468;
BA_ "SPN" SG_ 2365455102 GeneratorTotalKWHoursImport 2469;
BA_ "SPN" SG_ 2365455358 GeneratorPhaseCReactivePower 2459;
BA_ "SPN" SG_ 2365455358 GeneratorPhaseCPowerFactor 2467;
BA_ "SPN" SG_ 2365455358 GenPhaseCPowerFactorLagging 2521;
BA_ "SPN" SG_ 2365455614 GeneratorPhaseCRealPower 2455;
BA_ "SPN" SG_ 2365455614 GeneratorPhaseCApparentPower 2463;
BA_ "SPN" SG_ 2365455870 GenPhaseCALineLineACRMSVoltage 2443;
BA_ "SPN" SG_ 2365455870 GenPhaseCLineNeutralACRMSVoltage 2447;
BA_ "SPN" SG_ 2365455870 GeneratorPhaseCACFrequency 2439;
BA_ "SPN" SG_ 2365455870 GeneratorPhaseCACRMSCurrent 2451;
BA_ "SPN" SG_ 2365456126 GeneratorPhaseBReactivePower 2458;
BA_ "SPN" SG_ 2365456126 GeneratorPhaseBPowerFactor 2466;
BA_ "SPN" SG_ 2365456126 GenPhaseBPowerFactorLagging 2520;
BA_ "SPN" SG_ 2365456382 GeneratorPhaseBRealPower 2454;
BA_ "SPN" SG_ 2365456382 GeneratorPhaseBApparentPower 2462;
BA_ "SPN" SG_ 2365456638 GenPhaseBCLineLineACRMSVoltage 2442;
BA_ "SPN" SG_ 2365456638 GenPhaseBLineNeutralACRMSVoltage 2446;
BA_ "SPN" SG_ 2365456638 GeneratorPhaseBACFrequency 2438;
BA_ "SPN" SG_ 2365456638 GeneratorPhaseBACRMSCurrent 2450;
BA_ "SPN" SG_ 2365456894 GeneratorPhaseAReactivePower 2457;
BA_ "SPN" SG_ 2365456894 GeneratorPhaseAPowerFactor 2465;
BA_ "SPN" SG_ 2365456894 GenPhaseAPowerFactorLagging 2519;
BA_ "SPN" SG_ 2365457150 GeneratorPhaseARealPower 2453;
BA_ "SPN" SG_ 2365457150 GeneratorPhaseAApparentPower 2461;
BA_ "SPN" SG_ 2365457406 GenPhaseABLineLineACRMSVoltage 2441;
BA_ "SPN" SG_ 2365457406 GenPhaseALineNeutralACRMSVoltage 2445;
BA_ "SPN" SG_ 2365457406 GeneratorPhaseAACFrequency 2437;
BA_ "SPN" SG_ 2365457406 GeneratorPhaseAACRMSCurrent 2449;
BA_ "SPN" SG_ 2365457662 GeneratorTotalReactivePower 2456;
BA_ "SPN" SG_ 2365457662 GeneratorOverallPowerFactor 2464;
BA_ "SPN" SG_ 2365457662 GenOverallPowerFactorLagging 2518;
BA_ "SPN" SG_ 2365457918 GeneratorTotalRealPower 2452;
BA_ "SPN" SG_ 2365457918 GeneratorTotalApparentPower 2460;
BA_ "SPN" SG_ 2365458174 GenAvrgLineLineACRMSVoltage 2440;
BA_ "SPN" SG_ 2365458174 GenAvrgLineNeutralACRMSVoltage 2444;
BA_ "SPN" SG_ 2365458174 GeneratorAverageACFrequency 2436;
BA_ "SPN" SG_ 2365458174 GeneratorAverageACRMSCurrent 2448;
BA_ "SPN" SG_ 2566785022 EngExhstManifoldBnk2Temperature1 2433;
BA_ "SPN" SG_ 2566785022 EngExhstManifoldBnk1Temperature1 2434;
BA_ "SPN" SG_ 2566785022 EngExhstManifoldBnk2Temperature2 5969;
BA_ "SPN" SG_ 2566785022 EngExhstManifoldBnk1Temperature2 5970;
BA_ "SPN" SG_ 2566786558 NumberOfMembersInWorkingSet 2409;
BA_ "SPN" SG_ 2566799614 RunningLight 2404;
BA_ "SPN" SG_ 2566799614 AlternateBeamHeadLightData 2352;
BA_ "SPN" SG_ 2566799614 LowBeamHeadLightData 2350;
BA_ "SPN" SG_ 2566799614 HighBeamHeadLightData 2348;
BA_ "SPN" SG_ 2566799614 TractorFrontFogLights 2388;
BA_ "SPN" SG_ 2566799614 RotatingBeaconLight 2386;
BA_ "SPN" SG_ 2566799614 RightTurnSignalLights 2370;
BA_ "SPN" SG_ 2566799614 LeftTurnSignalLights 2368;
BA_ "SPN" SG_ 2566799614 BackUpLightAndAlarmHorn 2392;
BA_ "SPN" SG_ 2566799614 CenterStopLight 2376;
BA_ "SPN" SG_ 2566799614 RightStopLight 2374;
BA_ "SPN" SG_ 2566799614 LeftStopLight 2372;
BA_ "SPN" SG_ 2566799614 ImplementClearanceLight 2384;
BA_ "SPN" SG_ 2566799614 TractorClearanceLight 2382;
BA_ "SPN" SG_ 2566799614 ImplementMarkerLight 2380;
BA_ "SPN" SG_ 2566799614 TractorMarkerLight 2378;
BA_ "SPN" SG_ 2566799614 RearFogLights 2390;
BA_ "SPN" SG_ 2566799614 TractorUndersideMntdWorkLights 2358;
BA_ "SPN" SG_ 2566799614 TractorRearLowMountedWorkLights 2360;
BA_ "SPN" SG_ 2566799614 TractorRearHighMountedWorkLights 2362;
BA_ "SPN" SG_ 2566799614 TractorSideLowMountedWorkLights 2364;
BA_ "SPN" SG_ 2566799614 TractorSideHighMountedWorkLights 2366;
BA_ "SPN" SG_ 2566799614 TractorFrontLowMountedWorkLights 2354;
BA_ "SPN" SG_ 2566799614 TractorFrntHighMountedWorkLights 2356;
BA_ "SPN" SG_ 2566799614 ImplementOEMOption2Light 2398;
BA_ "SPN" SG_ 2566799614 ImplementOEMOption1Light 2396;
BA_ "SPN" SG_ 2566799614 ImplementRightFacingWorkLight 2407;
BA_ "SPN" SG_ 2566799614 ImplementLeftForwardWorkLight 2598;
BA_ "SPN" SG_ 2566799614 ImplementRightForwardWorkLight 2402;
BA_ "SPN" SG_ 2566799614 ImplementLeftFacingWorkLight 2400;
BA_ "SPN" SG_ 2566799614 ImplementRearWorkLight 2394;
BA_ "SPN" SG_ 2365473278 RunningLightCommand 2403;
BA_ "SPN" SG_ 2365473278 AlternateBeamHeadLightCommand 2351;
BA_ "SPN" SG_ 2365473278 LowBeamHeadLightCommand 2349;
BA_ "SPN" SG_ 2365473278 HighBeamHeadLightCommand 2347;
BA_ "SPN" SG_ 2365473278 TractorFrontFogLightsCommand 2387;
BA_ "SPN" SG_ 2365473278 RotatingBeaconLightCommand 2385;
BA_ "SPN" SG_ 2365473278 RightTurnSignalLightsCommand 2369;
BA_ "SPN" SG_ 2365473278 LeftTurnSignalLightsCommand 2367;
BA_ "SPN" SG_ 2365473278 BackUpLightAndAlarmHornCommand 2391;
BA_ "SPN" SG_ 2365473278 CenterStopLightCommand 2375;
BA_ "SPN" SG_ 2365473278 RightStopLightCommand 2373;
BA_ "SPN" SG_ 2365473278 LeftStopLightCommand 2371;
BA_ "SPN" SG_ 2365473278 ImplementClearanceLightCommand 2383;
BA_ "SPN" SG_ 2365473278 TractorClearanceLightCommand 2381;
BA_ "SPN" SG_ 2365473278 ImplementMarkerLightCommand 2379;
BA_ "SPN" SG_ 2365473278 TractorMarkerLightCommand 2377;
BA_ "SPN" SG_ 2365473278 RearFogLightCommand 2389;
BA_ "SPN" SG_ 2365473278 TractorUnderSdeMntdWorkLightsCmd 2357;
BA_ "SPN" SG_ 2365473278 TractorRearLowMntdWorkLightsCmd 2359;
BA_ "SPN" SG_ 2365473278 TractorRearHghMntdWorkLightsCmd 2361;
BA_ "SPN" SG_ 2365473278 TractorSideLowMntdWorkLightsCmd 2363;
BA_ "SPN" SG_ 2365473278 TractorSideHghMntdWorkLightsCmd 2365;
BA_ "SPN" SG_ 2365473278 TractorFrntLowMntdWorkLightsCmd 2353;
BA_ "SPN" SG_ 2365473278 TractorFrntHghMntdWorkLightsCmd 2355;
BA_ "SPN" SG_ 2365473278 ImplementOEMOption2LightCommand 2397;
BA_ "SPN" SG_ 2365473278 ImplementOEMOption1LightCommand 2395;
BA_ "SPN" SG_ 2365473278 ImplementRightFacingWorkLightCmd 2406;
BA_ "SPN" SG_ 2365473278 ImplementLeftForwardWorkLightCmd 2597;
BA_ "SPN" SG_ 2365473278 LightingDataRequestCommand 2393;
BA_ "SPN" SG_ 2365473278 ImplementRightFrwdWorkLightCmd 2401;
BA_ "SPN" SG_ 2365473278 ImplementLeftFacingWorkLightCmd 2399;
BA_ "SPN" SG_ 2365473278 ImplementRearWorkLightCommand 2405;
BA_ "SPN" SG_ 2566802174 TrnsmCurrentRngDisplayBlankStat 4176;
BA_ "SPN" SG_ 2566802174 TransmissionServiceIndicator 4178;
BA_ "SPN" SG_ 2566802174 TrnsmRqedRngDisplayBlankStat 1850;
BA_ "SPN" SG_ 2566802174 TrnsmRqedRngDisplayFlashStat 1849;
BA_ "SPN" SG_ 2566802174 TransmissionReadyForBrakeRelease 3086;
BA_ "SPN" SG_ 2566802174 ActiveShiftConsoleIndicator 2945;
BA_ "SPN" SG_ 2566802174 TransmissionEngineCrankEnable 2900;
BA_ "SPN" SG_ 2566802174 TransmissionShiftInhibitIndictr 1851;
BA_ "SPN" SG_ 2566802174 TransmissionMode4Indicator 2539;
BA_ "SPN" SG_ 2566802174 TransmissionMode3Indicator 2538;
BA_ "SPN" SG_ 2566802174 TransmissionMode2Indicator 2537;
BA_ "SPN" SG_ 2566802174 TransmissionMode1Indicator 2536;
BA_ "SPN" SG_ 2566802174 TransmissionRequestedGearFdbck 3289;
BA_ "SPN" SG_ 2566802174 TransmissionMode5Indicator 4250;
BA_ "SPN" SG_ 2566802174 TransmissionMode6Indicator 4251;
BA_ "SPN" SG_ 2566802174 TransmissionMode7Indicator 4252;
BA_ "SPN" SG_ 2566802174 TransmissionMode8Indicator 4253;
BA_ "SPN" SG_ 2566802174 TrnsmReverseGearShftInhbtStat 4261;
BA_ "SPN" SG_ 2566802174 TransmissionWarningIndicator 5344;
BA_ "SPN" SG_ 2566802174 TransmissionMode9Indicator 6567;
BA_ "SPN" SG_ 2566802174 TransmissionMode10Indicator 6568;
BA_ "SPN" SG_ 2566802174 TrnsmAirSupplyPressIndictr 6566;
BA_ "SPN" SG_ 2566802174 TransmissionAutoNeutralState 7696;
BA_ "SPN" SG_ 2566802174 TransmissionManualModeIndicator 8291;
BA_ "SPN" SG_ 2566802430 TransmissionTorqueLimit 1845;
BA_ "SPN" SG_ 2566802430 TransmissionReferenceTorque 7778;
BA_ "SPN" SG_ 2566802430 TrnsmCommsFailureIdlTrqLmt 7827;
BA_ "SPN" SG_ 2566802686 RearBlackOutMarkerSelect 1840;
BA_ "SPN" SG_ 2566802686 FrontBlackOutMarkerLampSelect 1839;
BA_ "SPN" SG_ 2566802686 ConvoyLampSelect 1838;
BA_ "SPN" SG_ 2566802686 ConvoyDrivingLampSelect 1837;
BA_ "SPN" SG_ 2566802686 BlackOutBrakeStopLampSelect 1841;
BA_ "SPN" SG_ 2566802686 NightVisionIlluminatorSelect 1843;
BA_ "SPN" SG_ 2566802686 BlackOutWorkLampSelect 1842;
BA_ "SPN" SG_ 2566802686 OprtrsBlackOutIntensitySelection 1844;
BA_ "SPN" SG_ 2633911806 EngineTotalAverageFuelRate 1834;
BA_ "SPN" SG_ 2633911806 EngineTotalAverageFuelEconomy 1835;
BA_ "SPN" SG_ 2566803198 PositionOfDoors 1821;
BA_ "SPN" SG_ 2566803198 RampWheelChairLiftPosition 1820;
BA_ "SPN" SG_ 2566803198 Status2OfDoors 3411;
BA_ "SPN" SG_ 2566803454 VDCInformationSignal 1813;
BA_ "SPN" SG_ 2566803454 VDCFullyOperational 1814;
BA_ "SPN" SG_ 2566803454 VDCBrakeLightRequest 1815;
BA_ "SPN" SG_ 2566803454 ROPEngineControlActive 1816;
BA_ "SPN" SG_ 2566803454 ROPBrakeControlActive 1818;
BA_ "SPN" SG_ 2566803454 YCEngineControlActive 1817;
BA_ "SPN" SG_ 2566803454 YCBrakeControlActive 1819;
BA_ "SPN" SG_ 2566803454 TrailerVDCActive 5624;
BA_ "SPN" SG_ 2566803710 Battery1Temperature 1800;
BA_ "SPN" SG_ 2566803710 Battery2Temperature 1801;
BA_ "SPN" SG_ 2566803710 SLIBattery3Temperature 2779;
BA_ "SPN" SG_ 2566803710 SLIBattery4Temperature 2780;
BA_ "SPN" SG_ 2566803966 ACCUsageDemand 5023;
BA_ "SPN" SG_ 2566803966 RequestedACCDistanceMode 1799;
BA_ "SPN" SG_ 2566804222 AlternatorCurrent 1795;
BA_ "SPN" SG_ 2566804222 NetBatteryCurrent 2579;
BA_ "SPN" SG_ 2566804222 SLIBattery2NetCurrent 7498;
BA_ "SPN" SG_ 2566804478 LowLmtThresholdForMaxRPMFrmRtrdr 1776;
BA_ "SPN" SG_ 2566804478 HghLmtTrshldMinCntnsRPMFrmRtrdr 1777;
BA_ "SPN" SG_ 2566804478 LowLmtTrshldForMaxTorqueFrmRtrdr 1778;
BA_ "SPN" SG_ 2566804478 HghLmtTrshldMinCntnsTrqFrmRtrdr 1779;
BA_ "SPN" SG_ 2566804478 MaximumContinuousRetarderSpeed 1780;
BA_ "SPN" SG_ 2566804478 MinimumContinuousRetarderSpeed 1781;
BA_ "SPN" SG_ 2566804478 MaximumContinuousRetarderTorque 1782;
BA_ "SPN" SG_ 2566804478 MinimumContinuousRetarderTorque 1783;
BA_ "SPN" SG_ 2566804734 EngLowLmtTrshldForMaxRPMFrmEng 1768;
BA_ "SPN" SG_ 2566804734 EngHghLmtTrshldForMinCntnsEngRPM 1769;
BA_ "SPN" SG_ 2566804734 EngLowLmtTrshldForMaxTrqFrmEng 1770;
BA_ "SPN" SG_ 2566804734 EngHghLmtTrshldMinCntnsTrqFrmEng 1771;
BA_ "SPN" SG_ 2566804734 EngineMaximumContinuousRPM 1772;
BA_ "SPN" SG_ 2566804734 EngineMinimumContinuousRPM 1773;
BA_ "SPN" SG_ 2566804734 EngineMaximumContinuousTorque 1774;
BA_ "SPN" SG_ 2566804734 EngineMinimumContinuousTorque 1775;
BA_ "SPN" SG_ 2566804990 SpecificHeatRatio 1767;
BA_ "SPN" SG_ 2566804990 ReferenceEngineGasMassFlowRate 5684;
BA_ "SPN" SG_ 2566804990 FuelEnergyContent 4245;
BA_ "SPN" SG_ 2566805246 Aftrtrtmnt1DslExhstFldTankLevel 1761;
BA_ "SPN" SG_ 2566805246 Aftrtrtmnt1DslExhstFldTnkTemp 3031;
BA_ "SPN" SG_ 2566805246 Aftrtrtmnt1DslExhstFldTankLevel2 3517;
BA_ "SPN" SG_ 2566805246 Aft1DslExhstFldTnkLvlPrelimFMI 3532;
BA_ "SPN" SG_ 2566805246 AftSlctiveCtlytcRedOprtrIndcmntA 5245;
BA_ "SPN" SG_ 2566805246 Aft1DslExhstFldTnk1TempPrelimFMI 4365;
BA_ "SPN" SG_ 2566805246 AftrtrtmntSCROprtrIndcmntSvrty 5246;
BA_ "SPN" SG_ 2566805246 Aftrtrtmnt1DslExhstFldTankHeater 3363;
BA_ "SPN" SG_ 2566805246 Aft1DslExhstFldTnk1HtrPrelimFMI 4366;
BA_ "SPN" SG_ 2365478910 DamperStiffnessFrontAxle 1729;
BA_ "SPN" SG_ 2365478910 DamperStiffnessRearAxle 1730;
BA_ "SPN" SG_ 2365478910 DamperStiffnessLiftTagAxle 1731;
BA_ "SPN" SG_ 2365478910 ElctrncShockAbsrbrCtrlMdeFrntAxl 1833;
BA_ "SPN" SG_ 2365478910 ElctrncShockAbsrbrCtrlMdeRearAxl 1832;
BA_ "SPN" SG_ 2365478910 ElctrncShckAbsrbrCtrlMdeLftTgAxl 1831;
BA_ "SPN" SG_ 2566805758 BellowPressureFrontAxleLeft 1725;
BA_ "SPN" SG_ 2566805758 BellowPressureFrontAxleRight 1726;
BA_ "SPN" SG_ 2566805758 BellowPressureRearAxleLeft 1727;
BA_ "SPN" SG_ 2566805758 BellowPressureRearAxleRight 1728;
BA_ "SPN" SG_ 2566806014 RelativeLevelFrontAxleLeft 1721;
BA_ "SPN" SG_ 2566806014 RelativeLevelFrontAxleRight 1722;
BA_ "SPN" SG_ 2566806014 RelativeLevelRearAxleLeft 1724;
BA_ "SPN" SG_ 2566806014 RelativeLevelRearAxleRight 1723;
BA_ "SPN" SG_ 2365479678 NominalLevelFrontAxle 1734;
BA_ "SPN" SG_ 2365479678 NominalLevelRearAxle 1733;
BA_ "SPN" SG_ 2365479678 BelowNominalLevelFrontAxle 1738;
BA_ "SPN" SG_ 2365479678 BelowNominalLevelRearAxle 1754;
BA_ "SPN" SG_ 2365479678 AboveNominalLevelFrontAxle 1737;
BA_ "SPN" SG_ 2365479678 AboveNominalLevelRearAxle 1736;
BA_ "SPN" SG_ 2365479678 LoweringControlModeFrontAxle 1740;
BA_ "SPN" SG_ 2365479678 LoweringControlModeRearAxle 1755;
BA_ "SPN" SG_ 2365479678 LiftingControlModeFrontAxle 1739;
BA_ "SPN" SG_ 2365479678 LiftingControlModeRearAxle 1756;
BA_ "SPN" SG_ 2365479678 KneelingInformation 1742;
BA_ "SPN" SG_ 2365479678 LevelControlMode 1741;
BA_ "SPN" SG_ 2365479678 SecurityDevice 1746;
BA_ "SPN" SG_ 2365479678 VehicleMotionInhibit 1745;
BA_ "SPN" SG_ 2365479678 DoorRelease 1744;
BA_ "SPN" SG_ 2365479678 LiftAxle1Position 1743;
BA_ "SPN" SG_ 2365479678 FrontAxleInBumperRange 1824;
BA_ "SPN" SG_ 2365479678 RearAxleInBumperRange 1823;
BA_ "SPN" SG_ 2365479678 LiftAxle2Position 1822;
BA_ "SPN" SG_ 2365479678 SuspensionRemoteControl1 1826;
BA_ "SPN" SG_ 2365479678 SuspensionRemoteControl2 1825;
BA_ "SPN" SG_ 2365479678 AllowLevelCtrlDuringBrkngStatus 5294;
BA_ "SPN" SG_ 2365479678 SpeedDependantLevelControlStatus 5296;
BA_ "SPN" SG_ 2365479678 SuspensionCtrlRefusalInformation 1827;
BA_ "SPN" SG_ 2365479678 MemoryLevel 5432;
BA_ "SPN" SG_ 2566806526 LaneTrackingStatusRightSide 1711;
BA_ "SPN" SG_ 2566806526 LaneTrackingStatusLeftSide 1710;
BA_ "SPN" SG_ 2566806526 LaneDePrtureIndicationEnblStatus 1702;
BA_ "SPN" SG_ 2566806526 DriverAlertnessLevel 7474;
BA_ "SPN" SG_ 2566806526 DrvrAlertnessWarningSystemState 7475;
BA_ "SPN" SG_ 2566806526 LeftWheelLaneDepartureDistance 8139;
BA_ "SPN" SG_ 2566806526 RightWheelLaneDepartureDistance 8140;
BA_ "SPN" SG_ 2566806526 LaneDepartureWarningSystemState 8141;
BA_ "SPN" SG_ 2566806526 ForwardLaneImagerStatus 8142;
BA_ "SPN" SG_ 2566809342 BatteryMainSwitchHoldState 1681;
BA_ "SPN" SG_ 2566809598 AuxHeaterMaximumOutputPower 1690;
BA_ "SPN" SG_ 2566809854 HydraulicTemperature 1638;
BA_ "SPN" SG_ 2566809854 HydrOilFilterRestrictionSwitch 1713;
BA_ "SPN" SG_ 2566809854 WinchOilPressureSwitch 1857;
BA_ "SPN" SG_ 2566809854 HydraulicOilLevel 2602;
BA_ "SPN" SG_ 2566810110 EngineIntakeManifold1Temperature 1636;
BA_ "SPN" SG_ 2566810110 EngineCoolantTemperature 1637;
BA_ "SPN" SG_ 2566810110 EngIntkValveActSysOilTemperature 2986;
BA_ "SPN" SG_ 2566810110 EngChargeAirCool1OtltTemperature 2630;
BA_ "SPN" SG_ 2566810366 EngineOilLevelRemoteReservoir 1380;
BA_ "SPN" SG_ 2566810366 EngFuelSupplyPumpIntakePressure 1381;
BA_ "SPN" SG_ 2566810366 EngineFuelFilterDiffPressure 1382;
BA_ "SPN" SG_ 2566810366 EngineWasteOilReservoirLevel 3548;
BA_ "SPN" SG_ 2566810366 EngineOilFilterOutletPressure 3549;
BA_ "SPN" SG_ 2566810366 EngineOilPrimingPumpSwitch 3550;
BA_ "SPN" SG_ 2566810366 EngineOilPrimingState 3551;
BA_ "SPN" SG_ 2566810366 EngineOilPreHeatedState 3552;
BA_ "SPN" SG_ 2566810366 EngineCoolantPreHeatedState 3553;
BA_ "SPN" SG_ 2566810366 EngineVentilationStatus 3554;
BA_ "SPN" SG_ 2566810366 FuelPumpPrimerStatus 4083;
BA_ "SPN" SG_ 2566810366 EngFuelSupplyPumpIntakePressure2 7104;
BA_ "SPN" SG_ 2566810622 Driver1Identification 1625;
BA_ "SPN" SG_ 2566810622 Driver2Identification 1626;
BA_ "SPN" SG_ 2365484286 Driver1WorkingState 1612;
BA_ "SPN" SG_ 2365484286 Driver2WorkingState 1613;
BA_ "SPN" SG_ 2365484286 VehicleMotion 1611;
BA_ "SPN" SG_ 2365484286 Driver1TimeRelatedStates 1617;
BA_ "SPN" SG_ 2365484286 DriverCard_Driver1 1615;
BA_ "SPN" SG_ 2365484286 VehicleOverspeed 1614;
BA_ "SPN" SG_ 2365484286 Driver2TimeRelatedStates 1618;
BA_ "SPN" SG_ 2365484286 DriverCard_Driver2 1616;
BA_ "SPN" SG_ 2365484286 SystemEvent 1622;
BA_ "SPN" SG_ 2365484286 HandlingInformation 1621;
BA_ "SPN" SG_ 2365484286 TachographPerformance 1620;
BA_ "SPN" SG_ 2365484286 DirectionIndicator 1619;
BA_ "SPN" SG_ 2365484286 TachographOutputShaftSpeed 1623;
BA_ "SPN" SG_ 2365484286 TachographVehicleSpeed 1624;
BA_ "SPN" SG_ 2566811134 AuxHeaterOutputCoolntTemperature 1687;
BA_ "SPN" SG_ 2566811134 AuxHeaterInputAirTemperature 1688;
BA_ "SPN" SG_ 2566811134 AuxHeaterOutputPowerPercent 1689;
BA_ "SPN" SG_ 2566811134 AuxiliaryHeaterMode 1677;
BA_ "SPN" SG_ 2566811134 AuxiliaryHeaterWaterPumpStatus 1676;
BA_ "SPN" SG_ 2566811134 CabVentilation 1678;
BA_ "SPN" SG_ 2566811134 EngineHeatingZone 1679;
BA_ "SPN" SG_ 2566811134 CabHeatingZone 1680;
BA_ "SPN" SG_ 2566811134 ADRCompliantHeaterInstallation 6821;
BA_ "SPN" SG_ 2298375934 FrontAxle_LeftWheelSpeed 1592;
BA_ "SPN" SG_ 2298375934 FrontAxle_RightWheelSpeed 1593;
BA_ "SPN" SG_ 2298375934 RearAxle_LeftWheelSpeed 1594;
BA_ "SPN" SG_ 2298375934 RearAxle_RightWheelSpeed 1595;
BA_ "SPN" SG_ 2432593918 SpeedOfForwardVehicle 1586;
BA_ "SPN" SG_ 2432593918 DistanceToForwardVehicle 1587;
BA_ "SPN" SG_ 2432593918 AdaptiveCruiseControlSetSpeed 1588;
BA_ "SPN" SG_ 2432593918 AdaptiveCruiseControlMode 1590;
BA_ "SPN" SG_ 2432593918 AdaptiveCruiseCtrlSetDistMode 1589;
BA_ "SPN" SG_ 2432593918 RoadCurvature 1591;
BA_ "SPN" SG_ 2432593918 ACCTargetDetected 1798;
BA_ "SPN" SG_ 2432593918 ACCSystemShutoffWarning 1797;
BA_ "SPN" SG_ 2432593918 ACCDistanceAlertSignal 1796;
BA_ "SPN" SG_ 2432593918 ForwardCollisionWarning 5022;
BA_ "SPN" SG_ 2566811902 PoweredVehicleWeight 1585;
BA_ "SPN" SG_ 2566811902 GrossCombinationVehicleWeight 1760;
BA_ "SPN" SG_ 2365485566 LaserTracerTargetDeviation 1579;
BA_ "SPN" SG_ 2365485566 LaserTracerVerticalDistance 1580;
BA_ "SPN" SG_ 2365485566 LaserTracerHorizontalDeviation 1581;
BA_ "SPN" SG_ 2365485566 LEDDisplayData2 1582;
BA_ "SPN" SG_ 2365485566 LaserTracerInformation 1583;
BA_ "SPN" SG_ 2365485822 BladeDurationAndDirection 1577;
BA_ "SPN" SG_ 2365485822 BladeControlMode 1578;
BA_ "SPN" SG_ 2365485822 BladeControlModeLeft 5407;
BA_ "SPN" SG_ 2365485822 BladeControlModeRight 5408;
BA_ "SPN" SG_ 2365485822 LandLevelingSystemEnableStatus 5409;
BA_ "SPN" SG_ 2365486078 MastPosition 1576;
BA_ "SPN" SG_ 2365486334 ModifyLevelingSystemSetPoint 1575;
BA_ "SPN" SG_ 2365486334 BladeHeightSetPoint 1759;
BA_ "SPN" SG_ 2365486590 LaserStrikeVerticalDeviation 1574;
BA_ "SPN" SG_ 2365486590 LaserReceiverType 2576;
BA_ "SPN" SG_ 2365486590 LaserStrikeDataLatency 2793;
BA_ "SPN" SG_ 2365486590 AbsoluteLaserStrikePosition 2794;
BA_ "SPN" SG_ 2432595710 LEDDisplayData1 1573;
BA_ "SPN" SG_ 2432595710 LEDDisplayModeControl 1805;
BA_ "SPN" SG_ 2432595710 LEDDisplayDeadbandControl 1806;
BA_ "SPN" SG_ 2432595710 LEDPatternControl 2578;
BA_ "SPN" SG_ 2432595710 DisplayDeadbands 2577;
BA_ "SPN" SG_ 2633922558 AuxiliaryVacuumPressureReading 136;
BA_ "SPN" SG_ 2633922558 AuxiliaryGagePressureReading1 137;
BA_ "SPN" SG_ 2633922558 AuxiliaryAbsolutePressureReading 138;
BA_ "SPN" SG_ 2633922814 TirePressureCheckInterval 39;
BA_ "SPN" SG_ 2633922814 SteerChannelMode 1466;
BA_ "SPN" SG_ 2633922814 TrailerTagChannelMode 1467;
BA_ "SPN" SG_ 2633922814 DriveChannelMode 1468;
BA_ "SPN" SG_ 2633922814 PCUDriveSolenoidStatus 1469;
BA_ "SPN" SG_ 2633922814 PCUSteerSolenoidStatus 1470;
BA_ "SPN" SG_ 2633922814 TirePressureSupplySwitchStatus 1471;
BA_ "SPN" SG_ 2633922814 PCUDeflateSolenoidStatus 1472;
BA_ "SPN" SG_ 2633922814 PCUControlSolenoidStatus 1473;
BA_ "SPN" SG_ 2633922814 PCUSupplySolenoidStatus 1474;
BA_ "SPN" SG_ 2633922814 PCUTrailer_TagOrPushSolenoidStat 1475;
BA_ "SPN" SG_ 2633923070 Trlr_TgOrPushChnnlTirePrsTarget 141;
BA_ "SPN" SG_ 2633923070 DriveChannelTirePressureTarget 142;
BA_ "SPN" SG_ 2633923070 SteerChannelTirePressureTarget 143;
BA_ "SPN" SG_ 2633923326 Trailer_TagOrPushChnnlTirePress 144;
BA_ "SPN" SG_ 2633923326 DriveChannelTirePressure 145;
BA_ "SPN" SG_ 2633923326 SteerChannelTirePressure 146;
BA_ "SigType" SG_ 2566766590 MilepostIdentification 3;
BA_ "SigType" SG_ 2566768126 ECUHardwareID 3;
BA_ "SigType" SG_ 2633880062 FMSStandardSWVersionSupported 3;
BA_ "SigType" SG_ 2566810622 Driver1Identification 3;
BA_ "SigType" SG_ 2566810622 Driver2Identification 3;
VAL_ 2566759934 LockStatusOfDoor1 0 "Unlocked " 1 "Locked" 2 "Error" 3 "Not available" ;
VAL_ 2566759934 OpenStatusOfDoor1 0 "Door closed" 1 "Door opened" 2 "Error" 3 "Not available" ;
VAL_ 2566759934 EnableStatusOfDoor1 0 "Door disabled" 1 "Door enabled" 2 "Error" 3 "Not available" ;
VAL_ 2566759934 LockStatusOfDoor2 0 "Unlocked " 1 "Locked" 2 "Error" 3 "Not available" ;
VAL_ 2566759934 OpenStatusOfDoor2 0 "Door closed" 1 "Door opened" 2 "Error" 3 "Not available" ;
VAL_ 2566759934 EnableStatusOfDoor2 0 "Door disabled" 1 "Door enabled" 2 "Error" 3 "Not available" ;
VAL_ 2566759934 LockStatusOfDoor3 0 "Unlocked " 1 "Locked" 2 "Error" 3 "Not available" ;
VAL_ 2566759934 OpenStatusOfDoor3 0 "Door closed" 1 "Door opened" 2 "Error" 3 "Not available" ;
VAL_ 2566759934 EnableStatusOfDoor3 0 "Door disabled" 1 "Door enabled" 2 "Error" 3 "Not available" ;
VAL_ 2566759934 LockStatusOfDoor4 0 "Unlocked " 1 "Locked" 2 "Error" 3 "Not available" ;
VAL_ 2566759934 OpenStatusOfDoor4 0 "Door closed" 1 "Door opened" 2 "Error" 3 "Not available" ;
VAL_ 2566759934 EnableStatusOfDoor4 0 "Door disabled" 1 "Door enabled" 2 "Error" 3 "Not available" ;
VAL_ 2566759934 LockStatusOfDoor5 0 "Unlocked " 1 "Locked" 2 "Error" 3 "Not available" ;
VAL_ 2566759934 OpenStatusOfDoor5 0 "Door closed" 1 "Door opened" 2 "Error" 3 "Not available" ;
VAL_ 2566759934 EnableStatusOfDoor5 0 "Door disabled" 1 "Door enabled" 2 "Error" 3 "Not available" ;
VAL_ 2566759934 LockStatusOfDoor6 0 "Unlocked " 1 "Locked" 2 "Error" 3 "Not available" ;
VAL_ 2566759934 OpenStatusOfDoor6 0 "Door closed" 1 "Door opened" 2 "Error" 3 "Not available" ;
VAL_ 2566759934 EnableStatusOfDoor6 0 "Door disabled" 1 "Door enabled" 2 "Error" 3 "Not available" ;
VAL_ 2566759934 LockStatusOfDoor7 0 "Unlocked " 1 "Locked" 2 "Error" 3 "Not available" ;
VAL_ 2566759934 OpenStatusOfDoor7 0 "Door closed" 1 "Door opened" 2 "Error" 3 "Not available" ;
VAL_ 2566759934 EnableStatusOfDoor7 0 "Door disabled" 1 "Door enabled" 2 "Error" 3 "Not available" ;
VAL_ 2566759934 LockStatusOfDoor8 0 "Unlocked " 1 "Locked" 2 "Error" 3 "Not available" ;
VAL_ 2566759934 OpenStatusOfDoor8 0 "Door closed" 1 "Door opened" 2 "Error" 3 "Not available" ;
VAL_ 2566759934 EnableStatusOfDoor8 0 "Door disabled" 1 "Door enabled" 2 "Error" 3 "Not available" ;
VAL_ 2566759934 LockStatusOfDoor9 0 "Unlocked " 1 "Locked" 2 "Error" 3 "Not available" ;
VAL_ 2566759934 OpenStatusOfDoor9 0 "Door closed" 1 "Door opened" 2 "Error" 3 "Not available" ;
VAL_ 2566759934 EnableStatusOfDoor9 0 "Door disabled" 1 "Door enabled" 2 "Error" 3 "Not available" ;
VAL_ 2566759934 LockStatusOfDoor10 0 "Unlocked " 1 "Locked" 2 "Error" 3 "Not available" ;
VAL_ 2566759934 OpenStatusOfDoor10 0 "Door closed" 1 "Door opened" 2 "Error" 3 "Not available" ;
VAL_ 2566759934 EnableStatusOfDoor10 0 "Door disabled" 1 "Door enabled" 2 "Error" 3 "Not available" ;
VAL_ 2633869310 VoltageRegulatorLoadCmpnstnMode 0 "load compensation disabled" 1 "Voltage droop compensation enabled" 2 "IR line drop compensation enabled" 3 "Reserved" 4 "Reserved" 5 "Reserved" 6 "Reserved" 7 "Not available" ;
VAL_ 2633869310 VltgRgltrVArPwrFactorOprtngMde 0 "VAr/Power Factor regulation disabled" 1 "Power factor regulation enabled" 2 "VAr regulation enabled" 3 "Reserved" 4 "Reserved" 5 "Reserved" 6 "Reserved" 7 "Not available" ;
VAL_ 2633869310 VltgRgltrUnderFreqCmpnstnEnbld 0 "Underfrequency compensation disabled" 1 "Underfrequency compensation enabled" 2 "Reserved" 3 "Not available" ;
VAL_ 2633869310 VoltageRegulatorSoftStartState 0 "Soft start is inactive" 1 "Soft start is active" 2 "Reserved" 3 "Not available" ;
VAL_ 2633869310 VoltageRegulatorEnabled 0 "Not regulating voltage" 1 "Regulating voltage" 2 "Reserved" 3 "Not available" ;
VAL_ 2566760702 NetworkTransceiverStatus2 0 "Off" 1 "On" 2 "Not Authorized to Operate on Network" 254 "Error" 255 "Not Available" ;
VAL_ 2566760702 NetworkServiceStatus2 0 "Local Service" 1 "Roaming Service" 2 "Service not available" 3 "Not Authorized to Operate on Service" 254 "Error" 255 "Not Available" ;
VAL_ 2566760702 NetworkAntennaStatus2 0 "Off" 1 "On" 254 "Error" 255 "Not Available" ;
VAL_ 2566760702 WirelessCommNetworkType2 0 "Cellular network #1" 1 "Cellular network #2" 2 "Wireless LAN #1" 3 "Wireless LAN #2" 4 "Satellite network" 254 "Error" 255 "Not Available" ;
VAL_ 2566760958 NetworkTransceiverStatus1 0 "Off" 1 "On" 2 "Not Authorized to Operate on Network" 254 "Error" 255 "Not Available" ;
VAL_ 2566760958 NetworkServiceStatus1 0 "Local Service" 1 "Roaming Service" 2 "Service not available" 3 "Not Authorized to Operate on Service" 254 "Error" 255 "Not Available" ;
VAL_ 2566760958 NetworkAntennaStatus1 0 "Off" 1 "On" 254 "Error" 255 "Not Available" ;
VAL_ 2566760958 WirelessCommNetworkType1 0 "Cellular network #1" 1 "Cellular network #2" 2 "Wireless LAN #1" 3 "Wireless LAN #2" 4 "Satellite network" 254 "Error" 255 "Not Available" ;
VAL_ 2566762238 FifthWheelErrorStatus 0 "Improper Couple" 1 "Locks Closed / No Kingpin at Startup" 2 "Kingpin / Locks Open at Startup" 3 "Not Used" 4 "Not Used" 5 "Coupling Sequence Error" 6 "Coupling Sequence Error / Kingpin" 7 "Coupling Timing Error" 8 "Kingpin Missing More Than 5 Seconds" 9 "Kingpin / Lock Open (Handle Pulled)" 10 "Not Used" 11 "Not Used" 12 "Not Used" 13 "Not Used" 14 "Not Used" 15 "Not available" ;
VAL_ 2566762238 FifthWheelLockRdyToCoupleIndictr 0 "Lock not open, not ready to couple" 1 "Lock open, ready to couple" 2 "Error" 3 "Not Available" ;
VAL_ 2566762238 FifthWheelLockCoupleStatIndictr 0 "Incomplete or bad couple" 1 "Successful couple detected" 2 "Error" 3 "Not Available" ;
VAL_ 2566762238 FifthWheelSliderLockIndicator 0 "Not Locked" 1 "Locked" 2 "Error" 3 "Not available" ;
VAL_ 2566764030 ProtectLamp 0 "Lamp Off" 1 "Lamp On" 2 "Reserved" 3 "Not available" ;
VAL_ 2566764030 AmberWarningLamp 0 "Lamp Off" 1 "Lamp On" 2 "Reserved" 3 "Not available" ;
VAL_ 2566764030 RedStopLamp 0 "Lamp Off" 1 "Lamp On" 2 "Reserved" 3 "Not available" ;
VAL_ 2566764030 MalfunctionIndicatorLamp 0 "Lamp Off" 1 "Lamp On" 2 "Short MIL for WWH OBD" 3 "Not available" ;
VAL_ 2566764030 FlashProtectLamp 0 "Slow Flash (1 Hz, 50 % duty cycle)" 1 "Fast Flash (2 Hz or faster, 50% duty cycle)" 2 "Reserved" 3 "Unavailable / Do Not Flash" ;
VAL_ 2566764030 FlashAmberWarningLamp 0 "Slow Flash (1 Hz, 50 % duty cycle)" 1 "Fast Flash (2 Hz or faster, 50% duty cycle)" 2 "Reserved" 3 "Unavailable / Do Not Flash" ;
VAL_ 2566764030 FlashRedStopLamp 0 "Slow Flash (1 Hz, 50 % duty cycle)" 1 "Fast Flash (2 Hz or faster, 50% duty cycle)" 2 "Reserved" 3 "Unavailable / Do Not Flash" ;
VAL_ 2566764030 FlashMalfunctionIndicatorLamp 0 "Slow Flash (1 Hz, 50 % duty cycle)" 1 "Fast Flash (2 Hz or faster, 50% duty cycle)" 2 "Class C DTC  " 3 "Unavailable / Do Not Flash" ;
VAL_ 2566764030 SPNConversionMethod 0 "Convert SPN per Version 4" 1 "Convert SPN per Version 1, 2 or 3" ;
VAL_ 2566764542 SPNConversionMethod 0 "Convert SPN per Version 4" 1 "Convert SPN per Version 1, 2 or 3" ;
VAL_ 2566765310 FareboxEmergencyStatus 0 "Non-emergency condition" 1 "Emergency condition" 2 "Error Condition" 3 "Not available" ;
VAL_ 2566765310 FareboxAlarmIdentifier 0 "Voltage dropout" 1 "Voltage restored" 2 "Probe started" 3 "Probe completed" 4 "Cashbox removed" 5 "Cashbox restored" 6 "Cashbox door timeout" 7 "Cashbox opened" 8 "Insufficient fare accepted" 9 "Coinbox 75% full" 10 "Coinbox full" 11 "Currency box 75% full" 12 "Currency box less than 75% full" 13 "Currency box full" 14 "Card/pass box 75% full" 15 "Card/pass box less than 75% full" 16 "Card/pass box full" 17 "Coin de-jam operated" 18 "Farebox set in manual bypass" 19 "Farebox reset to automatic mode" 20 "Pass/transfer jam" 21 "Pass/transfer jam cleared" 22 "Paper currency jam" 23 "Paper currency jam cleared" 24 "Maintenance access in service" 25 "Maintenance access out of service" ;
VAL_ 2566765566 TransactionType 0 "Cash" 1 "Token" 2 "Ticket" 3 "Pass" 4 "Card" 5 "Permit" 6 "Transfer" 7 "Free" ;
VAL_ 2566765566 TypeOfFare 0 "Cash/No detail" 1 "Token A" 2 "Token B" 3 "Ticket A" 4 "Ticket B" 5 "Pass A" 6 "Pass B" ;
VAL_ 2566765566 PaymentDetails 0 "Not an upgrade" 1 "Cash" 2 "Token" 3 "Ticket" 4 "Pass" 5 "Card" ;
VAL_ 2566765566 TypeOfService 0 "Local service" 1 "Express service" ;
VAL_ 2566765566 TransferType 0 "North" 1 "South" 2 "East" 3 "West" 4 "In" 5 "Out" ;
VAL_ 2566765822 FareboxServiceStatus 0 "Farebox out of service" 1 "Farebox in service" 2 "Error Condition" 3 "Not available" ;
VAL_ 2566765822 TripStatus 0 "Undefined" 1 "Trip start" 2 "Trip end" 3 "Undefined" 4 "Undefined" 5 "Layover start" 6 "Layover end" 7 "Undefined" ;
VAL_ 2566765822 TripDirection 0 "North" 1 "South" 2 "East" 3 "West" 4 "In" 5 "Out" ;
VAL_ 2566766078 RangeCodeEnable 0 "Range code not used for interleaved data" 1 "Range code used for interleaved data" 2 "Error condition" 3 "Not available" ;
VAL_ 2566766078 TransitRouteIDUsage 0 "Transit route ID not used" 1 "Transit route ID used" 2 "Error condition" 3 "Not available" ;
VAL_ 2566766078 IntersectionPreemptionRqResponse 0 "Message is a request directed to the emitter" 1 "Message is a response from the emitter" 2 "Error condition" 3 "Not available" ;
VAL_ 2566766078 PriorityOfResponseSentByEmitter 0 "Reserved" 1 "Low priority" 2 "Probe priority" 3 "High priority" 9 "Priority set by hardware to low priority" 10 "Priority set by hardware to probe priority" 11 "Priority set by hardware to high priority" 14 "Error condition" 15 "Not available" ;
VAL_ 2566766078 TransitDoorEnable 0 "Ignore transit door status" 1 "Transit door status override" 2 "Error condition" 3 "Not available" ;
VAL_ 2566766078 StrobeActivationControlStatus 0 "Deactivate strobe" 1 "Activate strobe" 2 "Error condition" 3 "Not available" ;
VAL_ 2566766846 TypeOfPassengerCount 0 "absolute passenger count" 1 "boarding passenger" 2 "exiting passenger" 3 "boarding passenger (second passenger stream)" 4 "exiting passenger (second passenger stream)" 254 "error indicator" 255 "not available" ;
VAL_ 2566766846 SilentAlarmStatus 0 "Off" 1 "On" 2 "Error condition" 3 "Not available" ;
VAL_ 2566766846 VehicleUseStatus 0 "Normal use" 1 "Unauthorized use" 2 "Error condition" 3 "Not available" ;
VAL_ 2566766846 TransitRunStatus 0 "Off" 1 "On" 2 "Error condition" 3 "Not available" ;
VAL_ 2566767358 FuelType 0 "NONE" 1 "GAS" 2 "METH" 3 "ETH" 4 "DSL" 5 "LPG" 6 "CNG" 7 "PROP" 8 "ELEC" 9 "BI_GAS" 10 "BI_METH" 11 "BI_ETH" 12 "BI_LPG" 13 "BI_CNG" 14 "BI_PROP" 15 "BI_ELEC" 16 "BI_MIX" 17 "HYB_GAS" 18 "HYB_ETH" 19 "HYB_DSL" 20 "HYB_ELEC" 21 "HYB_MIX" 22 "HYB_REG" 23 "NG" 24 "BI_NG" 25 "BI_DSL" 26 "NG_COMP" 27 "DUA_DSL_CNG" 28 "DUA_DSL_LNG" 29 "FUEL_CELL" 30 "HYDRO_COM_ENG" 254 "Error" 255 "Not available" ;
VAL_ 2566767358 EngineFuelIsolationControl 0 "Gaseous Fuel Migration is Prevented" 1 "Gaseous Fuel is Used" 2 "Reserved" 3 "Don't care / take no action" ;
VAL_ 2566767870 BrakeTemperatureWarning 0 "Not Active" 1 "Active" 2 "Reserved" 3 "not available" ;
VAL_ 2566767870 HaltBrakeMode 0 "Inactive" 1 "Active" 2 "Active, but not functioning properly" 6 "Halt brake not functional" 7 "Not available" ;
VAL_ 2566767870 HillHolderMode 0 "Inactive" 1 "Active" 2 "Active change to inactive" 3 "Active activate brake" 4 "Reserved" 5 "Reserved" 6 "Hill holder not functional" 7 "Not available" ;
VAL_ 2566767870 FoundationBrakeUse 0 "Foundation brakes not in use" 1 "Foundation brakes in use" 2 "Reserved" 3 "Not available" ;
VAL_ 2566767870 XBRSystemState 0 "Any external brake" 1 "Only external brake XBR Priority 00" 2 "No external brake" 3 "not available" ;
VAL_ 2566767870 XBRActiveControlMode 0 "No brake" 1 "Driver's brake" 2 "Addition mode of XBR" 3 "Maximum mode of XBR" 15 "Not available" ;
VAL_ 2566767870 ParkingBrakeActuatorFullyActvtd 0 "Parking Brake Actuator not fully activated" 1 "Parking Brake Actuator fully activated" 2 "Error" 3 "Not available" ;
VAL_ 2566767870 EmergencyBrakingActive 0 "inactive" 1 "active" 2 "reserved" 3 "not available" ;
VAL_ 2566767870 RailroadMode 0 "Inactive (Driving mode: Steer Axle on ground)" 1 "Active (Railroad mode: Steer Axle lifted off ground)" 2 "Error" 3 "Not available" ;
VAL_ 2566768382 EngineStartEnableDevice1 0 "start enable OFF" 1 "start enable ON" 2 "reserved" 3 "not available" ;
VAL_ 2566768382 EngineStartEnableDevice2 0 "start enable OFF" 1 "start enable ON" 2 "reserved" 3 "not available" ;
VAL_ 2566768382 EngineStartEnableDevice1Conf 0 "no start enable device 1 installed" 1 "glow plugs installed" 2 "fuelled start installed" 3 "ether injection installed" 4 "electric intake air heater installed" 15 "not available" ;
VAL_ 2566768382 EngineStartEnableDevice2Conf 0 "no start enable device 2 installed" 1 "glow plugs installed" 2 "fuelled start installed" 3 "ether injection installed" 4 "electric intake air heater installed" 15 "not available" ;
VAL_ 2566768382 EngineColdStartFuelIgniterRelay 0 "Off" 1 "On" 2 "Reserved" 3 "Don't care/take no action" ;
VAL_ 2566768382 EngColdStartFuelIgntrRelayFdbck 0 "Off" 1 "On" 2 "Error" 3 "Not available" ;
VAL_ 2566768638 EngineAuxiliaryGovernorState 0 "Control State is Auxiliary Governor disabled" 1 "Control State is Auxiliary Governor enabled" 2 "SAE reserved" 3 "Not available" ;
VAL_ 2566768638 EngineMultiUnitSyncState 0 "Control State is Functionality disabled (off)" 1 "Control State is Functionality enabled (on)" 2 "SAE reserved" 3 "Not available" ;
VAL_ 2566768638 EngineAltLowIdleSelectState 0 "Normal idle state" 1 "Alternate idle state" 2 "SAE reserved" 3 "not available" ;
VAL_ 2566768638 EngineAlternateRatingSelectState 0 "Control state is Maximum Power Fueling" 1 "Control state is Alternate Power Fueling 1 " 2 "Control state is Alternate Power Fueling 2 " 3 "Control state is Alternate Power Fueling 3" 254 "SAE reserved" 255 "Not available" ;
VAL_ 2566768638 EngineDroopAccl1SelectState 0 "Control state is Normal Droop Setting" 14 "SAE reserved" 15 "Not available" ;
VAL_ 2566768638 EngineAltDroopAccl2SelectState 0 "Control's state is Normal Droop Setting" 14 "SAE reserved" 15 "Not available" ;
VAL_ 2566768638 EngineDroopRemoteAcclSelectState 0 "Control state is Normal Droop Setting" 14 "SAE reserved" 15 "Not available" ;
VAL_ 2566768638 EngineDroopAuxInputSelectState 0 "Control state is Normal Droop Setting" 14 "SAE reserved" 15 "Not available" ;
VAL_ 2566768638 EngineTorqueCurveSelection 0 "Torque is not selected" 1 "Torque Curve 1 is selected" 2 "Torque Curve 2 is selected" 14 "Error" 15 "Not supported" ;
VAL_ 2566768638 EngineOperatingModeSelection 0 "Engine not operating in a specific Engine Operating Mode" 1 "Engine Operating Mode 1 is selected" 2 "Engine Operating Mode 2 is selected" 3 "Engine Operating Mode 3 is selected" 4 "Engine Operating Mode 4 is selected" 5 "Engine Operating Mode 5 is selected" 6 "Engine Operating Mode 6 is selected" 7 "Engine Operating Mode 7 is selected" 8 "Engine Operating Mode 8 is selected" 9 "Engine Operating Mode 9 is selected" 10 "Engine Operating Mode 10 is selected" 11 "Engine Operating Mode 11 is selected" 12 "Engine Operating Mode 12 is selected" 13 "Engine Operating Mode 13 is selected" 14 "Error" 15 "Not available" ;
VAL_ 2566768894 EngOprtrPrmryIntrmedSpdSlctState 0 "Control state for ISC is not requested" 1 "Control state is ISC Setting 1" 2 "Control state is ISC Setting 2" 3 "Control state is ISC Setting 3" 4 "Control state is ISC Setting 4" 5 "Control state is ISC Setting 5" 6 "Control state is ISC Setting 6" 7 "Control state is ISC Setting 7" 8 "Control state is ISC Setting 8" 9 "Control state is ISC Setting 9" 10 "Control state is ISC Setting 10" 11 "Control state is ISC Setting 11" 12 "Control state is ISC Setting 12" 13 "Control state is ISC Setting 13" 14 "SAE reserved" 15 "not available" ;
VAL_ 2566769406 EngOprtrPrmryIntrmedSpeedSelect 0 "ISC functionality is not requested" 1 "ISC Setting 1 is selected" 2 "ISC Setting 2 is selected" 3 "ISC Setting 3 is selected" 4 "ISC Setting 4 is selected" 5 "ISC Setting 5 is selected" 6 "ISC Setting 6 is selected" 7 "ISC Setting 7 is selected" 8 "ISC Setting 8 is selected" 9 "ISC Setting 9 is selected" 10 "ISC Setting 10 is selected" 11 "ISC Setting 11 is selected" 12 "ISC Setting 12 is selected" 13 "ISC Setting 13 is selected" 14 "error condition" 15 "not available" ;
VAL_ 2566769662 EngineAuxiliaryGovernorSwitch 0 "Auxiliary Governor is disabled" 1 "Auxiliary Governor is enabled" 2 "Error condition" 3 "Not available" ;
VAL_ 2566769662 EngineSynchronizationSwitch 0 "Functionality is disabled (off)" 1 "Functionality is enabled (on)" 2 "Error" 3 "Not available or Unused" ;
VAL_ 2566769662 EngineAlternateLowIdleSwitch 0 "Default low idle point is selected" 1 "Alternate low idle point is selected" 2 "Error" 3 "Not available or Unused" ;
VAL_ 2566769662 EngineAlternateRatingSelect 0 "Maximum Power Fueling" 1 "Alternate Power Fueling 1" 2 "Alternate Power Fueling 2" 3 "Alternate Power Fueling 3" 254 "Error condition." 255 "Not available" ;
VAL_ 2566769662 EngineDroopAccelerator1Select 0 "Normal Droop Setting is selected" 14 "Error condition" 15 "Not available" ;
VAL_ 2566769662 EngineDroopAccelerator2Select 0 "Normal Droop Setting is selected" 14 "Error condition" 15 "Not available" ;
VAL_ 2566769662 EngineDroopRemoteAcclSelect 0 "Normal Droop Setting is selected" 14 "Error condition" 15 "Not available" ;
VAL_ 2566769662 EngineDroopAuxiliaryInputSelect 0 "Normal Droop Setting is selected" 14 "Error condition" 15 "Not available" ;
VAL_ 2566769662 EngineTorqueCurveSelectionCmd 0 "Torque is not selected" 1 "Torque Curve 1 is selected" 2 "Torque Curve 2 is selected" 14 "SAE reserved" 15 "Not supported" ;
VAL_ 2566769662 EngineOperatingModeCommand 0 "Not presently requesting a specific Engine Operating Mode be used" 1 "Engine Operating Mode 1 is requested" 2 "Engine Operating Mode 2 is requested" 3 "Engine Operating Mode 3 is requested" 4 "Engine Operating Mode 4 is requested" 5 "Engine Operating Mode 5 is requested" 6 "Engine Operating Mode 6 is requested" 7 "Engine Operating Mode 7 is requested" 8 "Engine Operating Mode 8 is requested" 9 "Engine Operating Mode 9 is requested" 10 "Engine Operating Mode 10 is requested" 11 "Engine Operating Mode 11 is requested" 12 "Engine Operating Mode 12 is requested" 13 "Engine Operating Mode 13 is requested" 14 "SAE Reserved" 15 "Not available / Take no action" ;
VAL_ 2365443326 WorkLightSwitch 0 "Off" 1 "Work Light Combination #1 On" 2 "Work Light Combination #2 On" 3 "Work Light Combination #3 On" 4 "Work Light Combination #4 On" 14 "Error" 15 "Not available (do not change)" ;
VAL_ 2365443326 MainLightSwitch 0 "Off" 1 "Park On" 2 "Headlight On" 3 "Headlight and Park On" 4 "Automatic Lights" 8 "Delayed Off" 14 "Error" 15 "Not available (do not change)" ;
VAL_ 2365443326 TurnSignalSwitch 0 "No Turn being signaled" 1 "Left Turn to be Flashing" 2 "Right turn to be Flashing" 14 "Error" 15 "Not available" ;
VAL_ 2365443326 HazardLightSwitch 0 "Hazard Lamps to be Off" 1 "Hazard Lamps to be Flashing" 2 "Error" 3 "Not available (do not change)" ;
VAL_ 2365443326 HighLowBeamSwitch 0 "Low Beam Selected" 1 "High Beam Selected" 2 "Error" 3 "Not available (do not change)" ;
VAL_ 2566770174 FrontNonOperatorWiperSwitch 0 "Off" 1 "Low" 2 "Medium" 3 "High" 4 "Delayed 1" 5 "Delayed 2" 6 "Mist" 15 "Not available" ;
VAL_ 2566770174 FrontOperatorWiperSwitch 0 "Off" 1 "Low" 2 "Medium" 3 "High" 4 "Delayed 1" 5 "Delayed 2" 6 "Mist" 15 "Not available" ;
VAL_ 2566770174 RearWiperSwitch 0 "Off" 1 "Low" 2 "Medium" 3 "High" 4 "Delayed 1" 5 "Delayed 2" 6 "Mist" 15 "Not available" ;
VAL_ 2566770174 FrontNonOperatorWasherSwitch 0 "Off" 1 "Low" 2 "Medium" 3 "High" 7 "Not available (do not change)" ;
VAL_ 2566770174 FrontOperatorWasherSwitch 0 "Off" 1 "Low" 2 "Medium" 3 "High" 7 "Not available (do not change)" ;
VAL_ 2566770174 RearWasherFunction 0 "Off" 1 "Low" 2 "Medium" 3 "High" 7 "Not available (do not change)" ;
VAL_ 2633880062 FMSStandardDiagnosticsSupported 0 "Diagnostics Is Not Supported" 1 "Diagnostics Is Supported" 2 "Reserved" 3 "Don't care" ;
VAL_ 2633880062 FMSStandardRequestsSupported 0 "On request mode is not supported" 1 "On request mode is supported" 2 "Reserved" 3 "Don't care" ;
VAL_ 2566771966 TransferCaseSelectorSwitch 0 "2 wheel high (Normal or 'On Highway' Range)" 1 "4 wheel high (Normal or 'On Highway' Range)" 2 "Neutral" 3 "2 wheel low (or 'Off Highway' Range)" 4 "4 wheel low (or 'Off Highway' Range)" 5 "Reserved for SAE assignment" 6 "Error indicator" 7 "Not available" ;
VAL_ 2566771966 FifthWheelReleaseControl 0 "Coupler Locked" 1 "Coupler Unlocked" 2 "Error" 3 "Not Available" ;
VAL_ 2566771966 FifthWhlReleaseCtrlSecurityLckt 0 "Fifth wheel release Disabled" 1 "Fifth wheel release Enabled" 2 "Error   " 3 "Not Available" ;
VAL_ 2566771966 VehicleTrailerStatus 0 "Trailer is not detected" 1 "Trailer is detected" 2 "Error" 3 "Not available" ;
VAL_ 2566771966 TransmissionOilLevelRequest 0 "No transmission oil level reading desired" 1 "Transmission oil level reading desired" 2 "Reserved" 3 "Don't care / take no action" ;
VAL_ 2566772222 EngVarGmtryTurboAirCtrlShtoffVlv 0 "VGT Air Control Shutoff Valve is Off" 1 "VGT Air Control Shutoff Valve is On" 2 "Reserved" 3 "Not available" ;
VAL_ 2566772222 EngineFuelControlMode 0 "Open loop" 1 "Closed loop" 2 "SAE reserved" 3 "Not available" ;
VAL_ 2566772222 EngVariableGmtryTurbo1CtrlMde 0 "Open loop" 1 "Closed loop" 2 "SAE reserved" 3 "Not available" ;
VAL_ 2365445886 Jystck1XAxsNeutralPositionStatus 0 "Not in Neutral Position" 1 "In Neutral Position" 2 "Error Indicator" 3 "Not Available" ;
VAL_ 2365445886 Jystck1XAxsLvrLftNegPosStatus 0 "Not on negative side of Neutral" 1 "On negative side of Neutral" 2 "Error Indicator" 3 "Not Available" ;
VAL_ 2365445886 Jystck1XAxsLvrRightPstvPosStatus 0 "Not on Positive side of Neutral" 1 "On positive side of Neutral" 2 "Error Indicator" 3 "Not Available" ;
VAL_ 2365445886 Jystck1YAxsNeutralPositionStatus 0 "Not in Neutral Position" 1 "In Neutral Position" 2 "Error Indicator" 3 "Not Available" ;
VAL_ 2365445886 Jystck1YAxsLvrBackNegPosStatus 0 "Not on negative side of Neutral" 1 "On negative side of Neutral" 2 "Error Indicator" 3 "Not Available" ;
VAL_ 2365445886 Jystck1YAxsLvrFrwdPstvPosStatus 0 "Not on Positive side of Neutral" 1 "On positive side of Neutral" 2 "Error Indicator" 3 "Not Available" ;
VAL_ 2365445886 Jystck1YAxsDetentPositionStatus 0 "Not in the Detent Position" 1 "In the Detent Position" 2 "Error Indicator" 3 "Not Available" ;
VAL_ 2365445886 Jystck1XAxsDetentPositionStatus 0 "Not in the Detent Position" 1 "In the Detent Position" 2 "Error Indicator" 3 "Not Available" ;
VAL_ 2365445886 Joystick1Button4PressedStatus 0 "Button not pressed" 1 "Button pressed" 2 "Error Indicator" 3 "Not Available" ;
VAL_ 2365445886 Joystick1Button3PressedStatus 0 "Button not pressed" 1 "Button pressed" 2 "Error Indicator" 3 "Not Available" ;
VAL_ 2365445886 Joystick1Button2PressedStatus 0 "Button not pressed" 1 "Button pressed" 2 "Error Indicator" 3 "Not Available" ;
VAL_ 2365445886 Joystick1Button1PressedStatus 0 "Button not pressed" 1 "Button pressed" 2 "Error Indicator" 3 "Not Available" ;
VAL_ 2365445886 Joystick1Button8PressedStatus 0 "Button not pressed" 1 "Button pressed" 2 "Error Indicator" 3 "Not Available" ;
VAL_ 2365445886 Joystick1Button7PressedStatus 0 "Button not pressed" 1 "Button pressed" 2 "Error Indicator" 3 "Not Available" ;
VAL_ 2365445886 Joystick1Button6PressedStatus 0 "Button not pressed" 1 "Button pressed" 2 "Error Indicator" 3 "Not Available" ;
VAL_ 2365445886 Joystick1Button5PressedStatus 0 "Button not pressed" 1 "Button pressed" 2 "Error Indicator" 3 "Not Available" ;
VAL_ 2365445886 Joystick1Button12PressedStatus 0 "Button not pressed" 1 "Button pressed" 2 "Error Indicator" 3 "Not Available" ;
VAL_ 2365445886 Joystick1Button11PressedStatus 0 "Button not pressed" 1 "Button pressed" 2 "Error Indicator" 3 "Not Available" ;
VAL_ 2365445886 Joystick1Button10PressedStatus 0 "Button not pressed" 1 "Button pressed" 2 "Error Indicator" 3 "Not Available" ;
VAL_ 2365445886 Joystick1Button9PressedStatus 0 "Button not pressed" 1 "Button pressed" 2 "Error Indicator" 3 "Not Available" ;
VAL_ 2365446142 Jystck1GrpXAxsNtrlPositionStatus 0 "Not in Neutral Position" 1 "In Neutral Position" 2 "Error Indicator" 3 "Not Available" ;
VAL_ 2365446142 Jystck1GrpXAxsLvrLftNegPosStatus 0 "Not on negative side of Neutral" 1 "On negative side of Neutral" 2 "Error Indicator" 3 "Not Available" ;
VAL_ 2365446142 Jystck1GrpXAxsLvrRghtPstvPosStat 0 "Not on Positive side of Neutral" 1 "On positive side of Neutral" 2 "Error Indicator" 3 "Not Available" ;
VAL_ 2365446142 Jystck1GrpYAxsNtrlPositionStatus 0 "Not in Neutral Position" 1 "In Neutral Position" 2 "Error Indicator" 3 "Not Available" ;
VAL_ 2365446142 Jystck1GrpYAxsLvrBackNegPosStat 0 "Not on negative side of Neutral" 1 "On negative side of Neutral" 2 "Error Indicator" 3 "Not Available" ;
VAL_ 2365446142 Jystck1GrpYAxsLvrFrwdPstvPosStat 0 "Not on Positive side of Neutral" 1 "On positive side of Neutral" 2 "Error Indicator" 3 "Not Available" ;
VAL_ 2365446142 Jystck1ThetaAxsNtrlPosStatus 0 "Not in Neutral Position" 1 "In Neutral Position" 2 "Error Indicator" 3 "Not Available" ;
VAL_ 2365446142 Jystck1ThtAxsCntrClckwsNegPsStat 0 "Not on negative side of Neutral" 1 "On negative side of Neutral" 2 "Error Indicator" 3 "Not Available" ;
VAL_ 2365446142 Jystck1ThetaAxsClckwsPstvPosStat 0 "Not on Positive side of Neutral" 1 "On positive side of Neutral" 2 "Error Indicator" 3 "Not Available" ;
VAL_ 2365446142 Jystck1ThetaAxsDetentPosStatus 0 "Not in the Detent Position" 1 "In the Detent Position" 2 "Error Indicator" 3 "Not Available" ;
VAL_ 2365446142 Jystck1GrpYAxsDetentPosStatus 0 "Not in the Detent Position" 1 "In the Detent Position" 2 "Error Indicator" 3 "Not Available" ;
VAL_ 2365446142 Jystck1GrpXAxsDetentPosStatus 0 "Not in the Detent Position" 1 "In the Detent Position" 2 "Error Indicator" 3 "Not Available" ;
VAL_ 2365446142 Joystick1Button16PressedStatus 0 "Button not pressed" 1 "Button pressed" 2 "Error Indicator" 3 "Not Available" ;
VAL_ 2365446142 Joystick1Button15PressedStatus 0 "Button not pressed" 1 "Button pressed" 2 "Error Indicator" 3 "Not Available" ;
VAL_ 2365446142 Joystick1Button14PressedStatus 0 "Button not pressed" 1 "Button pressed" 2 "Error Indicator" 3 "Not Available" ;
VAL_ 2365446142 Joystick1Button13PressedStatus 0 "Button not pressed" 1 "Button pressed" 2 "Error Indicator" 3 "Not Available" ;
VAL_ 2365446398 Jystck2XAxsNeutralPositionStatus 0 "Not in Neutral Position" 1 "In Neutral Position" 2 "Error Indicator" 3 "Not Available" ;
VAL_ 2365446398 Jystck2XAxsLvrLftNegPosStatus 0 "Not on negative side of Neutral" 1 "On negative side of Neutral" 2 "Error Indicator" 3 "Not Available" ;
VAL_ 2365446398 Jystck2XAxsLvrRightPstvPosStatus 0 "Not on Positive side of Neutral" 1 "On positive side of Neutral" 2 "Error Indicator" 3 "Not Available" ;
VAL_ 2365446398 Jystck2YAxsNeutralPositionStatus 0 "Not in Neutral Position" 1 "In Neutral Position" 2 "Error Indicator" 3 "Not Available" ;
VAL_ 2365446398 Jystck2YAxsLvrBackNegPosStatus 0 "Not on negative side of Neutral" 1 "On negative side of Neutral" 2 "Error Indicator" 3 "Not Available" ;
VAL_ 2365446398 Jystck2YAxsLvrFrwdPstvPosStatus 0 "Not on Positive side of Neutral" 1 "On positive side of Neutral" 2 "Error Indicator" 3 "Not Available" ;
VAL_ 2365446398 Jystck2YAxsDetentPositionStatus 0 "Not in the Detent Position" 1 "In the Detent Position" 2 "Error Indicator" 3 "Not Available" ;
VAL_ 2365446398 Jystck2XAxsDetentPositionStatus 0 "Not in the Detent Position" 1 "In the Detent Position" 2 "Error Indicator" 3 "Not Available" ;
VAL_ 2365446398 Joystick2Button4PressedStatus 0 "Button not pressed" 1 "Button pressed" 2 "Error Indicator" 3 "Not Available" ;
VAL_ 2365446398 Joystick2Button3PressedStatus 0 "Button not pressed" 1 "Button pressed" 2 "Error Indicator" 3 "Not Available" ;
VAL_ 2365446398 Joystick2Button2PressedStatus 0 "Button not pressed" 1 "Button pressed" 2 "Error Indicator" 3 "Not Available" ;
VAL_ 2365446398 Joystick2Button1PressedStatus 0 "Button not pressed" 1 "Button pressed" 2 "Error Indicator" 3 "Not Available" ;
VAL_ 2365446398 Joystick2Button8PressedStatus 0 "Button not pressed" 1 "Button pressed" 2 "Error Indicator" 3 "Not Available" ;
VAL_ 2365446398 Joystick2Button7PressedStatus 0 "Button not pressed" 1 "Button pressed" 2 "Error Indicator" 3 "Not Available" ;
VAL_ 2365446398 Joystick2Button6PressedStatus 0 "Button not pressed" 1 "Button pressed" 2 "Error Indicator" 3 "Not Available" ;
VAL_ 2365446398 Joystick2Button5PressedStatus 0 "Button not pressed" 1 "Button pressed" 2 "Error Indicator" 3 "Not Available" ;
VAL_ 2365446398 Joystick2Button12PressedStatus 0 "Button not pressed" 1 "Button pressed" 2 "Error Indicator" 3 "Not Available" ;
VAL_ 2365446398 Joystick2Button11PressedStatus 0 "Button not pressed" 1 "Button pressed" 2 "Error Indicator" 3 "Not Available" ;
VAL_ 2365446398 Joystick2Button10PressedStatus 0 "Button not pressed" 1 "Button pressed" 2 "Error Indicator" 3 "Not Available" ;
VAL_ 2365446398 Joystick2Button9PressedStatus 0 "Button not pressed" 1 "Button pressed" 2 "Error Indicator" 3 "Not Available" ;
VAL_ 2365446654 Jystck2GrpXAxsNtrlPositionStatus 0 "Not on negative side of Neutral" 1 "On negative side of Neutral" 2 "Error Indicator" 3 "Not Available" ;
VAL_ 2365446654 Jystck2GrpXAxsLvrLftNegPosStatus 0 "Not on negative side of Neutral" 1 "On negative side of Neutral" 2 "Error Indicator" 3 "Not Available" ;
VAL_ 2365446654 Jystck2GrpXAxsLvrRghtPstvPosStat 0 "Not on Positive side of Neutral" 1 "On positive side of Neutral" 2 "Error Indicator" 3 "Not Available" ;
VAL_ 2365446654 Jystck2GrpYAxsNtrlPositionStatus 0 "Not in Neutral Position" 1 "In Neutral Position" 2 "Error Indicator" 3 "Not Available" ;
VAL_ 2365446654 Jystck2GrpYAxsLvrBackNegPosStat 0 "Not on negative side of Neutral" 1 "On negative side of Neutral" 2 "Error Indicator" 3 "Not Available" ;
VAL_ 2365446654 Jystck2GrpYAxsLvrFrwdPstvPosStat 0 "Not on Positive side of Neutral" 1 "On positive side of Neutral" 2 "Error Indicator" 3 "Not Available" ;
VAL_ 2365446654 Jystck2ThetaAxsNtrlPosStatus 0 "Not in Neutral Position" 1 "In Neutral Position" 2 "Error Indicator" 3 "Not Available" ;
VAL_ 2365446654 Jystck2ThtAxsCntrClckwsNegPsStat 0 "Not on negative side of Neutral" 1 "On negative side of Neutral" 2 "Error Indicator" 3 "Not Available" ;
VAL_ 2365446654 Jystck2ThetaAxsClckwsPstvPosStat 0 "Not on Positive side of Neutral" 1 "On positive side of Neutral" 2 "Error Indicator" 3 "Not Available" ;
VAL_ 2365446654 Jystck2ThetaAxsDetentPosStatus 0 "Not in the Detent Position" 1 "In the Detent Position" 2 "Error Indicator" 3 "Not Available" ;
VAL_ 2365446654 Jystck2GrpYAxsDetentPosStatus 0 "Not in the Detent Position" 1 "In the Detent Position" 2 "Error Indicator" 3 "Not Available" ;
VAL_ 2365446654 Jystck2GrpXAxsDetentPosStatus 0 "Not in the Detent Position" 1 "In the Detent Position" 2 "Error Indicator" 3 "Not Available" ;
VAL_ 2365446654 Joystick2Button16PressedStatus 0 "Button not pressed" 1 "Button pressed" 2 "Error Indicator" 3 "Not Available" ;
VAL_ 2365446654 Joystick2Button15PressedStatus 0 "Button not pressed" 1 "Button pressed" 2 "Error Indicator" 3 "Not Available" ;
VAL_ 2365446654 Joystick2Button14PressedStatus 0 "Button not pressed" 1 "Button pressed" 2 "Error Indicator" 3 "Not Available" ;
VAL_ 2365446654 Joystick2Button13PressedStatus 0 "Button not pressed" 1 "Button pressed" 2 "Error Indicator" 3 "Not Available" ;
VAL_ 2365446910 Jystck3XAxsNeutralPositionStatus 0 "Not in Neutral Position" 1 "In Neutral Position" 2 "Error Indicator" 3 "Not Available" ;
VAL_ 2365446910 Jystck3XAxsLvrLftNegPosStatus 0 "Not on negative side of Neutral" 1 "On negative side of Neutral" 2 "Error Indicator" 3 "Not Available" ;
VAL_ 2365446910 Jystck3XAxsLvrRightPstvPosStatus 0 "Not on Positive side of Neutral" 1 "On positive side of Neutral" 2 "Error Indicator" 3 "Not Available" ;
VAL_ 2365446910 Jystck3YAxsNeutralPositionStatus 0 "Not in Neutral Position" 1 "In Neutral Position" 2 "Error Indicator" 3 "Not Available" ;
VAL_ 2365446910 Jystck3YAxsLvrBackNegPosStatus 0 "Not on negative side of Neutral" 1 "On negative side of Neutral" 2 "Error Indicator" 3 "Not Available" ;
VAL_ 2365446910 Jystck3YAxsLvrFrwdPstvPosStatus 0 "Not on Positive side of Neutral" 1 "On positive side of Neutral" 2 "Error Indicator" 3 "Not Available" ;
VAL_ 2365446910 Jystck3YAxsDetentPositionStatus 0 "Not in the Detent Position" 1 "In the Detent Position" 2 "Error Indicator" 3 "Not Available" ;
VAL_ 2365446910 Jystck3XAxsDetentPositionStatus 0 "Not in the Detent Position" 1 "In the Detent Position" 2 "Error Indicator" 3 "Not Available" ;
VAL_ 2365446910 Joystick3Button4PressedStatus 0 "Button not pressed" 1 "Button pressed" 2 "Error Indicator" 3 "Not Available" ;
VAL_ 2365446910 Joystick3Button3PressedStatus 0 "Button not pressed" 1 "Button pressed" 2 "Error Indicator" 3 "Not Available" ;
VAL_ 2365446910 Joystick3Button2PressedStatus 0 "Button not pressed" 1 "Button pressed" 2 "Error Indicator" 3 "Not Available" ;
VAL_ 2365446910 Joystick3Button1PressedStatus 0 "Button not pressed" 1 "Button pressed" 2 "Error Indicator" 3 "Not Available" ;
VAL_ 2365446910 Joystick3Button8PressedStatus 0 "Button not pressed" 1 "Button pressed" 2 "Error Indicator" 3 "Not Available" ;
VAL_ 2365446910 Joystick3Button7PressedStatus 0 "Button not pressed" 1 "Button pressed" 2 "Error Indicator" 3 "Not Available" ;
VAL_ 2365446910 Joystick3Button6PressedStatus 0 "Button not pressed" 1 "Button pressed" 2 "Error Indicator" 3 "Not Available" ;
VAL_ 2365446910 Joystick3Button5PressedStatus 0 "Button not pressed" 1 "Button pressed" 2 "Error Indicator" 3 "Not Available" ;
VAL_ 2365446910 Joystick3Button12PressedStatus 0 "Button not pressed" 1 "Button pressed" 2 "Error Indicator" 3 "Not Available" ;
VAL_ 2365446910 Joystick3Button11PressedStatus 0 "Button not pressed" 1 "Button pressed" 2 "Error Indicator" 3 "Not Available" ;
VAL_ 2365446910 Joystick3Button10PressedStatus 0 "Button not pressed" 1 "Button pressed" 2 "Error Indicator" 3 "Not Available" ;
VAL_ 2365446910 Joystick3Button9PressedStatus 0 "Button not pressed" 1 "Button pressed" 2 "Error Indicator" 3 "Not Available" ;
VAL_ 2365447166 Jystck3GrpXAxsNtrlPositionStatus 0 "Not on negative side of Neutral" 1 "On negative side of Neutral" 2 "Error Indicator" 3 "Not Available" ;
VAL_ 2365447166 Jystck3GrpXAxsLvrLftNegPosStatus 0 "Not on negative side of Neutral" 1 "On negative side of Neutral" 2 "Error Indicator" 3 "Not Available" ;
VAL_ 2365447166 Jystck3GrpXAxsLvrRghtPstvPosStat 0 "Not on Positive side of Neutral" 1 "On positive side of Neutral" 2 "Error Indicator" 3 "Not Available" ;
VAL_ 2365447166 Jystck3GrpYAxsNtrlPositionStatus 0 "Not in Neutral Position" 1 "In Neutral Position" 2 "Error Indicator" 3 "Not Available" ;
VAL_ 2365447166 Jystck3GrpYAxsLvrBackNegPosStat 0 "Not on negative side of Neutral" 1 "On negative side of Neutral" 2 "Error Indicator" 3 "Not Available" ;
VAL_ 2365447166 Jystck3GrpYAxsLvrFrwdPstvPosStat 0 "Not on Positive side of Neutral" 1 "On positive side of Neutral" 2 "Error Indicator" 3 "Not Available" ;
VAL_ 2365447166 Jystck3ThetaAxsNtrlPosStatus 0 "Not in Neutral Position" 1 "In Neutral Position" 2 "Error Indicator" 3 "Not Available" ;
VAL_ 2365447166 Jystck3ThtAxsCntrClckwsNegPsStat 0 "Not on negative side of Neutral" 1 "On negative side of Neutral" 2 "Error Indicator" 3 "Not Available" ;
VAL_ 2365447166 Jystck3ThetaAxsClckwsPstvPosStat 0 "Not on Positive side of Neutral" 1 "On positive side of Neutral" 2 "Error Indicator" 3 "Not Available" ;
VAL_ 2365447166 Jystck3ThetaAxsDetentPosStatus 0 "Not in the Detent Position" 1 "In the Detent Position" 2 "Error Indicator" 3 "Not Available" ;
VAL_ 2365447166 Jystck3GrpYAxsDetentPosStatus 0 "Not in the Detent Position" 1 "In the Detent Position" 2 "Error Indicator" 3 "Not Available" ;
VAL_ 2365447166 Jystck3GrpXAxsDetentPosStatus 0 "Not in the Detent Position" 1 "In the Detent Position" 2 "Error Indicator" 3 "Not Available" ;
VAL_ 2365447166 Joystick3Button16PressedStatus 0 "Button not pressed" 1 "Button pressed" 2 "Error Indicator" 3 "Not Available" ;
VAL_ 2365447166 Joystick3Button15PressedStatus 0 "Button not pressed" 1 "Button pressed" 2 "Error Indicator" 3 "Not Available" ;
VAL_ 2365447166 Joystick3Button14PressedStatus 0 "Button not pressed" 1 "Button pressed" 2 "Error Indicator" 3 "Not Available" ;
VAL_ 2365447166 Joystick3Button13PressedStatus 0 "Button not pressed" 1 "Button pressed" 2 "Error Indicator" 3 "Not Available" ;
VAL_ 2566774014 EngThrottleSyncMdeStat 0 "Not Synchronized" 1 "Synchronized Center" 2 "Synchronized Port" 3 "Synchronized Starboard" 4 "Synchronized Master" 15 "Take no action" ;
VAL_ 2566774014 TrollingModeStatus 0 "Trolling mode is OFF." 1 "Trolling mode is ACTIVE." 2 "Reserved" 3 "Take no action" ;
VAL_ 2566774014 SlowVesselModeStatus 0 "Slow vessel mode is OFF." 1 "Slow vessel mode is ACTIVE." 2 "Reserved" 3 "Take no action" ;
VAL_ 2566774014 EngineMarineOperatingModeStatus 0 "Maintenance Mode" 1 "Electrical Power Generation (EPG) mode" 2 "Propulsion Constant Speed Mode" 3 "Propulsion Variable Speed Mode" 6 "Error" 7 "Not available" ;
VAL_ 2633883646 FrontWheelDriveActuatorStatus 0 "Front Wheel Drive Actuator not engaged" 1 "Front Wheel Drive Actuator engaged" 2 "Error" 3 "Not Available" ;
VAL_ 2566775294 AirConditionerCompressorStatus 0 "Air Conditioner Compressor is OFF" 1 "Air Conditioner Compressor is ON" 2 "Error" 3 "Not Available" ;
VAL_ 2365449982 HydrBrkPressWarningStateCircuit1 0 "Pressure level sufficient" 1 "Pressure level below warning level" 2 "Error indicator" 3 "Not available" ;
VAL_ 2365449982 HydrBrkPressWarningStateCircuit2 0 "Pressure level sufficient" 1 "Pressure level below warning level" 2 "Error indicator" 3 "Not available" ;
VAL_ 2365449982 HydrBrkPressSupplyStateCircuit1 0 "Supply is not reliable" 1 "Supply is reliable" 2 "Error indicator" 3 "Not available" ;
VAL_ 2365449982 HydrBrkPressSupplyStateCircuit2 0 "Supply is not reliable" 1 "Supply is reliable" 2 "Error indicator" 3 "Not available" ;
VAL_ 2365449982 HydrBrkSystemAudibleWarningCmd 0 "Audible warning off" 1 "Audible warning on" 2 "Reserved" 3 "Don't care" ;
VAL_ 2365449982 HydraulicBrakeFluidLevelSwitch 0 "Fluid level is not sufficient" 1 "Fluid level is sufficient" 2 "Error indicator" 3 "Not available" ;
VAL_ 2365450238 Bus1UtilityDeadBus 0 "Bus is not dead" 1 "Bus is dead" 2 "Error" 3 "Not Available or Not Installed" ;
VAL_ 2365450238 Bus1UtilityPhaseMatch 0 "Phases do not match" 1 "Phases match" 2 "Error" 3 "Not Available or Not Installed" ;
VAL_ 2365450238 Bus1UtilityFrequencyMatch 0 "Frequencies do not match" 1 "Frequencies match" 2 "Error" 3 "Not Available or Not Installed" ;
VAL_ 2365450238 Bus1UtilityVoltageMatch 0 "Voltages do not match" 1 "Voltages match" 2 "Error" 3 "Not Available or Not Installed" ;
VAL_ 2365450238 Bus1UtilityInSync 0 "Not synchronized" 1 "Synchronized" 2 "Error" 3 "Not Available or Not Installed" ;
VAL_ 2365450494 Bus1GeneratorDeadBus 0 "Bus is not dead" 1 "Bus is dead" 2 "Error" 3 "Not Available or Not Installed" ;
VAL_ 2365450494 Bus1GeneratorPhaseMatch 0 "Phases do not match" 1 "Phases match" 2 "Error" 3 "Not Available or Not Installed" ;
VAL_ 2365450494 Bus1GeneratorFrequencyMatch 0 "Frequencies do not match" 1 "Frequencies match" 2 "Error" 3 "Not Available or Not Installed" ;
VAL_ 2365450494 Bus1GeneratorVoltageMatch 0 "Voltages do not match" 1 "Voltages match" 2 "Error" 3 "Not Available or Not Installed" ;
VAL_ 2365450494 Bus1GeneratorInSync 0 "Not synchronized" 1 "Synchronized" 2 "Error" 3 "Not Available or Not Installed" ;
VAL_ 2365452030 UtilityPhaseCPowerFactorLagging 0 "Leading" 1 "Lagging" 2 "Error" 3 "Not Available or Not Installed" ;
VAL_ 2365452798 UtilityPhaseBPowerFactorLagging 0 "Leading" 1 "Lagging" 2 "Error" 3 "Not Available or Not Installed" ;
VAL_ 2365453566 UtilityPhaseAPowerFactorLagging 0 "Leading" 1 "Lagging" 2 "Error" 3 "Not Available or Not Installed" ;
VAL_ 2365454334 UtilityOverallPowerFactorLagging 0 "Leading" 1 "Lagging" 2 "Error" 3 "Not Available or Not Installed" ;
VAL_ 2365455358 GenPhaseCPowerFactorLagging 0 "Leading" 1 "Lagging" 2 "Error" 3 "Not Available or Not Installed" ;
VAL_ 2365456126 GenPhaseBPowerFactorLagging 0 "Leading" 1 "Lagging" 2 "Error" 3 "Not Available or Not Installed" ;
VAL_ 2365456894 GenPhaseAPowerFactorLagging 0 "Leading" 1 "Lagging" 2 "Error" 3 "Not Available or Not Installed" ;
VAL_ 2365457662 GenOverallPowerFactorLagging 0 "Leading" 1 "Lagging" 2 "Error" 3 "Not Available or Not Installed" ;
VAL_ 2566799614 RunningLight 0 "De-activated" 1 "Activated" 2 "Fault Detected" 3 "Not Available" ;
VAL_ 2566799614 AlternateBeamHeadLightData 0 "De-activated" 1 "Activated" 2 "Fault Detected" 3 "Not Available" ;
VAL_ 2566799614 LowBeamHeadLightData 0 "De-activated" 1 "Activated" 2 "Fault Detected" 3 "Not Available" ;
VAL_ 2566799614 HighBeamHeadLightData 0 "De-activated" 1 "Activated" 2 "Fault Detected" 3 "Not Available" ;
VAL_ 2566799614 TractorFrontFogLights 0 "De-activated" 1 "Activated" 2 "Fault Detected" 3 "Not Available" ;
VAL_ 2566799614 RotatingBeaconLight 0 "De-activated" 1 "Activated" 2 "Fault Detected" 3 "Not Available" ;
VAL_ 2566799614 RightTurnSignalLights 0 "De-activated" 1 "Activated" 2 "Fault Detected" 3 "Not Available" ;
VAL_ 2566799614 LeftTurnSignalLights 0 "De-activated" 1 "Activated" 2 "Fault Detected" 3 "Not Available" ;
VAL_ 2566799614 BackUpLightAndAlarmHorn 0 "De-activated" 1 "Activated" 2 "Fault Detected" 3 "Not Available" ;
VAL_ 2566799614 CenterStopLight 0 "De-activated" 1 "Activated" 2 "Fault Detected" 3 "Not Available" ;
VAL_ 2566799614 RightStopLight 0 "De-activated" 1 "Activated" 2 "Fault Detected" 3 "Not Available" ;
VAL_ 2566799614 LeftStopLight 0 "De-activated" 1 "Activated" 2 "Fault Detected" 3 "Not Available" ;
VAL_ 2566799614 ImplementClearanceLight 0 "De-activated" 1 "Activated" 2 "Fault Detected" 3 "Not Available" ;
VAL_ 2566799614 TractorClearanceLight 0 "De-activated" 1 "Activated" 2 "Fault Detected" 3 "Not Available" ;
VAL_ 2566799614 ImplementMarkerLight 0 "De-activated" 1 "Activated" 2 "Fault Detected" 3 "Not Available" ;
VAL_ 2566799614 TractorMarkerLight 0 "De-activated" 1 "Activated" 2 "Fault Detected" 3 "Not Available" ;
VAL_ 2566799614 RearFogLights 0 "De-activated" 1 "Activated" 2 "Fault Detected" 3 "Not Available" ;
VAL_ 2566799614 TractorUndersideMntdWorkLights 0 "De-activated" 1 "Activated" 2 "Fault Detected" 3 "Not Available" ;
VAL_ 2566799614 TractorRearLowMountedWorkLights 0 "De-activated" 1 "Activated" 2 "Fault Detected" 3 "Not Available" ;
VAL_ 2566799614 TractorRearHighMountedWorkLights 0 "De-activated" 1 "Activated" 2 "Fault Detected" 3 "Not Available" ;
VAL_ 2566799614 TractorSideLowMountedWorkLights 0 "De-activated" 1 "Activated" 2 "Fault Detected" 3 "Not Available" ;
VAL_ 2566799614 TractorSideHighMountedWorkLights 0 "De-activated" 1 "Activated" 2 "Fault Detected" 3 "Not Available" ;
VAL_ 2566799614 TractorFrontLowMountedWorkLights 0 "De-activated" 1 "Activated" 2 "Fault Detected" 3 "Not Available" ;
VAL_ 2566799614 TractorFrntHighMountedWorkLights 0 "De-activated" 1 "Activated" 2 "Fault Detected" 3 "Not Available" ;
VAL_ 2566799614 ImplementOEMOption2Light 0 "De-activated" 1 "Activated" 2 "Fault Detected" 3 "Not Available" ;
VAL_ 2566799614 ImplementOEMOption1Light 0 "De-activated" 1 "Activated" 2 "Fault Detected" 3 "Not Available" ;
VAL_ 2566799614 ImplementRightFacingWorkLight 0 "De-activated" 1 "Activated" 2 "Fault Detected" 3 "Not Available" ;
VAL_ 2566799614 ImplementLeftForwardWorkLight 0 "De-activated" 1 "Activated" 2 "Fault Detected" 3 "Not Available" ;
VAL_ 2566799614 ImplementRightForwardWorkLight 0 "De-activated" 1 "Activated" 2 "Fault Detected" 3 "Not Available" ;
VAL_ 2566799614 ImplementLeftFacingWorkLight 0 "De-activated" 1 "Activated" 2 "Fault Detected" 3 "Not Available" ;
VAL_ 2566799614 ImplementRearWorkLight 0 "De-activated" 1 "Activated" 2 "Fault Detected" 3 "Not Available" ;
VAL_ 2365473278 RunningLightCommand 0 "De-activate" 1 "Activate" 2 "Reserved" 3 "Don't Care" ;
VAL_ 2365473278 AlternateBeamHeadLightCommand 0 "De-activate" 1 "Activate" 2 "Reserved" 3 "Don't Care" ;
VAL_ 2365473278 LowBeamHeadLightCommand 0 "De-activate" 1 "Activate" 2 "Reserved" 3 "Don't Care" ;
VAL_ 2365473278 HighBeamHeadLightCommand 0 "De-activate" 1 "Activate" 2 "Reserved" 3 "Don't Care" ;
VAL_ 2365473278 TractorFrontFogLightsCommand 0 "De-activate" 1 "Activate" 2 "Reserved" 3 "Don't Care" ;
VAL_ 2365473278 RotatingBeaconLightCommand 0 "De-activate" 1 "Activate" 2 "Reserved" 3 "Don't Care" ;
VAL_ 2365473278 RightTurnSignalLightsCommand 0 "De-activate" 1 "Activate" 2 "Reserved" 3 "Don't Care" ;
VAL_ 2365473278 LeftTurnSignalLightsCommand 0 "De-activate" 1 "Activate" 2 "Reserved" 3 "Don't Care" ;
VAL_ 2365473278 BackUpLightAndAlarmHornCommand 0 "De-activate" 1 "Activate" 2 "Reserved" 3 "Don't Care" ;
VAL_ 2365473278 CenterStopLightCommand 0 "De-activate" 1 "Activate" 2 "Reserved" 3 "Don't Care" ;
VAL_ 2365473278 RightStopLightCommand 0 "De-activate" 1 "Activate" 2 "Reserved" 3 "Don't Care" ;
VAL_ 2365473278 LeftStopLightCommand 0 "De-activate" 1 "Activate" 2 "Reserved" 3 "Don't Care" ;
VAL_ 2365473278 ImplementClearanceLightCommand 0 "De-activate" 1 "Activate" 2 "Reserved" 3 "Don't Care" ;
VAL_ 2365473278 TractorClearanceLightCommand 0 "De-activate" 1 "Activate" 2 "Reserved" 3 "Don't Care" ;
VAL_ 2365473278 ImplementMarkerLightCommand 0 "De-activate" 1 "Activate" 2 "Reserved" 3 "Don't Care" ;
VAL_ 2365473278 TractorMarkerLightCommand 0 "De-activate" 1 "Activate" 2 "Reserved" 3 "Don't Care" ;
VAL_ 2365473278 RearFogLightCommand 0 "De-activate" 1 "Activate" 2 "Reserved" 3 "Don't Care" ;
VAL_ 2365473278 TractorUnderSdeMntdWorkLightsCmd 0 "De-activate" 1 "Activate" 2 "Reserved" 3 "Don't Care" ;
VAL_ 2365473278 TractorRearLowMntdWorkLightsCmd 0 "De-activate" 1 "Activate" 2 "Reserved" 3 "Don't Care" ;
VAL_ 2365473278 TractorRearHghMntdWorkLightsCmd 0 "De-activate" 1 "Activate" 2 "Reserved" 3 "Don't Care" ;
VAL_ 2365473278 TractorSideLowMntdWorkLightsCmd 0 "De-activate" 1 "Activate" 2 "Reserved" 3 "Don't Care" ;
VAL_ 2365473278 TractorSideHghMntdWorkLightsCmd 0 "De-activate" 1 "Activate" 2 "Reserved" 3 "Don't Care" ;
VAL_ 2365473278 TractorFrntLowMntdWorkLightsCmd 0 "De-activate" 1 "Activate" 2 "Reserved" 3 "Don't Care" ;
VAL_ 2365473278 TractorFrntHghMntdWorkLightsCmd 0 "De-activate" 1 "Activate" 2 "Reserved" 3 "Don't Care" ;
VAL_ 2365473278 ImplementOEMOption2LightCommand 0 "De-activate" 1 "Activate" 2 "Reserved" 3 "Don't Care" ;
VAL_ 2365473278 ImplementOEMOption1LightCommand 0 "De-activate" 1 "Activate" 2 "Reserved" 3 "Don't Care" ;
VAL_ 2365473278 ImplementRightFacingWorkLightCmd 0 "De-activate" 1 "Activate" 2 "Reserved" 3 "Don't Care" ;
VAL_ 2365473278 ImplementLeftForwardWorkLightCmd 0 "De-activate" 1 "Activate" 2 "Reserved" 3 "Don't Care" ;
VAL_ 2365473278 LightingDataRequestCommand 0 "De-activate" 1 "Activate" 2 "Reserved" 3 "Don't Care" ;
VAL_ 2365473278 ImplementRightFrwdWorkLightCmd 0 "De-activate" 1 "Activate" 2 "Reserved" 3 "Don't Care" ;
VAL_ 2365473278 ImplementLeftFacingWorkLightCmd 0 "De-activate" 1 "Activate" 2 "Reserved" 3 "Don't Care" ;
VAL_ 2365473278 ImplementRearWorkLightCommand 0 "De-activate" 1 "Activate" 2 "Reserved" 3 "Don't Care" ;
VAL_ 2566802174 TrnsmCurrentRngDisplayBlankStat 0 "Not Blanked" 1 "Blanked" 2 "Error" 3 "Supported" ;
VAL_ 2566802174 TransmissionServiceIndicator 0 "Transmission Service Indicator is off" 1 "Transmission Service Indicator is on continuously" 2 "Transmission Service Indicator is flashing" 3 "Not available" ;
VAL_ 2566802174 TrnsmRqedRngDisplayBlankStat 0 "Inactive" 1 "Active" 2 "Reserved" 3 "Take no action" ;
VAL_ 2566802174 TrnsmRqedRngDisplayFlashStat 0 "Inactive" 1 "Active" 2 "Reserved" 3 "Take no action" ;
VAL_ 2566802174 TransmissionReadyForBrakeRelease 0 "Transmission Not Ready for Brake Release" 1 "Transmission Ready for Brake Release" 2 "Error" 3 "Not available" ;
VAL_ 2566802174 ActiveShiftConsoleIndicator 0 "Primary shift console is active" 1 "Secondary shift console is active" 2 "Reserved" 3 "Not available" ;
VAL_ 2566802174 TransmissionEngineCrankEnable 0 "Cranking disabled" 1 "Cranking enabled" 2 "Error" 3 "Not available" ;
VAL_ 2566802174 TransmissionShiftInhibitIndictr 0 "Inactive; shift is not inhibited" 1 "Active (on continuously); shift is inhibited" 2 "Active (flashing)" 3 "Take no action" ;
VAL_ 2566802174 TransmissionMode4Indicator 0 "Transmission Mode 4 not active" 1 "Transmission Mode 4 Active" 2 "Error" 3 "Not available" ;
VAL_ 2566802174 TransmissionMode3Indicator 0 "Transmission Mode 3 not active" 1 "Transmission Mode 3 Active" 2 "Error" 3 "Not available" ;
VAL_ 2566802174 TransmissionMode2Indicator 0 "Transmission Mode 2 not active" 1 "Transmission Mode 2 Active" 2 "Error" 3 "Not available" ;
VAL_ 2566802174 TransmissionMode1Indicator 0 "Transmission Mode 1 not active" 1 "Transmission Mode 1 Active" 2 "Error" 3 "Not available" ;
VAL_ 2566802174 TransmissionMode5Indicator 0 "Transmission Mode 5 not active" 1 "Transmission Mode 5 active" 2 "Error" 3 "Not available" ;
VAL_ 2566802174 TransmissionMode6Indicator 0 "Transmission Mode 6 not active" 1 "Transmission Mode 6 active" 2 "Error" 3 "Not available" ;
VAL_ 2566802174 TransmissionMode7Indicator 0 "Transmission Mode 7 not active" 1 "Transmission Mode 7 active" 2 "Error" 3 "Not available" ;
VAL_ 2566802174 TransmissionMode8Indicator 0 "Transmission Mode 8 not active" 1 "Transmission Mode 8 active" 2 "Error" 3 "Not available" ;
VAL_ 2566802174 TrnsmReverseGearShftInhbtStat 0 "Reverse gear shifts are currently allowed" 1 "Reverse gear shifts are currently inhibited" 2 "Error" 3 "Not Available" ;
VAL_ 2566802174 TransmissionWarningIndicator 0 "Transmission Warning Indicator is off" 1 "Transmission Warning Indicator is on continuously" 2 "Transmission Warning Indicator is flashing" 3 "Not available" ;
VAL_ 2566802174 TransmissionMode9Indicator 0 "Transmission Mode 9 not active" 1 "Transmission Mode 9 active" 2 "Error indicator" 3 "Not available" ;
VAL_ 2566802174 TransmissionMode10Indicator 0 "Transmission Mode 10 not active" 1 "Transmission Mode 10 active" 2 "Error indicator" 3 "Not available" ;
VAL_ 2566802174 TrnsmAirSupplyPressIndictr 0 "Normal Pressure Range" 1 "Low pressure" 2 "Very low pressure" 3 "No pressure" 4 "Over pressure" 5 "Not defined" 6 "Error indicator" 7 "Not available" ;
VAL_ 2566802174 TransmissionAutoNeutralState 0 "No request received - conditions are such that an Auto-Neutral request would be honored." 1 "No request received - conditions are such that an Auto-Neutral request would NOT be honored." 2 "Auto-Neutral request received - shift to Auto-Neutral state is pending." 3 "Auto-Neutral request received - shift to Auto-Neutral state has been achieved." 4 "Auto-Neutral request received - shift to Auto-Neutral state is inhibited." 5 "Reserved" 6 "Error" 7 "Not Available" ;
VAL_ 2566802174 TransmissionManualModeIndicator 0 "Transmission is not in a Manual Mode" 1 "Transmission is in a Manual Mode" 2 "Reserved" 3 "Not Available" ;
VAL_ 2566802686 RearBlackOutMarkerSelect 0 "Off" 1 "On" 2 "Reserved" 3 "Not Supported" ;
VAL_ 2566802686 FrontBlackOutMarkerLampSelect 0 "Off" 1 "On" 2 "Reserved" 3 "Not Supported" ;
VAL_ 2566802686 ConvoyLampSelect 0 "Off" 1 "On" 2 "Reserved" 3 "Not Supported" ;
VAL_ 2566802686 ConvoyDrivingLampSelect 0 "Off" 1 "On" 2 "Reserved" 3 "Not Supported" ;
VAL_ 2566802686 BlackOutBrakeStopLampSelect 0 "Off" 1 "On" 2 "Reserved" 3 "Not Supported" ;
VAL_ 2566802686 NightVisionIlluminatorSelect 0 "Off" 1 "On" 2 "Reserved" 3 "Not Supported" ;
VAL_ 2566802686 BlackOutWorkLampSelect 0 "Off" 1 "On" 2 "Reserved" 3 "Not Supported" ;
VAL_ 2566803198 PositionOfDoors 0 "At least 1 door is open" 1 "Closing last door" 2 "All doors closed" 14 "Error" 15 "Not available" ;
VAL_ 2566803198 RampWheelChairLiftPosition 0 "Inside bus" 1 "Outside bus" 2 "Error" 3 "Not available" ;
VAL_ 2566803198 Status2OfDoors 0 "all bus doors are disabled" 1 "at least 1 bus door enabled " 2 "error" 3 "not available" ;
VAL_ 2566803454 VDCInformationSignal 0 "Off" 1 "On" 2 "Reserved" 3 "Don't care/take no action" ;
VAL_ 2566803454 VDCFullyOperational 0 "Not fully operational" 1 "Fully operational" 2 "Reserved" 3 "Don't care/Take no action" ;
VAL_ 2566803454 VDCBrakeLightRequest 0 "Turn brake light not on" 1 "Turn brake light on" 2 "Reserved" 3 "Don't care/Take no action" ;
VAL_ 2566803454 ROPEngineControlActive 0 "ROP engine control passive but installed" 1 "ROP engine control active" 2 "Reserved" 3 "Don't care/Take no action" ;
VAL_ 2566803454 ROPBrakeControlActive 0 "ROP brake control passive but installed" 1 "ROP brake control active" 2 "Reserved" 3 "Don't care/Take no action" ;
VAL_ 2566803454 YCEngineControlActive 0 "YC engine control passive but installed" 1 "YC engine control active" 2 "Reserved" 3 "Don't care/Take no action" ;
VAL_ 2566803454 YCBrakeControlActive 0 "YC brake control passive but installed" 1 "YC brake control active" 2 "Reserved" 3 "Don't care/Take no action" ;
VAL_ 2566803454 TrailerVDCActive 0 "VDC passive, but installed" 1 "VDC active" 2 "Reserved" 3 "Not availble or not installed" ;
VAL_ 2566803966 ACCUsageDemand 0 "driver demand for not using" 1 "driver demand for using" 2 "reserved" 3 "don't care" ;
VAL_ 2566803966 RequestedACCDistanceMode 0 "Requested ACC Distance Mode #1" 1 "Requested ACC Distance Mode #2" 2 "Requested ACC Distance Mode #3" 3 "Requested ACC Distance Mode #4" 4 "Requested ACC Distance Mode #5" 5 "not defined" 6 "error condition" 7 "not available" ;
VAL_ 2566805246 AftSlctiveCtlytcRedOprtrIndcmntA 0 "Off" 1 "On solid" 2 "reserved for SAE assignment" 3 "reserved for SAE assignment" 4 "On fast blink (1 Hz)" 5 "reserved for SAE assignment" 6 "reserved for SAE assignment" 7 "not available" ;
VAL_ 2566805246 AftrtrtmntSCROprtrIndcmntSvrty 0 "Driver Warning" 1 "Inducement Level 1" 2 "Inducement Level 2" 3 "Inducement Level 3" 4 "Inducement Level 4" 5 "Inducement Level 5" 6 "Temporary Override of Inducement" 7 "Not Available / Not Supported" ;
VAL_ 2365478910 ElctrncShockAbsrbrCtrlMdeFrntAxl 0 "Normal operation dampers passive" 1 "Normal operation dampers active" 2 "Error" 3 "Not available" ;
VAL_ 2365478910 ElctrncShockAbsrbrCtrlMdeRearAxl 0 "Normal operation dampers passive" 1 "Normal operation dampers active" 2 "Error" 3 "Not available" ;
VAL_ 2365478910 ElctrncShckAbsrbrCtrlMdeLftTgAxl 0 "Normal operation dampers passive" 1 "Normal operation dampers active" 2 "Error" 3 "Not available" ;
VAL_ 2365479678 NominalLevelFrontAxle 0 "Level not specified" 1 "Normal Level 1" 2 "Normal Level 2" 3 "Normal Level 3" 4 "Preset Level" 5 "Customer Level" 6 "Upper Level" 7 "Lower Level" 8 "Level change stopped" 9 "Raising" 10 "Lowering" 14 "Error" 15 "Not available" ;
VAL_ 2365479678 NominalLevelRearAxle 0 "Level not specified" 1 "Normal Level 1" 2 "Normal Level 2" 3 "Normal Level 3" 4 "Preset Level" 5 "Customer Level" 6 "Upper Level" 7 "Lower Level" 8 "Level change stopped" 9 "Raising" 10 "Lowering" 14 "Error" 15 "Not available" ;
VAL_ 2365479678 BelowNominalLevelFrontAxle 0 "Not below" 1 "Below" 2 "Error" 3 "Not available" ;
VAL_ 2365479678 BelowNominalLevelRearAxle 0 "Not below" 1 "Below" 2 "Error" 3 "Not available" ;
VAL_ 2365479678 AboveNominalLevelFrontAxle 0 "Not above" 1 "Above" 2 "Error" 3 "Not available" ;
VAL_ 2365479678 AboveNominalLevelRearAxle 0 "Not above" 1 "Above" 2 "Error" 3 "Not available" ;
VAL_ 2365479678 LoweringControlModeFrontAxle 0 "Lowering not active" 1 "Lowering active" 2 "Error" 3 "Not available" ;
VAL_ 2365479678 LoweringControlModeRearAxle 0 "Lowering not active" 1 "Lowering active" 2 "Error" 3 "Not available" ;
VAL_ 2365479678 LiftingControlModeFrontAxle 0 "Lifting not active" 1 "Lifting active" 2 "Error" 3 "Not available" ;
VAL_ 2365479678 LiftingControlModeRearAxle 0 "Lifting not active" 1 "Lifting active" 2 "Error" 3 "Not available" ;
VAL_ 2365479678 KneelingInformation 0 "Not active" 1 "Lowering active" 2 "Kneeling level reached" 3 "Lifting active" 4 "Kneeling aborted" 14 "Error" 15 "Not available" ;
VAL_ 2365479678 LevelControlMode 0 "Normal operation" 1 "Traction help (load transfer)" 2 "Load fixing" 3 "Pressure ratio 1" 4 "Pressure ratio 2" 5 "Optimum traction 1" 6 "Optimum traction 2" 7 "Traction help" 8 "Exhausting bellow function" 9 "Air suspension control prohibited" 10 "Automatic air suspension control prohibited" 11 "Force to bumper level request is in effect" 14 "Error" 15 "Not available" ;
VAL_ 2365479678 SecurityDevice 0 "not active" 1 "active" 2 "error" 3 "not available" ;
VAL_ 2365479678 VehicleMotionInhibit 0 "Vehicle may be moved" 1 "Vehicle motion is inhibited" 2 "Error" 3 "Not available" ;
VAL_ 2365479678 DoorRelease 0 "Doors may not be opened" 1 "Doors may be opened" 2 "Error" 3 "Not available" ;
VAL_ 2365479678 LiftAxle1Position 0 "Lift axle position down / tag axle laden" 1 "Lift axle position up / tag axle unladen" 2 "Error" 3 "Not available" ;
VAL_ 2365479678 FrontAxleInBumperRange 0 "Actual level out of bumper range" 1 "Actual level within bumper range" 2 "Error" 3 "Not available" ;
VAL_ 2365479678 RearAxleInBumperRange 0 "Actual level out of bumper range" 1 "Actual level within bumper range" 2 "Error" 3 "Not available" ;
VAL_ 2365479678 LiftAxle2Position 0 "Lift axle position down / tag axle laden" 1 "Lift axle position up / tag axle unladen" 2 "Error" 3 "Not available" ;
VAL_ 2365479678 SuspensionRemoteControl1 0 "not active" 1 "active" 2 "error" 3 "not available" ;
VAL_ 2365479678 SuspensionRemoteControl2 0 "not active" 1 "active" 2 "error" 3 "not available" ;
VAL_ 2365479678 AllowLevelCtrlDuringBrkngStatus 0 "Deactivated" 1 "Activated" 2 "Reserved" 3 "Don't care/take no action" ;
VAL_ 2365479678 SpeedDependantLevelControlStatus 0 "Inactive" 1 "Active" 2 "Reserved" 3 "Don't care/take no action" ;
VAL_ 2365479678 SuspensionCtrlRefusalInformation 0 "Actual request not refused" 1 "Axle load limit reached  (load transfer)" 2 "Would exceed axle load limit (tag axle)" 3 "Bogie differential not locked" 4 "Above speed limit" 5 "Below speed limit" 6 "General reject" 7 "Requested level not available" 14 "Error" 15 "Not available" ;
VAL_ 2365479678 MemoryLevel 0 "No memory level" 1 "Memory level 1 selected " 2 "Memory level 2 selected" 3 "Memory level 3 selected" 4 "Memory level 4 selected" 5 "Memory level 5 selected" 6 "reserved" 7 "reserved" 8 "reserved" 9 "Memory level  1 stored" 10 "Memory level  2 stored" 11 "Memory level  3 stored" 12 "Memory level  4 stored" 13 "Memory level  5 stored" 14 "Error indicator" 15 "not available" ;
VAL_ 2566806526 LaneTrackingStatusRightSide 0 "Not Tracking Right side" 1 "Tracking Right side" 2 "Reserved" 3 "Don't Care/take no action" ;
VAL_ 2566806526 LaneTrackingStatusLeftSide 0 "Not Tracking Left side" 1 "Tracking Left side" 2 "Reserved" 3 "Don't care/Take no action" ;
VAL_ 2566806526 LaneDePrtureIndicationEnblStatus 0 "Lane Departure indication disabled" 1 "Lane Departure Indication enabled " 2 "Reserved" 3 "Not Used" ;
VAL_ 2566806526 DrvrAlertnessWarningSystemState 0 "System installed but disabled" 1 "Initializing" 2 "System temporarily not available" 3 "System available" 4 "System monitoring driver behavior" 7 "Not Available / Not Installed" ;
VAL_ 2566806526 LeftWheelLaneDepartureDistance 251 "Greater than 125 cm / Not in range" 252 "Lane marker not reliable" 253 "Reserved" 254 "Error" 255 "Not available" ;
VAL_ 2566806526 RightWheelLaneDepartureDistance 251 "not in range" 252 "not reliable" 253 "reserved / not used" 254 "error" 255 "not available or not installed" ;
VAL_ 2566806526 LaneDepartureWarningSystemState 0 "System is not ready" 1 "System is temporarily not available" 2 "System is deactivated by driver" 3 "System is ready" 4 "Active warning suppressed by operator behavior" 5 "System is warning lane departure" 14 "Error" 15 "Not available" ;
VAL_ 2566806526 ForwardLaneImagerStatus 0 "Imager fully operational" 1 "Imager warming up / initializing" 2 "Imager partially blocked / partially blind" 3 "Imager fully blocked / fully blind" 4 "Imager misaligned" 14 "Error" 15 "Not Available" ;
VAL_ 2566809342 BatteryMainSwitchHoldState 0 "Battery main switch not held" 1 "Battery main switch held" 2 "Reserved" 3 "Don't care/take no action" ;
VAL_ 2566809854 HydrOilFilterRestrictionSwitch 0 "No restriction" 1 "Restriction exists on oil filter" 2 "Error" 3 "Not available" ;
VAL_ 2566809854 WinchOilPressureSwitch 0 "NOT OK - Oil pressure is too low" 1 "OK - Oil pressure is above minimum" 2 "Error - Switch state cannot be determined" 3 "Not Available" ;
VAL_ 2566810366 EngineOilPrimingPumpSwitch 0 "Off" 1 "On" 2 "Error" 3 "Not available or not installed" ;
VAL_ 2566810366 EngineOilPrimingState 0 "Not sufficiently lubricated" 1 "Sufficiently lubricated" 2 "Unable to determine if sufficiently lubricated" 3 "Not available or not installed" ;
VAL_ 2566810366 EngineOilPreHeatedState 0 "Not sufficiently pre-heated" 1 "Sufficiently pre-heated" 2 "Unable to determine if engine oil is pre-heated sufficiently" 3 "Not available or not installed" ;
VAL_ 2566810366 EngineCoolantPreHeatedState 0 "Not sufficiently pre-heated" 1 "Sufficiently pre-heated" 2 "Unable to determine engine coolant pre-heated sufficiently" 3 "Not available or not installed" ;
VAL_ 2566810366 EngineVentilationStatus 0 "Sufficiently vented" 1 "Ventilation needed" 2 "Ventilation delay" 3 "Currently venting" 4 "Reserved for SAE assignment" 5 "Reserved for SAE assignment " 6 "Not able to determine if sufficiently vented" 7 "Not available or not installed" ;
VAL_ 2566810366 FuelPumpPrimerStatus 0 "Off" 1 "On" 2 "Error" 3 "Unavailable" ;
VAL_ 2365484286 Driver1WorkingState 0 "Rest" 1 "Driver available" 2 "Work" 3 "Drive" 6 "Error" 7 "Not available" ;
VAL_ 2365484286 Driver2WorkingState 0 "Rest" 1 "Driver available" 2 "Work" 3 "Drive" 6 "Error" 7 "Not available" ;
VAL_ 2365484286 VehicleMotion 0 "Vehicle motion not detected" 1 "Vehicle motion detected" 2 "Error" 3 "Not available" ;
VAL_ 2365484286 Driver1TimeRelatedStates 0 "Normal/No limits reached" 1 "Limit #1 - 15 min before 4 ,5 h" 2 "Limit #2 - 4 ,5 h reached" 3 "Limit #3 - 15 min before 9 h" 4 "Limit #4 - 9 h reached" 5 "Limit #5 - 15 min before 16 h" 6 "Limit #6 - 16 h reached" 13 "Other" 14 "Error" 15 "Not available" ;
VAL_ 2365484286 DriverCard_Driver1 0 "Driver card not present" 1 "Driver card present" 2 "Error" 3 "Not available" ;
VAL_ 2365484286 VehicleOverspeed 0 "No overspeed" 1 "Overspeed" 2 "Error" 3 "Not available" ;
VAL_ 2365484286 Driver2TimeRelatedStates 0 "Normal/No limits reached" 1 "Limit #1 - 15 min before 4 ,5 h" 2 "Limit #2 - 4 ,5 h reached" 3 "Limit #3 - 15 min before 9 h" 4 "Limit #4 - 9 h reached" 5 "Limit #5 - 15 min before 16 h" 6 "Limit #6 - 16 h reached" 13 "Other" 14 "Error" 15 "Not available" ;
VAL_ 2365484286 DriverCard_Driver2 0 "Driver card not present" 1 "Driver card present" 2 "Error" 3 "Not available" ;
VAL_ 2365484286 SystemEvent 0 "No tachograph event" 1 "Tachograph event" 2 "Error" 3 "Not available" ;
VAL_ 2365484286 HandlingInformation 0 "No handling information" 1 "Handling information" 2 "Error" 3 "Not available" ;
VAL_ 2365484286 TachographPerformance 0 "Normal performance" 1 "Performance analysis" 2 "Error" 3 "Not available" ;
VAL_ 2365484286 DirectionIndicator 0 "Forward" 1 "Reverse" 2 "Error" 3 "Not Available" ;
VAL_ 2566811134 AuxiliaryHeaterMode 0 "Heater not active" 1 "Off due to ADR per European Regulations for Transport of hazardous materials" 2 "Economy mode" 3 "Normal mode" 4 "Heater pump up-keep" 5 "Heater Starting" 6 "Heater Stopping" 7 "Diagnose Active" 8 "Heater Locked" 14 "Error" 15 "Not available" ;
VAL_ 2566811134 AuxiliaryHeaterWaterPumpStatus 0 "Water Pump is not running" 1 "Water Pump is  running" 2 "Reserved" 3 "Not available" ;
VAL_ 2566811134 CabVentilation 0 "Cab not ventilated" 1 "Cab is ventilated" 2 "Reserved" 3 "Not available" ;
VAL_ 2566811134 EngineHeatingZone 0 "Engine heating zone off" 1 "Engine heating zone on" 2 "Reserved" 3 "Not available" ;
VAL_ 2566811134 CabHeatingZone 0 "Cab heating zone off" 1 "Cab heating zone on" 2 "Reserved" 3 "Not available" ;
VAL_ 2566811134 ADRCompliantHeaterInstallation 0 "Heater installation is not ADR compliant" 1 "Heater installation is ADR compliant" 2 "Error" 3 "Not Available" ;
VAL_ 2432593918 AdaptiveCruiseControlMode 0 "Off (Standby, enabled, ready for activation)" 1 "Speed control active" 2 "Distance control active" 3 "Overtake mode" 4 "Hold mode" 5 "Finish mode" 6 "Disabled or error condition" 7 "Not available/not valid" ;
VAL_ 2432593918 AdaptiveCruiseCtrlSetDistMode 0 "ACC Distance mode #1 (largest distance)" 1 "ACC Distance mode #2" 2 "ACC Distance mode #3" 3 "ACC Distance mode #4" 4 "ACC Distance mode #5 (shortest distance)" 5 "Conventional cruise control mode" 6 "Error condition" 7 "Not available/not valid" ;
VAL_ 2432593918 ACCTargetDetected 0 "No targets detected" 1 "Target detected" 2 "Reserved" 3 "Take no action" ;
VAL_ 2432593918 ACCSystemShutoffWarning 0 "ACC SSOW Not Active" 1 "ACC SSOW Active" 2 "Reserved" 3 "Take no action" ;
VAL_ 2432593918 ACCDistanceAlertSignal 0 "ACC DAS Not Active" 1 "ACC DAS Active" 2 "Reserved" 3 "Take no action" ;
VAL_ 2432593918 ForwardCollisionWarning 0 "No warning" 1 "Collision is imminent" 2 "Error indicator" 3 "not available" ;
VAL_ 2365485566 LEDDisplayData2 1 "On-grade 'A' LED on" 2 "On-grade 'B' LED on" 4 "On-grade 'C' LED on" 8 "Up LED on" 16 "Down LED on" 32 "Left LED on" 64 "Right LED on" 128 "Low Coarse" 129 "Low Medium/Coarse" 130 "Low Medium" 131 "Low Medium/Fine" 132 "Low Fine" 144 "On Grade" 145 "High Fine" 146 "High Medium/Fine" 147 "High Medium" 148 "High Medium/Coarse" 149 "High Coarse" 159 "No data (i.e. no laser strikes)" 254 "Error" 255 "Not Available" ;
VAL_ 2365485566 LaserTracerInformation 1 "Laser power is on" 2 "Laser is ready" 4 "Valid target (1 = yes)" 8 "Previous pass (1 = yes)" 16 "Stringline (1 = yes)" 32 "Curb (1 = yes)" ;
VAL_ 2365485822 BladeControlMode 0 "Manual mode" 1 "Automatic mode" 2 "Inactive automatic mode" ;
VAL_ 2365485822 BladeControlModeLeft 0 "Manual" 1 "Auto " 2 "Inactive Auto" 14 "Error" 15 "Not Available" ;
VAL_ 2365485822 BladeControlModeRight 0 "Manual" 1 "Auto " 2 "Inactive Auto" 14 "Error" 15 "Not Available" ;
VAL_ 2365485822 LandLevelingSystemEnableStatus 0 "Disabled" 1 "Enabled" 2 "Error" 3 "Not available / Not installed" ;
VAL_ 2365486334 ModifyLevelingSystemSetPoint 65025 "indicates Stop modifying the set point" 65027 "indicates Raise the current set point by 5 mm" 65041 "indicates Lower the current set point by 5 mm" 65043 "indicates Search for laser or target" 65045 "indicates go to the Park position" 65047 "indicates go to the Bench position" ;
VAL_ 2365486590 LaserReceiverType 0 "Reserved " 1 "Linear Laser Receiver" 2 "1 Meter Survey Receiver" 3 "2 Meter Survey Receiver" 4 "2.5 Meter Survey Receiver" ;
VAL_ 2432595710 LEDDisplayData1 2 "High Coarse LED on" 4 "High Fine LED on" 8 "On-grade LED on" 16 "Low Fine LED on" 32 "Low Coarse LED on" 128 "Low Coarse" 129 "Low Medium/Coarse" 130 "Low Medium" 131 "Low Medium/Fine" 132 "Low Fine" 144 "On Grade" 145 "High Fine" 146 "High Medium/Fine" 147 "High Medium" 148 "High Medium/Coarse" 149 "High Coarse" 159 "No data (i.e. no laser strikes)" 254 "Error" 255 "Not Available" ;
VAL_ 2432595710 LEDDisplayModeControl 0 "Center On-Grade Display Mode 1 ( 5 CHANNEL )" 1 "Offset On-Grade Display Mode " 2 "Center On-Grade Display Mode 2 ( 7 CHANNEL )" 15 "Not Available or Not Applicable" ;
VAL_ 2432595710 LEDDisplayDeadbandControl 0 "+/- 4.5 mm (0.015 feet, 0.18 inches)" 1 "+/- 12 mm (0.040 feet, 0.45 inches)" 2 "+/- 24 mm (0.080 feet, 0.96 inches)" 3 "+/- 5 mm (0.017 feet, 0.2 inches)" 4 "+/- 1 mm (0.003 feet, 0.04 inches)" 15 "Not Available or Not applicable" ;
VAL_ 2432595710 LEDPatternControl 0 "5 Channel" 1 "Offset" 2 "7 Channel" 15 "Not Available" ;
VAL_ 2432595710 DisplayDeadbands 0 "Narrow = +/- 4.5mm" 1 "Standard = +/- 12mm" 2 "Wide = +/- 24mm" 15 "Not Available" ;
VAL_ 2633922814 SteerChannelMode 0 "Maintain" 1 "Inflate" 2 "Deflate" 3 "Confirm" 4 "Inflate Wait" 5 "Deflate Wait" 6 "Pressure Check" 14 "Error Condition" 15 "Not available" ;
VAL_ 2633922814 TrailerTagChannelMode 0 "Maintain" 1 "Inflate" 2 "Deflate" 3 "Confirm" 4 "Inflate Wait" 5 "Deflate Wait" 6 "Pressure Check" 14 "Error Condition" 15 "Not available" ;
VAL_ 2633922814 DriveChannelMode 0 "Maintain" 1 "Inflate" 2 "Deflate" 3 "Confirm" 4 "Inflate Wait" 5 "Deflate Wait" 6 "Pressure Check" 14 "Error Condition" 15 "Not available" ;
VAL_ 2633922814 PCUDriveSolenoidStatus 0 "Off" 1 "On" 2 "Error" 3 "Not available" ;
VAL_ 2633922814 PCUSteerSolenoidStatus 0 "Off" 1 "On" 2 "Error" 3 "Not available" ;
VAL_ 2633922814 TirePressureSupplySwitchStatus 0 "Off" 1 "On" 2 "Error" 3 "Not available" ;
VAL_ 2633922814 PCUDeflateSolenoidStatus 0 "Off" 1 "On" 2 "Error" 3 "Not available" ;
VAL_ 2633922814 PCUControlSolenoidStatus 0 "Off" 1 "On" 2 "Error" 3 "Not available" ;
VAL_ 2633922814 PCUSupplySolenoidStatus 0 "Off" 1 "On" 2 "Error" 3 "Not available" ;
VAL_ 2633922814 PCUTrailer_TagOrPushSolenoidStat 0 "Off" 1 "On" 2 "Error" 3 "Not available" ;
